VERSION ""

NS_ :

BS_:

BU_: ADCS_FD3 GW_FD2 BDCS CDCS GW_FD3 GW_FD4 GW_FD5 GW_FD6 GW_FD1 MCU FMCU EPS1 IDB1 ACU ICU TBOX IDB2 EPS2 RCU1 PDCU DDCU PLSD DLSD PDCS1 BTM GW_FD8 HNS2 HNS1 EMS BMS EDU RCU2

BO_ 143 ADCS_Fr11_08F_APA1: 32 ADCS_FD3
 SG_ ADCS11_PA_GearReq : 0|1@0+ (1,0) [0|1] "NoUnit" TBOX,GW_FD5,GW_FD1,PDCS1
 SG_ ADCS11_PA_GearPosReqVail : 1|1@0+ (1,0) [0|1] "NoUnit" TBOX,GW_FD5,GW_FD1,PDCS1
 SG_ ADCS11_PA_prefillReq : 2|1@0+ (1,0) [0|1] "NoUnit" TBOX,GW_FD8,GW_FD5,IDB1,IDB2,EPS2,RCU1
 SG_ ADCS11_PA_GearPosReq : 5|3@0+ (1,0) [0|7] "NoUnit" TBOX,GW_FD5,GW_FD1,PDCS1
 SG_ ADCS11_PA_BrakemodeReq : 7|2@0+ (1,0) [0|3] "NoUnit" TBOX,GW_FD8,GW_FD5,IDB1,IDB2,EPS2,RCU1
 SG_ ADCS11_PA_EpbReq : 17|2@0+ (1,0) [0|3] "NoUnit" TBOX,GW_FD8,GW_FD5,IDB1,IDB2,EPS2,RCU1
 SG_ ADCS11_PA_lampreq : 19|2@0+ (1,0) [0|3] "NoUnit" TBOX,GW_FD5,GW_FD2,BDCS
 SG_ ADCS11_PA_StopDistance : 15|12@0+ (0.01,0) [0|40.95] "m" TBOX,GW_FD8,GW_FD5,IDB1,IDB2,EPS2,RCU1
 SG_ ADCS11_PA_StopDistanceValid : 159|1@0+ (1,0) [0|1] "NoUnit" TBOX,GW_FD5,IDB1,RCU1
 SG_ ADCS11_Parking_WorkSts : 27|4@0+ (1,0) [0|15] "NoUnit" IDB1,EPS1,IDB2,EPS2,PDCS1,RCU1,BDCS,CDCS,TBOX,GW_FD8,GW_FD5,FMCU,GW_FD4,BTM,GW_FD1,ICU,GW_FD2,MCU
 SG_ ADCS11_PA_Recover : 29|1@0+ (1,0) [0|1] "NoUnit" IDB1,IDB2,EPS2,RCU1,CDCS,TBOX,GW_FD8,GW_FD5,GW_FD4,BTM,GW_FD2
 SG_ ADCS11_RPA_RemoteParkAppStartReq : 28|1@0+ (1,0) [0|1] "NoUnit" TBOX,GW_FD5,GW_FD4,BTM,GW_FD2,CDCS
 SG_ ADCS11_TurnLampReq : 31|2@0+ (1,0) [0|3] "NoUnit" TBOX,GW_FD5,BTM,GW_FD2
 SG_ ADCS11_SetPathwayWorkSts : 39|2@0+ (1,0) [0|3] "NoUnit" TBOX,GW_FD5,GW_FD4,CDCS
 SG_ ADCS11_PA_EPSAngleReq : 37|14@0+ (0.1,-720) [-720|720] "degree" TBOX,GW_FD8,GW_FD5,EPS1,EPS2
 SG_ ADCS11_HPAGuideSts : 54|3@0+ (1,0) [0|7] "NoUnit" TBOX,GW_FD5,GW_FD4,CDCS
 SG_ ADCS11_PA_IDBControlReq : 129|2@0+ (1,0) [0|3] "NoUnit" TBOX,GW_FD8,GW_FD5,IDB1,IDB2,EPS2,RCU1
 SG_ ADCS11_MsgCounter0 : 51|4@0+ (1,0) [0|15] "NoUnit" TBOX,GW_FD8,GW_FD5,IDB1,EPS1,EPS2,GW_FD1,PDCS1,RCU1
 SG_ ADCS11_Checksum0 : 63|8@0+ (1,0) [0|255] "NoUnit" TBOX,GW_FD8,GW_FD5,IDB1,EPS1,EPS2,GW_FD1,PDCS1,RCU1
 SG_ ADCS11_HPA_WorkSts : 74|3@0+ (1,0) [0|7] "NoUnit" TBOX,GW_FD5,GW_FD4,CDCS
 SG_ ADCS11_PA_IDBControlReqV : 75|1@0+ (1,0) [0|1] "NoUnit" TBOX,GW_FD8,GW_FD5,IDB1,IDB2,EPS2,RCU1
 SG_ ADCS11_PA_TarDecel : 71|12@0+ (0.01,-20.48) [-20.48|20.46] "m/s^2" TBOX,GW_FD8,GW_FD5,IDB1,IDB2,EPS2,GW_FD1,PDCS1,RCU1
 SG_ ADCS11_PA_EPSAngleReqSt : 96|1@0+ (1,0) [0|1] "NoUnit" TBOX,GW_FD8,GW_FD5,EPS1,EPS2
 SG_ ADCS11_PA_EPSAngleReqV : 97|1@0+ (1,0) [0|1] "NoUnit" TBOX,GW_FD8,GW_FD5,EPS1,EPS2
 SG_ ADCS11_PrkngFctnModeReq : 100|3@0+ (1,0) [0|7] "NoUnit" TBOX,GW_FD8,GW_FD5,EPS2
 SG_ ADCS11_HPAPathlearning_WorkSts : 103|3@0+ (1,0) [0|7] "NoUnit" TBOX,GW_FD5,GW_FD4,CDCS
 SG_ ADCS11_HPAPathwaytoCloud_WorkSts : 106|3@0+ (1,0) [0|7] "NoUnit" TBOX,GW_FD5,GW_FD4,CDCS
 SG_ ADCS11_TrackreverseWorkSts : 109|3@0+ (1,0) [0|7] "NoUnit" TBOX,GW_FD5,GW_FD4,CDCS
 SG_ ADCS11_Currentgear : 111|2@0+ (1,0) [0|3] "NoUnit" TBOX,GW_FD5,GW_FD4,BTM,GW_FD2,CDCS
 SG_ ADCS11_PA_PAMaxSpd : 119|16@0+ (0.015625,0) [0|512] "km/h" TBOX,GW_FD8,GW_FD5,IDB1,IDB2,EPS2,GW_FD1,PDCS1,RCU1
 SG_ ADCS11_PA_Pause_Recover : 137|2@0+ (1,0) [0|3] "NoUnit" TBOX,GW_FD5,GW_FD4,CDCS
 SG_ ADCS11_PA_ParkingFnMd : 143|2@0+ (1,0) [0|3] "NoUnit" TBOX,GW_FD5,IDB1,RCU1
 SG_ ADCS11_PA_TarDecelreq : 141|1@0+ (1,0) [0|1] "NoUnit" TBOX,GW_FD5,IDB1,RCU1
 SG_ ADCS11_HPA_BacktoEntrance : 138|1@0+ (1,0) [0|1] "NoUnit" TBOX,GW_FD5,GW_FD4,CDCS
 SG_ ADCS11_HPA_BacktoStart : 139|1@0+ (1,0) [0|1] "NoUnit" TBOX,GW_FD5,GW_FD4,CDCS
 SG_ ADCS11_PA_TorqReq : 134|1@0+ (1,0) [0|1] "NoUnit" TBOX,GW_FD5,GW_FD1,PDCS1
 SG_ ADCS11_PA_TorqReqValue : 156|13@0+ (1,-1023) [-1023|1023] "Nm" TBOX,GW_FD5,GW_FD1,PDCS1
 SG_ ADCS11_PA_TorqReqValidity : 135|1@0+ (1,0) [0|1] "NoUnit" TBOX,GW_FD5,GW_FD1,PDCS1
 SG_ ADCS11_PA_screenReq : 147|4@0+ (1,0) [0|15] "NoUnit" TBOX,GW_FD5,GW_FD4,CDCS
 SG_ ADCS11_APA_RemoteStartReq : 130|1@0+ (1,0) [0|1] "NoUnit" TBOX,GW_FD5,GW_FD2,BDCS
 SG_ ADCS11_APA_RemoteShutdownReq : 131|1@0+ (1,0) [0|1] "NoUnit" TBOX,GW_FD5,GW_FD2,BDCS
 SG_ ADCS11_MirrorFoldrequest : 133|2@0+ (1,0) [0|3] "NoUnit" TBOX,GW_FD5,GW_FD2,BDCS
 SG_ ADCS11_APA_FLWindowsCtrl : 87|3@0+ (1,0) [0|7] "NoUnit" TBOX,GW_FD5,GW_FD2,BDCS
 SG_ ADCS11_APA_RemoteLockCtrl : 84|2@0+ (1,0) [0|3] "NoUnit" TBOX,GW_FD5,GW_FD2,BDCS
 SG_ ADCS11_APA_FRWindowsCtrl : 82|3@0+ (1,0) [0|7] "NoUnit" TBOX,GW_FD5,GW_FD2,BDCS
 SG_ ADCS11_APA_RLWindowsCtrl : 95|3@0+ (1,0) [0|7] "NoUnit" TBOX,GW_FD5,GW_FD2,BDCS
 SG_ ADCS11_APA_RRWindowsCtrl : 92|3@0+ (1,0) [0|7] "NoUnit" TBOX,GW_FD5,GW_FD2,BDCS
 SG_ ADCS11_APA_requestMirrorFoldSt : 89|2@0+ (1,0) [0|3] "NoUnit" TBOX,GW_FD5,GW_FD2,BDCS
 SG_ ADCS11_PA_StopReq : 158|1@0+ (1,0) [0|1] "NoUnit" TBOX,GW_FD5,IDB1,GW_FD4,RCU1,CDCS
 SG_ ADCS11_HPA_PathlearningSt : 149|2@0+ (1,0) [0|3] "NoUnit" TBOX,GW_FD5,GW_FD4,CDCS
 SG_ ADCS11_HPA_Path_exist : 151|2@0+ (1,0) [0|3] "NoUnit" TBOX,GW_FD5,GW_FD4,CDCS
 SG_ ADCS11_HPA_Pathavailable_ID1 : 223|8@0+ (1,0) [0|255] "NoUnit" TBOX,GW_FD5,GW_FD4,CDCS
 SG_ ADCS11_HPA_Pathavailable_ID2 : 175|8@0+ (1,0) [0|255] "NoUnit" TBOX,GW_FD5,GW_FD4,CDCS
 SG_ ADCS11_HPA_distance : 183|12@0+ (1,0) [0|4095] "NoUnit" TBOX,GW_FD5,GW_FD4,CDCS
 SG_ ADCS11_Parkingtimeremaining : 185|10@0+ (1,0) [0|1023] "NoUnit" TBOX,GW_FD5,GW_FD4,CDCS
 SG_ ADCS11_PA_PickSt : 157|1@0+ (1,0) [0|1] "NoUnit" TBOX,GW_FD5
 SG_ ADCS11_NNS_distance : 207|16@0+ (1,0) [0|65535] "NoUnit" TBOX,GW_FD5,GW_FD4,CDCS
 SG_ ADCS11_PA_IDB_TorqReqValue : 243|12@0+ (0.5,-1023) [-1023|1023] "Nm" TBOX,GW_FD5,IDB1,RCU1
 SG_ ADCS11_HighBeam : 225|2@0+ (1,0) [0|3] "NoUnit" TBOX,GW_FD5,GW_FD2,BDCS
 SG_ ADCS11_LowBeam : 231|2@0+ (1,0) [0|3] "NoUnit" TBOX,GW_FD5,GW_FD2,BDCS
 SG_ ADCS11_ReqPwmode : 227|2@0+ (1,0) [0|3] "NoUnit" TBOX,GW_FD5,GW_FD2,BDCS
 SG_ ADCS11_SecuritySts : 229|2@0+ (1,0) [0|3] "NoUnit" TBOX,GW_FD5,GW_FD2,BDCS
 SG_ ADCS11_PA_IDB_TorqReqValidity : 244|1@0+ (1,0) [0|1] "NoUnit" TBOX,GW_FD5,IDB1,RCU1
 SG_ ADCS11_HPA_learnpathdistance : 239|10@0+ (1,0) [0|1023] "NoUnit" GW_FD4,CDCS

BO_ 142 ADCS_Fr02_08E: 16 ADCS_FD3
 SG_ ADCS2_ADAS_EPSAngleReqSt : 0|1@0+ (1,0) [0|1] "NoUnit" EPS1,EPS2
 SG_ ADCS2_EPS_LDPState : 3|3@0+ (1,0) [0|7] "NoUnit" EPS1,EPS2,ICU,CDCS
 SG_ ADCS2_NNP_SystemFaultStatus : 6|3@0+ (1,0) [0|7] "NoUnit" EPS1,GW_FD4,EPS2,CDCS
 SG_ ADCS2_ADAS_EPSLateralCtrlType : 14|4@0+ (1,0) [0|15] "NoUnit" EPS1,EPS2
 SG_ ADCS_Pilot_SystemFaultStatus : 10|3@0+ (1,0) [0|7] "NoUnit" EPS1,EPS2
 SG_ ADCS2_ADSDriving_mode : 31|2@0+ (1,0) [0|3] "NoUnit" GW_FD4,CDCS
 SG_ ADCS2_ADAS_EPSAngleReq : 29|14@0+ (0.1,-720) [-720|720] "degree" EPS1,EPS2
 SG_ ADCS2_ADAS_IHBCSysState : 42|3@0+ (1,0) [0|7] "NoUnit" PDCU,GW_FD4,ICU,GW_FD2,BDCS,DDCU,CDCS
 SG_ ADCS2_ALCDirection : 45|3@0+ (1,0) [0|7] "NoUnit" GW_FD4,ICU,GW_FD2,BDCS,CDCS
 SG_ ADCS2_MsgCounter0 : 51|4@0+ (1,0) [0|15] "NoUnit" HNS2,HNS1,EPS1,EPS2
 SG_ ADCS2_EPS_ELKState : 54|3@0+ (1,0) [0|7] "NoUnit" EPS1,GW_FD4,EPS2,ICU,CDCS
 SG_ ADCS2_Checksum0 : 63|8@0+ (1,0) [0|255] "NoUnit" HNS2,HNS1,EPS1,EPS2
 SG_ ADCS2_AEB_JerkReq : 79|1@0+ (1,0) [0|1] "NoUnit" IDB1,GW_FD4,IDB2,EPS2,RCU1,CDCS
 SG_ ADCS2_AEBPrefillReq : 78|1@0+ (1,0) [0|1] "NoUnit" IDB1,IDB2,EPS2,RCU1
 SG_ ADCS2_AEB_DBSLevel : 77|2@0+ (1,0) [0|3] "NoUnit" IDB1,IDB2,EPS2,RCU1
 SG_ ADCS2_AEBPartialBrake : 75|1@0+ (1,0) [0|1] "NoUnit" ACU,IDB1,GW_FD4,IDB2,EPS2,ICU,RCU1,CDCS
 SG_ ADCS2_AEBFullBrake : 74|1@0+ (1,0) [0|1] "NoUnit" ACU,IDB1,GW_FD4,IDB2,EPS2,GW_FD1,ICU,PDCS1,RCU1,CDCS
 SG_ ADCS2_AEBVehicleHoldReq : 73|1@0+ (1,0) [0|1] "NoUnit" IDB1,IDB2,EPS2,RCU1
 SG_ ADCS2_AEBTargetDeceleration : 87|8@0+ (0.1,-12.7) [-12.7|12.8] "m/s^2" IDB1,IDB2,EPS2,RCU1
 SG_ ADCS2_longitudCtrlType : 98|3@0+ (1,0) [0|7] "NoUnit" HNS2,HNS1,IDB1,IDB2,EPS2,RCU1
 SG_ ADCS2_LongitudCtrlDecToStopReq : 99|1@0+ (1,0) [0|1] "NoUnit" IDB1,IDB2,EPS2,RCU1
 SG_ ADCS2_LongitudCtrlDriveOff : 100|1@0+ (1,0) [0|1] "NoUnit" IDB1,IDB2,EPS2,RCU1
 SG_ ADCS2_AEB_JerkLevel : 102|2@0+ (1,0) [0|3] "NoUnit" IDB1,IDB2,EPS2,RCU1
 SG_ ADCS2_LongitudCtrlTargetAccel : 111|11@0+ (0.01,-10.23) [-10.23|10.24] "m/s^2" IDB1,IDB2,EPS2,RCU1
 SG_ ADCS2_LongitudCtrlAccelCtrlReq : 116|1@0+ (1,0) [0|1] "NoUnit" IDB1,IDB2,EPS2,GW_FD1,PDCS1,RCU1

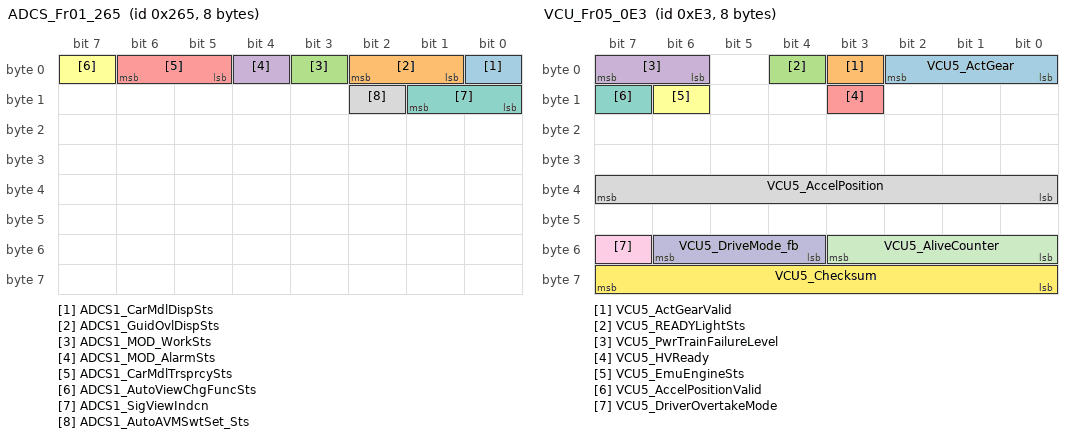
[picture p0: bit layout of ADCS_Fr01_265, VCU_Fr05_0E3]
BO_ 613 ADCS_Fr01_265: 8 ADCS_FD3
 SG_ ADCS1_CarMdlDispSts : 0|1@0+ (1,0) [0|1] "NoUnit" GW_FD4,CDCS
 SG_ ADCS1_GuidOvlDispSts : 2|2@0+ (1,0) [0|3] "NoUnit" GW_FD4,CDCS
 SG_ ADCS1_MOD_WorkSts : 3|1@0+ (1,0) [0|1] "NoUnit" GW_FD4,CDCS
 SG_ ADCS1_MOD_AlarmSts : 4|1@0+ (1,0) [0|1] "NoUnit" GW_FD4,CDCS
 SG_ ADCS1_CarMdlTrsprcySts : 6|2@0+ (1,0) [0|3] "NoUnit" GW_FD4,CDCS
 SG_ ADCS1_AutoViewChgFuncSts : 7|1@0+ (1,0) [0|1] "NoUnit" GW_FD4,CDCS
 SG_ ADCS1_SigViewIndcn : 9|2@0+ (1,0) [0|3] "NoUnit" GW_FD4,CDCS
 SG_ ADCS1_AutoAVMSwtSet_Sts : 10|1@0+ (1,0) [0|1] "NoUnit" GW_FD4,CDCS

BO_ 248 EMS_Fr02_0F8: 8 EMS
 SG_ EMS2_EngineSpeed : 4|13@0+ (1,0) [0|8191] "rpm" ADCS_FD3

BO_ 320 CDCS_Fr03_140: 16 CDCS
 SG_ CDCS3_ESCOffSw : 11|2@0+ (1,0) [0|3] "NoUnit" ADCS_FD3
 SG_ CDCS3_HDCSw : 19|2@0+ (1,0) [0|3] "NoUnit" ADCS_FD3
 SG_ CDCS3_DriveModeSet : 50|3@0+ (1,0) [0|7] "NoUnit" ADCS_FD3
 SG_ CDCS3_Xcoordinate : 79|16@0+ (1,0) [0|65534] "NoUnit" ADCS_FD3
 SG_ CDCS3_Ycoordinate : 95|16@0+ (1,0) [0|65534] "NoUnit" ADCS_FD3
 SG_ CDCS3_XGestureSpd : 111|8@0+ (1,0) [0|254] "NoUnit" ADCS_FD3
 SG_ CDCS3_YGestureSpd : 119|8@0+ (1,0) [0|254] "NoUnit" ADCS_FD3
 SG_ CDCS3_TouchEvtTyp : 123|4@0+ (1,0) [0|15] "NoUnit" ADCS_FD3

BO_ 559 EMS_Fr04_22F: 8 EMS
 SG_ EMS4_Throttleposition : 31|10@0+ (0.1,0) [0|100] "NoUnit" ADCS_FD3

BO_ 418 DDCU_Fr01_1A2: 16 DDCU
 SG_ DDCU1_FL_WinPos : 15|8@0+ (1,0) [0|100] "%" ADCS_FD3
 SG_ DDCU1_RL_WinPos : 23|8@0+ (1,0) [0|100] "%" ADCS_FD3
 SG_ DDCU1_FLDoorAjar : 25|2@0+ (1,0) [0|3] "NoUnit" ADCS_FD3
 SG_ DDCU1_RLDoorAjar : 27|2@0+ (1,0) [0|3] "NoUnit" ADCS_FD3
 SG_ DDCU1_MirrorFoldSt : 29|1@0+ (1,0) [0|1] "NoUnit" ADCS_FD3
 SG_ DDCU1_FL_LockSt : 73|2@0+ (1,0) [0|3] "NoUnit" ADCS_FD3
 SG_ DDCU1_RL_LockSt : 75|2@0+ (1,0) [0|3] "NoUnit" ADCS_FD3

BO_ 419 PDCU_Fr01_1A3: 16 PDCU
 SG_ PDCU1_FR_WinPos : 15|8@0+ (1,0) [0|100] "%" ADCS_FD3
 SG_ PDCU1_RR_WinPos : 23|8@0+ (1,0) [0|100] "%" ADCS_FD3
 SG_ PDCU1_FRDoorAjar : 25|2@0+ (1,0) [0|3] "NoUnit" ADCS_FD3
 SG_ PDCU1_RRDoorAjar : 27|2@0+ (1,0) [0|3] "NoUnit" ADCS_FD3
 SG_ PDCU1_FR_LockSt : 73|2@0+ (1,0) [0|3] "NoUnit" ADCS_FD3
 SG_ PDCU1_RR_LockSt : 75|2@0+ (1,0) [0|3] "NoUnit" ADCS_FD3

BO_ 468 CDCS_FR05_1D4: 32 CDCS
 SG_ CDCS5_ResetAllSetup : 0|1@0+ (1,0) [0|1] "NoUnit" ADCS_FD3
 SG_ CDCS5_FactoryReset : 1|1@0+ (1,0) [0|1] "NoUnit" ADCS_FD3

BO_ 482 BDCS_Fr04_1E2: 8 BDCS
 SG_ BDCS4_Ftyre_Status : 0|1@0+ (1,0) [0|1] "NoUnit" ADCS_FD3
 SG_ BDCS4_FLTyre_LearntSt : 1|1@0+ (1,0) [0|1] "NoUnit" ADCS_FD3
 SG_ BDCS4_FLTyre_PressureWarn : 3|2@0+ (1,0) [0|3] "NoUnit" ADCS_FD3
 SG_ BDCS4_FLTyre_TemperatureWarn : 4|1@0+ (1,0) [0|1] "NoUnit" ADCS_FD3
 SG_ BDCS4_FLTyre_QucikLeak : 5|1@0+ (1,0) [0|1] "NoUnit" ADCS_FD3
 SG_ BDCS4_FLTyre_SensorFailure : 6|1@0+ (1,0) [0|1] "NoUnit" ADCS_FD3
 SG_ BDCS4_FLTyre_LowBattery : 7|1@0+ (1,0) [0|1] "NoUnit" ADCS_FD3
 SG_ BDCS4_FLTyre_Pressure : 15|8@0+ (3.137,0) [0|796.798] "kpa" ADCS_FD3
 SG_ BDCS4_FLTyre_Temperature : 23|8@0+ (1,-50) [-50|204] "" ADCS_FD3
 SG_ BDCS4_FRTyre_LearntSt : 25|1@0+ (1,0) [0|1] "NoUnit" ADCS_FD3
 SG_ BDCS4_FRTyre_PressureWarn : 27|2@0+ (1,0) [0|3] "NoUnit" ADCS_FD3
 SG_ BDCS4_FRTyre_TemperatureWarn : 28|1@0+ (1,0) [0|1] "NoUnit" ADCS_FD3
 SG_ BDCS4_FRTyre_QucikLeak : 29|1@0+ (1,0) [0|1] "NoUnit" ADCS_FD3
 SG_ BDCS4_FRTyre_SensorFailure : 30|1@0+ (1,0) [0|1] "NoUnit" ADCS_FD3
 SG_ BDCS4_FRTyre_LowBattery : 31|1@0+ (1,0) [0|1] "NoUnit" ADCS_FD3
 SG_ BDCS4_FRTyre_Pressure : 39|8@0+ (3.137,0) [0|796.798] "kpa" ADCS_FD3
 SG_ BDCS4_FRTyre_Temperature : 47|8@0+ (1,-50) [-50|204] "" ADCS_FD3
 SG_ BDCS4_Testmode : 53|1@0+ (1,0) [0|1] "NoUnit" ADCS_FD3
 SG_ BDCS4_SystemFailure : 55|2@0+ (1,0) [0|3] "NoUnit" ADCS_FD3

BO_ 484 BDCS_Fr05_1E4: 8 BDCS
 SG_ BDCS5_Rtyre_Status : 0|1@0+ (1,0) [0|1] "NoUnit" ADCS_FD3
 SG_ BDCS5_RLTyre_LearntSt : 1|1@0+ (1,0) [0|1] "NoUnit" ADCS_FD3
 SG_ BDCS5_RLTyre_PressureWarn : 3|2@0+ (1,0) [0|3] "NoUnit" ADCS_FD3
 SG_ BDCS5_RLTyre_TemperatureWarn : 4|1@0+ (1,0) [0|1] "NoUnit" ADCS_FD3
 SG_ BDCS5_RLTyre_QucikLeak : 5|1@0+ (1,0) [0|1] "NoUnit" ADCS_FD3
 SG_ BDCS5_RLTyre_SensorFailure : 6|1@0+ (1,0) [0|1] "NoUnit" ADCS_FD3
 SG_ BDCS5_RLTyre_LowBattery : 7|1@0+ (1,0) [0|1] "NoUnit" ADCS_FD3
 SG_ BDCS5_RLTyre_Pressure : 15|8@0+ (3.137,0) [0|796.798] "kpa" ADCS_FD3
 SG_ BDCS5_RLTyre_Temperature : 23|8@0+ (1,-50) [-50|204] "" ADCS_FD3
 SG_ BDCS5_RRTyre_LearntSt : 25|1@0+ (1,0) [0|1] "NoUnit" ADCS_FD3
 SG_ BDCS5_RRTyre_PressureWarn : 27|2@0+ (1,0) [0|3] "NoUnit" ADCS_FD3
 SG_ BDCS5_RRTyre_TemperatureWarn : 28|1@0+ (1,0) [0|1] "NoUnit" ADCS_FD3
 SG_ BDCS5_RRTyre_QucikLeak : 29|1@0+ (1,0) [0|1] "NoUnit" ADCS_FD3
 SG_ BDCS5_RRTyre_SensorFailure : 30|1@0+ (1,0) [0|1] "NoUnit" ADCS_FD3
 SG_ BDCS5_RRTyre_LowBattery : 31|1@0+ (1,0) [0|1] "NoUnit" ADCS_FD3
 SG_ BDCS5_RRTyre_Pressure : 39|8@0+ (3.137,0) [0|796.798] "kpa" ADCS_FD3
 SG_ BDCS5_RRTyre_Temperature : 47|8@0+ (1,-50) [-50|204] "" ADCS_FD3

BO_ 486 BDCS_Fr06_1E6: 16 BDCS
 SG_ BDCS6_FrontWiperSts : 18|3@0+ (1,0) [0|7] "NoUnit" ADCS_FD3
 SG_ BDCS6_FrontWiperParkPos : 15|1@0+ (1,0) [0|1] "NoUnit" ADCS_FD3
 SG_ BDCS6_DayNightMode : 93|2@0+ (1,0) [0|3] "NoUnit" ADCS_FD3

BO_ 756 BTM_Fr02_2F4: 8 BTM
 SG_ BTM2_ConnectSts : 6|2@0+ (1,0) [0|3] "NoUnit" ADCS_FD3
 SG_ BTM2_Key_Position : 18|3@0+ (1,0) [0|7] "NoUnit" ADCS_FD3

BO_ 243 BTM_Fr01_0F3: 32 BTM
 SG_ BTM1_SecuritySts : 3|4@0+ (1,0) [0|15] "NoUnit" ADCS_FD3
 SG_ BTM1_PhoneBatSts : 15|1@0+ (1,0) [0|1] "NoUnit" ADCS_FD3
 SG_ BTM1_RemoteIntModSel : 22|2@0+ (1,0) [0|3] "NoUnit" ADCS_FD3
 SG_ BTM1_SelectSlotID : 27|4@0+ (1,0) [0|15] "NoUnit" ADCS_FD3
 SG_ BTM1_Retry : 29|2@0+ (1,0) [0|3] "NoUnit" ADCS_FD3
 SG_ BTM1_Fixslot : 31|2@0+ (1,0) [0|3] "NoUnit" ADCS_FD3
 SG_ BTM1_ParkingReq : 38|2@0+ (1,0) [0|3] "NoUnit" ADCS_FD3
 SG_ BTM1_Recover : 36|1@0+ (1,0) [0|1] "NoUnit" ADCS_FD3
 SG_ BTM1_parkingoutSlotType : 35|2@0+ (1,0) [0|3] "NoUnit" ADCS_FD3
 SG_ BTM1_parkingoutSlot_Dire : 33|2@0+ (1,0) [0|3] "NoUnit" ADCS_FD3
 SG_ BTM1_OptionalSlotType : 47|2@0+ (1,0) [0|3] "NoUnit" ADCS_FD3
 SG_ BTM1_OptionalSlot_Dire : 45|3@0+ (1,0) [0|7] "NoUnit" ADCS_FD3
 SG_ BTM1_FunctionMode : 42|3@0+ (1,0) [0|7] "NoUnit" ADCS_FD3
 SG_ BTM1_RemoteParkReq : 53|2@0+ (1,0) [0|3] "NoUnit" ADCS_FD3
 SG_ BTM1_Movectrl : 55|2@0+ (1,0) [0|3] "NoUnit" ADCS_FD3
 SG_ BTM1_RollingCounter : 51|4@0+ (1,0) [0|15] "NoUnit" ADCS_FD3
 SG_ BTM1_Checksum : 63|8@0+ (1,0) [0|255] "NoUnit" ADCS_FD3
 SG_ BTM1_OptionalSlotAngle : 70|15@0+ (0.001,0) [0|32.767] "rad" ADCS_FD3
 SG_ BTM1_OptionalSlotCoor_P0_X : 85|14@0+ (1,0) [0|16383] "NoUnit" ADCS_FD3
 SG_ BTM1_OptionalSlotCoor_P0_Y : 101|14@0+ (1,0) [0|16383] "NoUnit" ADCS_FD3
 SG_ BTM1_OptionalSlotCoor_P1_X : 117|14@0+ (1,0) [0|16383] "NoUnit" ADCS_FD3
 SG_ BTM1_OptionalSlotCoor_P1_Y : 133|14@0+ (1,0) [0|16383] "NoUnit" ADCS_FD3
 SG_ BTM1_OptionalSlotCoor_P2_X : 149|14@0+ (1,0) [0|16383] "NoUnit" ADCS_FD3
 SG_ BTM1_OptionalSlotCoor_P2_Y : 165|14@0+ (1,0) [0|16383] "NoUnit" ADCS_FD3
 SG_ BTM1_OptionalSlotCoor_P3_X : 181|14@0+ (1,0) [0|16383] "NoUnit" ADCS_FD3
 SG_ BTM1_OptionalSlotCoor_P3_Y : 197|14@0+ (1,0) [0|16383] "NoUnit" ADCS_FD3

BO_ 498 BTM_Fr03_1F2: 8 BTM
 SG_ BTM3_RKECmd : 7|4@0+ (1,0) [0|15] "NoUnit" ADCS_FD3

BO_ 227 VCU_Fr05_0E3: 8 PDCS1
 SG_ VCU5_ActGear : 2|3@0+ (1,0) [0|7] "NoUnit" ADCS_FD3
 SG_ VCU5_ActGearValid : 3|1@0+ (1,0) [0|1] "NoUnit" ADCS_FD3
 SG_ VCU5_READYLightSts : 4|1@0+ (1,0) [0|1] "NoUnit" ADCS_FD3
 SG_ VCU5_PwrTrainFailureLevel : 7|2@0+ (1,0) [0|3] "NoUnit" ADCS_FD3
 SG_ VCU5_HVReady : 11|1@0+ (1,0) [0|1] "NoUnit" ADCS_FD3
 SG_ VCU5_EmuEngineSts : 14|1@0+ (1,0) [0|1] "NoUnit" ADCS_FD3
 SG_ VCU5_AccelPositionValid : 15|1@0+ (1,0) [0|1] "NoUnit" ADCS_FD3
 SG_ VCU5_AccelPosition : 39|8@0+ (1,0) [0|100] "%" ADCS_FD3
 SG_ VCU5_DriverOvertakeMode : 55|1@0+ (1,0) [0|1] "NoUnit" ADCS_FD3
 SG_ VCU5_DriveMode_fb : 54|3@0+ (1,0) [0|7] "NoUnit" ADCS_FD3
 SG_ VCU5_AliveCounter : 51|4@0+ (1,0) [0|15] "NoUnit" ADCS_FD3
 SG_ VCU5_Checksum : 63|8@0+ (1,0) [0|255] "NoUnit" ADCS_FD3

BO_ 739 VCU_Fr03_2E3: 8 PDCS1
 SG_ VCU3_EPBBackupCtrlActv : 4|1@0+ (1,0) [0|1] "" ADCS_FD3
 SG_ VCU3_EPBBackupCtrlSts : 37|3@0+ (1,0) [0|7] "NoUnit" ADCS_FD3

BO_ 724 VCU_Fr04_2D4: 32 PDCS1
 SG_ VCU4_CCS_Status : 23|4@0+ (1,0) [0|15] "NoUnit" ADCS_FD3

BO_ 251 VCU_Fr06_0FB: 16 PDCS1
 SG_ VCU6_SystemWarnLightSts : 26|1@0+ (1,0) [0|1] "NoUnit" ADCS_FD3
 SG_ VCU6_StrtgyGear : 66|3@0+ (1,0) [0|7] "NoUnit" ADCS_FD3

BO_ 252 VCU_Fr07_0FC: 32 PDCS1
 SG_ VCU7_MaxMotPosTq : 23|16@0+ (0.05,0) [0|350] "Nm" ADCS_FD3
 SG_ VCU7_MaxMotGenTq : 39|16@0+ (0.05,0) [0|350] "Nm" ADCS_FD3
 SG_ VCU7_MaxFMotPosTq : 87|16@0+ (0.05,0) [0|350] "Nm" ADCS_FD3
 SG_ VCU7_MaxFMotGenTq : 103|16@0+ (0.05,0) [0|350] "Nm" ADCS_FD3

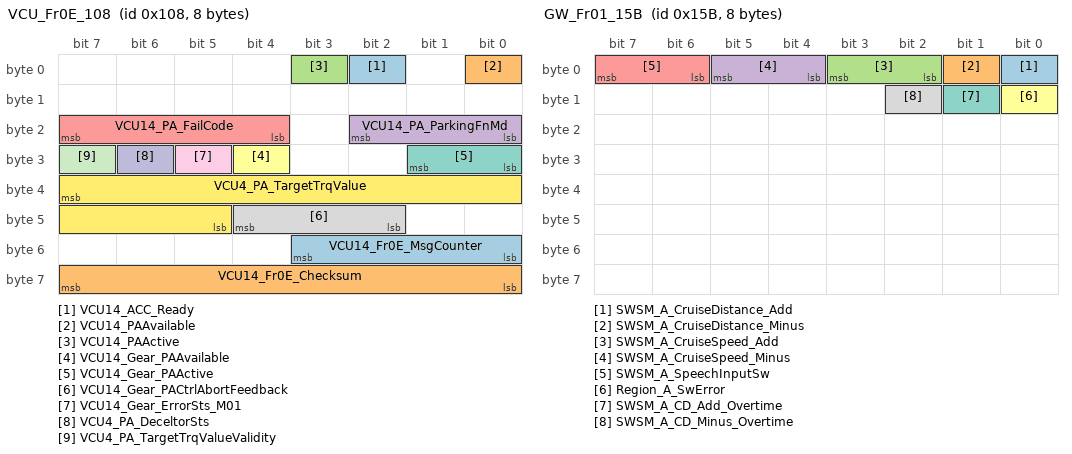
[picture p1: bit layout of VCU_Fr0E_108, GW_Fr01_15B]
BO_ 264 VCU_Fr0E_108: 8 PDCS1
 SG_ VCU14_ACC_Ready : 2|1@0+ (1,0) [0|1] "NoUnit" ADCS_FD3
 SG_ VCU14_PAAvailable : 0|1@0+ (1,0) [0|1] "NoUnit" ADCS_FD3
 SG_ VCU14_PAActive : 3|1@0+ (1,0) [0|1] "NoUnit" ADCS_FD3
 SG_ VCU14_PA_ParkingFnMd : 18|3@0+ (1,0) [0|7] "NoUnit" ADCS_FD3
 SG_ VCU14_PA_FailCode : 23|4@0+ (1,0) [0|15] "NoUnit" ADCS_FD3
 SG_ VCU14_Gear_PAAvailable : 28|1@0+ (1,0) [0|1] "NoUnit" ADCS_FD3
 SG_ VCU14_Gear_PAActive : 25|2@0+ (1,0) [0|3] "NoUnit" ADCS_FD3
 SG_ VCU14_Gear_PACtrlAbortFeedback : 44|3@0+ (1,0) [0|7] "NoUnit" ADCS_FD3
 SG_ VCU14_Gear_ErrorSts_M01 : 29|1@0+ (1,0) [0|1] "NoUnit" ADCS_FD3
 SG_ VCU4_PA_DeceltorSts : 30|1@0+ (1,0) [0|1] "NoUnit" ADCS_FD3
 SG_ VCU4_PA_TargetTrqValueValidity : 31|1@0+ (1,0) [0|1] "NoUnit" ADCS_FD3
 SG_ VCU4_PA_TargetTrqValue : 39|11@0+ (0.5,-400) [400|400] "Nm" ADCS_FD3
 SG_ VCU14_Fr0E_MsgCounter : 51|4@0+ (1,0) [0|15] "NoUnit" ADCS_FD3
 SG_ VCU14_Fr0E_Checksum : 63|8@0+ (1,0) [0|255] "NoUnit" ADCS_FD3

BO_ 438 TBOX_Fr02_1B6: 32 TBOX
 SG_ TBOX2_AVMOnReq : 1|2@0+ (1,0) [0|3] "NoUnit" ADCS_FD3
 SG_ TBOX2_RemoteParkStartPressReqSts : 2|1@0+ (1,0) [0|1] "NoUnit" ADCS_FD3
 SG_ TBOX2_RemoteHPP : 3|1@0+ (1,0) [0|1] "NoUnit" ADCS_FD3
 SG_ TBOX2_AVMviewReq : 7|4@0+ (1,0) [0|15] "NoUnit" ADCS_FD3
 SG_ TBOX2_RemoteParkReq : 8|1@0+ (1,0) [0|1] "NoUnit" ADCS_FD3
 SG_ TBOX2_SecuritySts : 10|2@0+ (1,0) [0|3] "NoUnit" ADCS_FD3
 SG_ TBOX2_ConnectSts : 12|2@0+ (1,0) [0|3] "NoUnit" ADCS_FD3
 SG_ TBOX2_PhoneInCar : 14|2@0+ (1,0) [0|3] "NoUnit" ADCS_FD3
 SG_ TBOX2_RemoteParkAbortReq : 15|1@0+ (1,0) [0|1] "NoUnit" ADCS_FD3
 SG_ TBOX2_RemoteParkStartPressReq : 16|1@0+ (1,0) [0|1] "NoUnit" ADCS_FD3
 SG_ TBOX2_RemoteParkOutModSel : 19|3@0+ (1,0) [0|7] "NoUnit" ADCS_FD3
 SG_ TBOX2_PhoneBatSts : 20|1@0+ (1,0) [0|1] "NoUnit" ADCS_FD3
 SG_ TBOX2_RemoteIntModSel : 22|2@0+ (1,0) [0|3] "NoUnit" ADCS_FD3
 SG_ TBOX2_RemoteSw : 23|1@0+ (1,0) [0|1] "NoUnit" ADCS_FD3
 SG_ TBOX2_RemoteCtrModSel : 26|3@0+ (1,0) [0|7] "NoUnit" ADCS_FD3
 SG_ TBOX2_RemoteCtrSw : 27|1@0+ (1,0) [0|1] "NoUnit" ADCS_FD3
 SG_ TBOX2_PA_PauseRecover_Req : 41|2@0+ (1,0) [0|3] "NoUnit" ADCS_FD3
 SG_ TBOX2_RollingCounter : 51|4@0+ (1,0) [0|15] "NoUnit" ADCS_FD3
 SG_ TBOX2_Checksum : 63|8@0+ (1,0) [0|255] "NoUnit" ADCS_FD3
 SG_ TBOX2_GMOnreq : 185|2@0+ (1,0) [0|3] "NoUnit" ADCS_FD3
 SG_ TBOX2_360viewReq : 187|2@0+ (1,0) [0|3] "NoUnit" ADCS_FD3
 SG_ TBOX2_360SpecView : 190|3@0+ (1,0) [0|7] "NoUnit" ADCS_FD3
 SG_ TBOX2_RemoteVhpower : 33|2@0+ (1,0) [0|3] "NoUnit" ADCS_FD3
 SG_ TBOX2_NRPReq : 35|2@0+ (1,0) [0|3] "NoUnit" ADCS_FD3
 SG_ TBOX2_SDMapReq : 37|2@0+ (1,0) [0|3] "NoUnit" ADCS_FD3
 SG_ TBOX2_NNSSW : 39|2@0+ (1,0) [0|3] "NoUnit" ADCS_FD3
 SG_ TBOX2_Remotepick : 28|1@0+ (1,0) [0|1] "NoUnit" ADCS_FD3
 SG_ TBOX2_NNSsuspend : 30|2@0+ (1,0) [0|3] "NoUnit" ADCS_FD3
 SG_ TBOX2_HPA_ONPath_ID : 87|8@0+ (1,0) [0|255] "" ADCS_FD3
 SG_ TBOX2_HPA_PickPath_ID : 95|8@0+ (1,0) [0|255] "" ADCS_FD3

BO_ 670 BDCS_Fr10_29E: 8 BDCS
 SG_ BDCS10_AC_OutsideTempValid : 33|1@0+ (1,0) [0|1] "NoUnit" ADCS_FD3
 SG_ BDCS10_AC_OutsideTemp : 47|8@0+ (0.5,-50) [-50|75] "" ADCS_FD3

BO_ 645 BDCS_Fr13_LIN2_285: 8 BDCS
 SG_ BDCS13_RLS_RQ_WiperSPD : 14|2@0+ (1,0) [0|3] "NoUnit" ADCS_FD3

BO_ 600 BMS_Fr03_258: 8 BMS
 SG_ BMS3_StateOfCharge : 7|16@0+ (0.1,0) [0|100] "NoUnit" ADCS_FD3
 SG_ BMS3_Charge_State : 59|4@0+ (1,0) [0|15] "NoUnit" ADCS_FD3

BO_ 501 CDCS_Fr11_1F5: 64 CDCS
 SG_ CDCS11_LKSSetspeed : 7|8@0+ (1,0) [0|255] "Km/h" ADCS_FD3
 SG_ CDCS11_LDW_OnOffSet : 9|2@0+ (1,0) [0|3] "NoUnit" ADCS_FD3
 SG_ CDCS11_LowSpeedBSDSw : 11|2@0+ (1,0) [0|3] "NoUnit" ADCS_FD3
 SG_ CDCS11_FCW_OnOffSet : 13|2@0+ (1,0) [0|3] "NoUnit" ADCS_FD3
 SG_ CDCS11_AEB_OnOffSet : 15|2@0+ (1,0) [0|3] "NoUnit" ADCS_FD3
 SG_ CDCS11_FCW_WarnTiming : 17|2@0+ (1,0) [0|3] "NoUnit" ADCS_FD3
 SG_ CDCS11_FCTA_OnOffSet : 19|2@0+ (1,0) [0|3] "NoUnit" ADCS_FD3
 SG_ CDCS11_RCTA_OnOffSet : 21|2@0+ (1,0) [0|3] "NoUnit" ADCS_FD3
 SG_ CDCS11_RCW_OnOffSet : 23|2@0+ (1,0) [0|3] "NoUnit" ADCS_FD3
 SG_ CDCS11_DOW_OnOffSet : 25|2@0+ (1,0) [0|3] "NoUnit" ADCS_FD3
 SG_ CDCS11_IHBC_SysSwState : 27|2@0+ (1,0) [0|3] "NoUnit" ADCS_FD3
 SG_ CDCS11_LCA_OnOffSet : 29|2@0+ (1,0) [0|3] "NoUnit" ADCS_FD3
 SG_ CDCS11_TSR_OnOffSet : 31|2@0+ (1,0) [0|3] "NoUnit" ADCS_FD3
 SG_ CDCS11_AVM_3DRotate : 33|2@0+ (1,0) [0|3] "NoUnit" ADCS_FD3
 SG_ CDCS11_AVM_Turnlightstart : 35|2@0+ (1,0) [0|3] "NoUnit" ADCS_FD3
 SG_ CDCS11_AVM_Steeringstart : 37|2@0+ (1,0) [0|3] "NoUnit" ADCS_FD3
 SG_ CDCS11_AVM_Magnifiedview : 39|2@0+ (1,0) [0|3] "NoUnit" ADCS_FD3
 SG_ CDCS11_AVM_MODdetection : 43|2@0+ (1,0) [0|3] "NoUnit" ADCS_FD3
 SG_ CDCS11_GM_OnOffSet : 45|2@0+ (1,0) [0|3] "NoUnit" ADCS_FD3
 SG_ CDCS11_NNP_OnOffSet : 47|2@0+ (1,0) [0|3] "NoUnit" ADCS_FD3
 SG_ CDCS11_DCLCSysState : 49|2@0+ (1,0) [0|3] "NoUnit" ADCS_FD3
 SG_ CDCS11_ALCSysState : 51|2@0+ (1,0) [0|3] "NoUnit" ADCS_FD3
 SG_ CDCS11_DriveOffPossilbeswitch : 53|2@0+ (1,0) [0|3] "NoUnit" ADCS_FD3
 SG_ CDCS11_DriveOffinhibitionswitch : 55|2@0+ (1,0) [0|3] "NoUnit" ADCS_FD3
 SG_ CDCS11_ADAS_SndCtrlOnOff : 57|2@0+ (1,0) [0|3] "NoUnit" ADCS_FD3
 SG_ CDCS11_AVM_auxiliaryline : 59|2@0+ (1,0) [0|3] "NoUnit" ADCS_FD3
 SG_ CDCS11_AVM_Raderdisplay : 61|2@0+ (1,0) [0|3] "NoUnit" ADCS_FD3
 SG_ CDCS11_AVM_Transparentchassis : 63|2@0+ (1,0) [0|3] "NoUnit" ADCS_FD3
 SG_ CDCS11_VoiceMode : 65|2@0+ (1,0) [0|3] "NoUnit" ADCS_FD3
 SG_ CDCS11_NNP_Active_OnOffSet : 67|2@0+ (1,0) [0|3] "NoUnit" ADCS_FD3
 SG_ CDCS11_ALC_mode : 69|2@0+ (1,0) [0|3] "NoUnit" ADCS_FD3
 SG_ CDCS11_ADSDriving_mode : 71|2@0+ (1,0) [0|3] "NoUnit" ADCS_FD3
 SG_ CDCS11_TSR_OverspeedOnoffSet : 73|2@0+ (1,0) [0|3] "NoUnit" ADCS_FD3
 SG_ CDCS11_NNP_AutoOnOffSet : 75|2@0+ (1,0) [0|3] "NoUnit" ADCS_FD3
 SG_ CDCS11_SnCtrl_NNP_OnOff : 77|2@0+ (1,0) [0|3] "NoUnit" ADCS_FD3
 SG_ CDCS11_GM_VidedIn : 79|2@0+ (1,0) [0|3] "NoUnit" ADCS_FD3
 SG_ CDCS11_TSR_SLFOnOffSet : 81|2@0+ (1,0) [0|3] "NoUnit" ADCS_FD3
 SG_ CDCS11_APA_FunctionMode : 85|4@0+ (1,0) [0|15] "NoUnit" ADCS_FD3
 SG_ CDCS11_TrackreverseSW : 87|2@0+ (1,0) [0|3] "NoUnit" ADCS_FD3
 SG_ CDCS11_SetPathwaySW : 89|2@0+ (1,0) [0|3] "NoUnit" ADCS_FD3
 SG_ CDCS11_PA_changeLanguage : 91|2@0+ (1,0) [0|3] "NoUnit" ADCS_FD3
 SG_ CDCS11_LDP_OnOffSet : 93|2@0+ (1,0) [0|3] "NoUnit" ADCS_FD3
 SG_ CDCS11_AVMSw : 95|2@0+ (1,0) [0|3] "NoUnit" ADCS_FD3
 SG_ CDCS11_tryHPP : 96|1@0+ (1,0) [0|1] "NoUnit" ADCS_FD3
 SG_ CDCS11_RPASw : 99|2@0+ (1,0) [0|3] "NoUnit" ADCS_FD3
 SG_ CDCS11_SetSw : 100|1@0+ (1,0) [0|1] "NoUnit" ADCS_FD3
 SG_ CDCS11_SoundCtrlSetReq : 103|3@0+ (1,0) [0|7] "NoUnit" ADCS_FD3
 SG_ CDCS11_location_sw : 104|1@0+ (1,0) [0|1] "NoUnit" ADCS_FD3
 SG_ CDCS11_Pathrefresh : 105|1@0+ (1,0) [0|1] "NoUnit" ADCS_FD3
 SG_ CDCS11_HPAGuideSW : 107|2@0+ (1,0) [0|3] "NoUnit" ADCS_FD3
 SG_ CDCS11_HPAPathwaytoCloudSW : 109|2@0+ (1,0) [0|3] "NoUnit" ADCS_FD3
 SG_ CDCS11_PathlearningSw : 111|2@0+ (1,0) [0|3] "NoUnit" ADCS_FD3
 SG_ CDCS11_PA_screenMd : 115|4@0+ (1,0) [0|15] "NoUnit" ADCS_FD3
 SG_ CDCS11_PASw : 118|3@0+ (1,0) [0|7] "NoUnit" ADCS_FD3
 SG_ CDCS11_PA_Recover : 119|1@0+ (1,0) [0|1] "NoUnit" ADCS_FD3
 SG_ CDCS_Lcsndrequest : 121|2@0+ (1,0) [0|3] "NoUnit" ADCS_FD3
 SG_ CDCS_Lcsndconfirm : 123|2@0+ (1,0) [0|3] "NoUnit" ADCS_FD3
 SG_ CDCS_SpdAdaptComfirm : 125|2@0+ (1,0) [0|3] "NoUnit" ADCS_FD3
 SG_ CDCS_PayModeConfirm : 127|2@0+ (1,0) [0|3] "NoUnit" ADCS_FD3
 SG_ CDCS11_SelectSlotID : 131|4@0+ (1,0) [0|15] "NoUnit" ADCS_FD3
 SG_ CDCS11_ParkingInReq : 133|2@0+ (1,0) [0|3] "NoUnit" ADCS_FD3
 SG_ CDCS11_ParkingOutReq : 135|2@0+ (1,0) [0|3] "NoUnit" ADCS_FD3
 SG_ CDCS11_AVM_ViewMode : 137|2@0+ (1,0) [0|3] "NoUnit" ADCS_FD3
 SG_ CDCS11_RPA_FunctionMode : 139|2@0+ (1,0) [0|3] "NoUnit" ADCS_FD3
 SG_ CDCS11_AVM_VideoOutputFail : 140|1@0+ (1,0) [0|1] "NoUnit" ADCS_FD3
 SG_ CDCS11_AVM_Initialization : 141|1@0+ (1,0) [0|1] "NoUnit" ADCS_FD3
 SG_ CDCS11_AVM_bodySync : 143|2@0+ (1,0) [0|3] "NoUnit" ADCS_FD3
 SG_ CDCS11_AVM_SpeView : 151|2@0+ (1,0) [0|3] "NoUnit" ADCS_FD3
 SG_ CDCS11_AVM_licenseplateabbr : 149|6@0+ (1,0) [0|63] "NoUnit" ADCS_FD3
 SG_ CDCS11_AVM_licenseplateArea : 156|5@0+ (1,0) [0|31] "NoUnit" ADCS_FD3
 SG_ CDCS11_AVM_StartMode : 159|3@0+ (1,0) [0|7] "NoUnit" ADCS_FD3
 SG_ CDCS11_AVM_LicensePlateNO1 : 165|6@0+ (1,0) [0|63] "NoUnit" ADCS_FD3
 SG_ CDCS11_ELK_OnOffSet : 167|2@0+ (1,0) [0|3] "NoUnit" ADCS_FD3
 SG_ CDCS11_AVM_LicensePlateNO2 : 173|6@0+ (1,0) [0|63] "NoUnit" ADCS_FD3
 SG_ CDCS11_AVM_LicensePlateNO3 : 181|6@0+ (1,0) [0|63] "NoUnit" ADCS_FD3
 SG_ CDCS11_DCWposition : 183|2@0+ (1,0) [0|3] "NoUnit" ADCS_FD3
 SG_ CDCS11_AVM_LicensePlateNO4 : 189|6@0+ (1,0) [0|63] "NoUnit" ADCS_FD3
 SG_ CDCS11_FindCarAvmReq : 199|2@0+ (1,0) [0|3] "NoUnit" ADCS_FD3
 SG_ CDCS11_AVM_LicensePlateNO5 : 197|6@0+ (1,0) [0|63] "NoUnit" ADCS_FD3
 SG_ CDCS11_AVM_LicensePlateNO6 : 205|6@0+ (1,0) [0|63] "NoUnit" ADCS_FD3
 SG_ CDCS11_AVM_LicensePlateNO7 : 213|6@0+ (1,0) [0|63] "NoUnit" ADCS_FD3
 SG_ CDCS11_AVM_LicensePlateNO8 : 221|6@0+ (1,0) [0|63] "NoUnit" ADCS_FD3
 SG_ CDCS11_AVM_Powertype : 223|2@0+ (1,0) [0|3] "NoUnit" ADCS_FD3
 SG_ CDCS11_AVM_Diaphaneity : 227|4@0+ (1,0) [0|15] "NoUnit" ADCS_FD3
 SG_ CDCS11_AVM_DiaphaneitySw : 228|1@0+ (1,0) [0|1] "NoUnit" ADCS_FD3
 SG_ CDCS11_MOD_Sound_Sw : 233|2@0+ (1,0) [0|3] "NoUnit" ADCS_FD3
 SG_ CDCS11_MOD_BSD_Sw : 235|2@0+ (1,0) [0|3] "NoUnit" ADCS_FD3
 SG_ CDCS11_PA_FRS_OnOffSet : 237|2@0+ (1,0) [0|3] "NoUnit" ADCS_FD3
 SG_ CDCS11_PA_3D_OnOffSet : 239|2@0+ (1,0) [0|3] "NoUnit" ADCS_FD3
 SG_ CDCS11_PA_measure_OnOffSet : 241|2@0+ (1,0) [0|3] "NoUnit" ADCS_FD3
 SG_ CDCS11_MODSw : 243|2@0+ (1,0) [0|3] "NoUnit" ADCS_FD3
 SG_ CDCS11_VoiceNotifFrequency_mode : 245|2@0+ (1,0) [0|3] "NoUnit" ADCS_FD3
 SG_ CDCS11_ACCOnOffSet : 247|2@0+ (1,0) [0|3] "NoUnit" ADCS_FD3
 SG_ CDCS11_HPASw : 249|2@0+ (1,0) [0|3] "NoUnit" ADCS_FD3
 SG_ CDCS11_DeleteMapID : 263|8@0+ (1,0) [0|255] "NoUnit" ADCS_FD3
 SG_ CDCS11_UploadMapID : 271|8@0+ (1,0) [0|255] "NoUnit" ADCS_FD3
 SG_ CDCS11_HPAActiveConfirm : 274|1@0+ (1,0) [0|1] "NoUnit" ADCS_FD3
 SG_ CDCS11_HPApreparkingSw : 278|2@0+ (1,0) [0|3] "NoUnit" ADCS_FD3
 SG_ CDCS11_HPAPathwaytoCloud_WorkSts : 282|3@0+ (1,0) [0|7] "NoUnit" ADCS_FD3
 SG_ CDCS11_PA_Select_ID : 335|8@0+ (1,0) [0|255] "NoUnit" ADCS_FD3
 SG_ CDCS11_learnpath_St : 337|2@0+ (1,0) [0|3] "NoUnit" ADCS_FD3
 SG_ CDCS11_ParkingoutSlot_Type : 369|2@0+ (1,0) [0|3] "NoUnit" ADCS_FD3
 SG_ CDCS11_ParkingoutSlot_Dire : 371|2@0+ (1,0) [0|3] "NoUnit" ADCS_FD3
 SG_ CDCS11_OptionalSlot_Type : 373|2@0+ (1,0) [0|3] "NoUnit" ADCS_FD3
 SG_ CDCS11_OptionalSlot_Dire : 360|3@0+ (1,0) [0|7] "NoUnit" ADCS_FD3
 SG_ CDCS11_OptionalSlotAngle : 383|8@0+ (0.255,0) [0|65.025] "rad" ADCS_FD3
 SG_ CDCS11_OptionalSlotCoor_P0_X : 391|16@0+ (1,0) [0|65535] "NoUnit" ADCS_FD3
 SG_ CDCS11_OptionalSlotCoor_P0_Y : 407|16@0+ (1,0) [0|65535] "NoUnit" ADCS_FD3
 SG_ CDCS11_OptionalSlotCoor_P1_X : 423|16@0+ (1,0) [0|65535] "NoUnit" ADCS_FD3
 SG_ CDCS11_OptionalSlotCoor_P1_Y : 439|16@0+ (1,0) [0|65535] "NoUnit" ADCS_FD3
 SG_ CDCS11_OptionalSlotCoor_P2_X : 455|16@0+ (1,0) [0|65535] "NoUnit" ADCS_FD3
 SG_ CDCS11_OptionalSlotCoor_P2_Y : 471|16@0+ (1,0) [0|65535] "NoUnit" ADCS_FD3
 SG_ CDCS11_OptionalSlotCoor_P3_X : 487|16@0+ (1,0) [0|65535] "NoUnit" ADCS_FD3
 SG_ CDCS11_OptionalSlotCoor_P3_Y : 503|16@0+ (1,0) [0|65535] "NoUnit" ADCS_FD3
 SG_ CDCS11_HPA_ONPath_ID1 : 295|8@0+ (1,0) [0|255] "NoUnit" ADCS_FD3
 SG_ CDCS11_HPA_ONPath_ID2 : 303|8@0+ (1,0) [0|255] "NoUnit" ADCS_FD3
 SG_ CDCS11_HPA_ONPath_ID3 : 311|8@0+ (1,0) [0|255] "NoUnit" ADCS_FD3
 SG_ CDCS11_HPA_ONPath_ID4 : 319|8@0+ (1,0) [0|255] "NoUnit" ADCS_FD3
 SG_ CDCS11_HPA_Select_ID : 327|8@0+ (1,0) [0|255] "NoUnit" ADCS_FD3

BO_ 347 GW_Fr01_15B: 8 GW_FD4
 SG_ SWSM_A_CruiseDistance_Add : 0|1@0+ (1,0) [0|1] "NoUnit" ADCS_FD3
 SG_ SWSM_A_CruiseDistance_Minus : 1|1@0+ (1,0) [0|1] "NoUnit" ADCS_FD3
 SG_ SWSM_A_CruiseSpeed_Add : 3|2@0+ (1,0) [0|3] "NoUnit" ADCS_FD3
 SG_ SWSM_A_CruiseSpeed_Minus : 5|2@0+ (1,0) [0|3] "NoUnit" ADCS_FD3
 SG_ SWSM_A_SpeechInputSw : 7|2@0+ (1,0) [0|3] "NoUnit" ADCS_FD3
 SG_ Region_A_SwError : 8|1@0+ (1,0) [0|1] "NoUnit" ADCS_FD3
 SG_ SWSM_A_CD_Add_Overtime : 9|1@0+ (1,0) [0|1] "NoUnit" ADCS_FD3
 SG_ SWSM_A_CD_Minus_Overtime : 10|1@0+ (1,0) [0|1] "NoUnit" ADCS_FD3

BO_ 443 CDCS_Fr13_1BB: 8 CDCS
 SG_ CDCS13_SwSmMode : 1|2@0+ (1,0) [0|3] "NoUnit" ADCS_FD3

BO_ 442 CDCS_Fr10_1BA: 8 CDCS
 SG_ CDCS10_WorK_status : 7|2@0+ (1,0) [0|3] "NoUnit" ADCS_FD3

BO_ 706 EDU_Fr03_2C2: 64 EDU
 SG_ EDU3_PumpPActSpd : 71|8@0+ (0.4,0) [0|100] "%" ADCS_FD3

BO_ 707 EDU_Fr04_2C3: 8 EDU
 SG_ EDU4_PwrModeSts : 11|4@0+ (1,0) [0|15] "NoUnit" ADCS_FD3
 SG_ EDU4_MotCoolgLoopSts : 25|2@0+ (1,0) [0|3] "NoUnit" ADCS_FD3

BO_ 469 EDU_Fr05_1D5: 32 EDU
 SG_ EDU5_OperMod : 55|4@0+ (1,0) [0|15] "NoUnit" ADCS_FD3

BO_ 997 EDU_Fr06_3E5: 32 EDU
 SG_ EDU6_MotInpWtrT : 103|12@0+ (1,-48) [-48|207] "" ADCS_FD3

BO_ 769 ADCS_MDC_Fr01_301: 8 ADCS_FD3
 SG_ ADCS_MDC1_FlowReq : 4|5@0+ (0.25,0) [0.25|5] "NoUnit" EDU,GW_FD2,BDCS
 SG_ ADCS_MDC1_ThmPostRun : 5|1@0+ (1,0) [0|1] "NoUnit" EDU,GW_FD2,BDCS

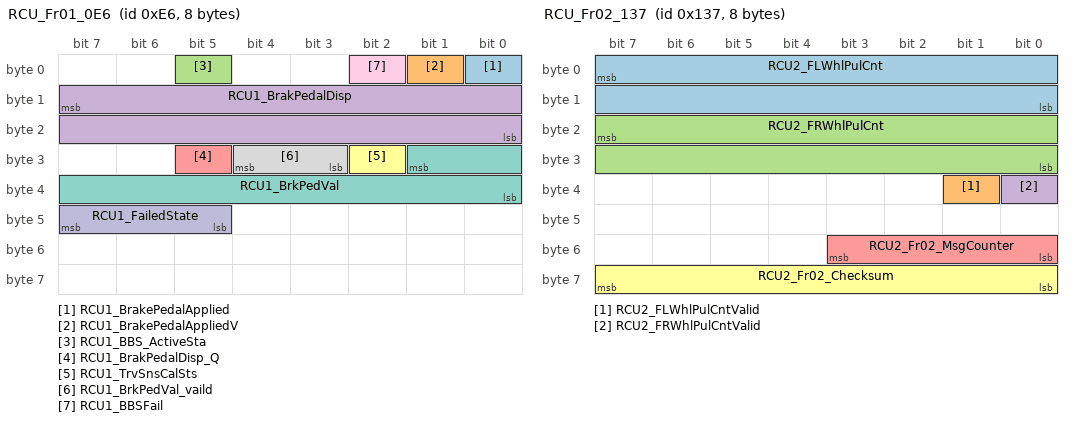
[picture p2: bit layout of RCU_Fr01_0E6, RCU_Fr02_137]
BO_ 230 RCU_Fr01_0E6: 8 RCU2
 SG_ RCU1_BrakePedalApplied : 0|1@0+ (1,0) [0|1] "NoUnit" ADCS_FD3
 SG_ RCU1_BrakePedalAppliedV : 1|1@0+ (1,0) [0|1] "NoUnit" ADCS_FD3
 SG_ RCU1_BBS_ActiveSta : 5|1@0+ (1,0) [0|1] "NoUnit" ADCS_FD3
 SG_ RCU1_BrakPedalDisp : 15|16@0+ (0.1,-40) [-40|160] "mm" ADCS_FD3
 SG_ RCU1_BrakPedalDisp_Q : 29|1@0+ (1,0) [0|1] "NoUnit" ADCS_FD3
 SG_ RCU1_TrvSnsCalSts : 26|1@0+ (1,0) [0|1] "NoUnit" ADCS_FD3
 SG_ RCU1_BrkPedVal : 25|10@0+ (0.1,0) [0|100] "%" ADCS_FD3
 SG_ RCU1_BrkPedVal_vaild : 28|2@0+ (1,0) [0|3] "NoUnit" ADCS_FD3
 SG_ RCU1_BBSFail : 2|1@0+ (1,0) [0|1] "NoUnit" ADCS_FD3
 SG_ RCU1_FailedState : 47|3@0+ (1,0) [0|7] "NoUnit" ADCS_FD3

BO_ 311 RCU_Fr02_137: 8 RCU2
 SG_ RCU2_FLWhlPulCnt : 7|16@0+ (0.5,0) [0|32767] "NoUnit" ADCS_FD3
 SG_ RCU2_FLWhlPulCntValid : 33|1@0+ (1,0) [0|1] "NoUnit" ADCS_FD3
 SG_ RCU2_FRWhlPulCnt : 23|16@0+ (0.5,0) [0|32767] "NoUnit" ADCS_FD3
 SG_ RCU2_FRWhlPulCntValid : 32|1@0+ (1,0) [0|1] "NoUnit" ADCS_FD3
 SG_ RCU2_Fr02_MsgCounter : 51|4@0+ (1,0) [0|15] "NoUnit" ADCS_FD3
 SG_ RCU2_Fr02_Checksum : 63|8@0+ (1,0) [0|255] "NoUnit" ADCS_FD3

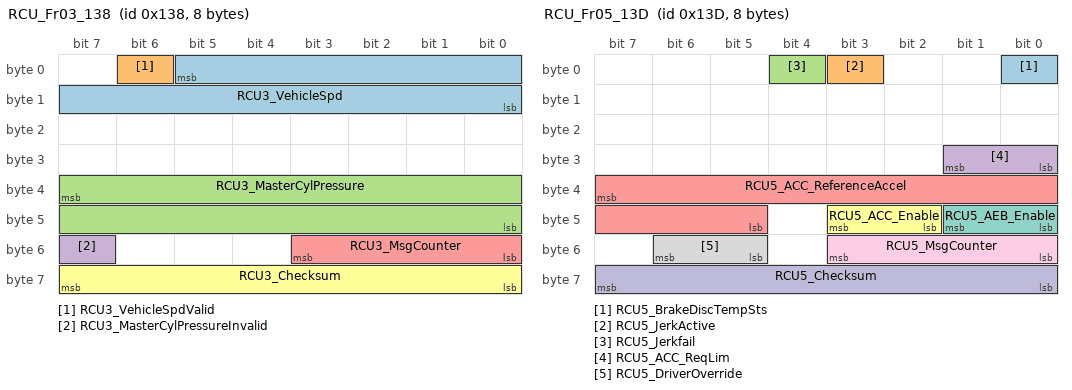
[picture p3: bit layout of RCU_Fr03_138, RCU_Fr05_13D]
BO_ 312 RCU_Fr03_138: 8 RCU2
 SG_ RCU3_VehicleSpd : 5|14@0+ (0.03125,0) [0|511.9375] "km/h" ADCS_FD3
 SG_ RCU3_VehicleSpdValid : 6|1@0+ (1,0) [0|1] "NoUnit" ADCS_FD3
 SG_ RCU3_MasterCylPressure : 39|16@0+ (0.01,-30) [0|280] "bar" ADCS_FD3
 SG_ RCU3_MasterCylPressureInvalid : 55|1@0+ (1,0) [0|1] "NoUnit" ADCS_FD3
 SG_ RCU3_MsgCounter : 51|4@0+ (1,0) [0|15] "NoUnit" ADCS_FD3
 SG_ RCU3_Checksum : 63|8@0+ (1,0) [0|255] "NoUnit" ADCS_FD3

BO_ 313 RCU_Fr04_139: 32 RCU2
 SG_ RCU4_FLWhlVelocity : 7|14@0+ (0.03125,0) [0|511.9375] "km/h" ADCS_FD3
 SG_ RCU4_FLWhlVelocityValid : 9|1@0+ (1,0) [0|1] "NoUnit" ADCS_FD3
 SG_ RCU4_FRWhlVelocity : 23|14@0+ (0.03125,0) [0|511.9375] "km/h" ADCS_FD3
 SG_ RCU4_FRWhlVelocityValid : 25|1@0+ (1,0) [0|1] "NoUnit" ADCS_FD3
 SG_ RCU4_FRWhlDir : 37|2@0+ (1,0) [0|3] "NoUnit" ADCS_FD3
 SG_ RCU4_FLWhlDir : 39|2@0+ (1,0) [0|3] "NoUnit" ADCS_FD3
 SG_ RCU4_RLWhlDir : 35|2@0+ (1,0) [0|3] "NoUnit" ADCS_FD3
 SG_ RCU4_RRWhlDir : 33|2@0+ (1,0) [0|3] "NoUnit" ADCS_FD3
 SG_ RCU4_MsgCounter : 51|4@0+ (1,0) [0|15] "NoUnit" ADCS_FD3
 SG_ RCU4_Checksum : 63|8@0+ (1,0) [0|255] "NoUnit" ADCS_FD3
 SG_ RCU4_RLWhlVelocity : 71|14@0+ (0.03125,0) [0|511.9375] "km/h" ADCS_FD3
 SG_ RCU4_RLWhlVelocityValid : 73|1@0+ (1,0) [0|1] "NoUnit" ADCS_FD3
 SG_ RCU4_RRWhlVelocity : 87|14@0+ (0.03125,0) [0|511.9375] "km/h" ADCS_FD3
 SG_ RCU4_RRWhlVelocityValid : 72|1@0+ (1,0) [0|1] "NoUnit" ADCS_FD3
 SG_ RCU4_RLWhlPulCnt : 103|16@0+ (0.5,0) [0|32767] "NoUnit" ADCS_FD3
 SG_ RCU4_RRWhlPulCnt : 119|16@0+ (0.5,0) [0|32767] "NoUnit" ADCS_FD3
 SG_ RCU4_RLWhlPulCntValid : 88|1@0+ (1,0) [0|1] "NoUnit" ADCS_FD3
 SG_ RCU4_RRWhlPulCntValid : 89|1@0+ (1,0) [0|1] "NoUnit" ADCS_FD3

BO_ 317 RCU_Fr05_13D: 8 RCU2
 SG_ RCU5_BrakeDiscTempSts : 0|1@0+ (1,0) [0|1] "NoUnit" ADCS_FD3
 SG_ RCU5_JerkActive : 3|1@0+ (1,0) [0|1] "NoUnit" ADCS_FD3
 SG_ RCU5_Jerkfail : 4|1@0+ (1,0) [0|1] "NoUnit" ADCS_FD3
 SG_ RCU5_ACC_ReqLim : 25|2@0+ (1,0) [0|3] "NoUnit" ADCS_FD3
 SG_ RCU5_ACC_ReferenceAccel : 39|11@0+ (0.01,-10.23) [-10.23|10.24] "m/s" ADCS_FD3
 SG_ RCU5_ACC_Enable : 43|2@0+ (1,0) [0|3] "NoUnit" ADCS_FD3
 SG_ RCU5_AEB_Enable : 41|2@0+ (1,0) [0|3] "NoUnit" ADCS_FD3
 SG_ RCU5_DriverOverride : 54|2@0+ (1,0) [0|3] "NoUnit" ADCS_FD3
 SG_ RCU5_MsgCounter : 51|4@0+ (1,0) [0|15] "NoUnit" ADCS_FD3
 SG_ RCU5_Checksum : 63|8@0+ (1,0) [0|255] "NoUnit" ADCS_FD3

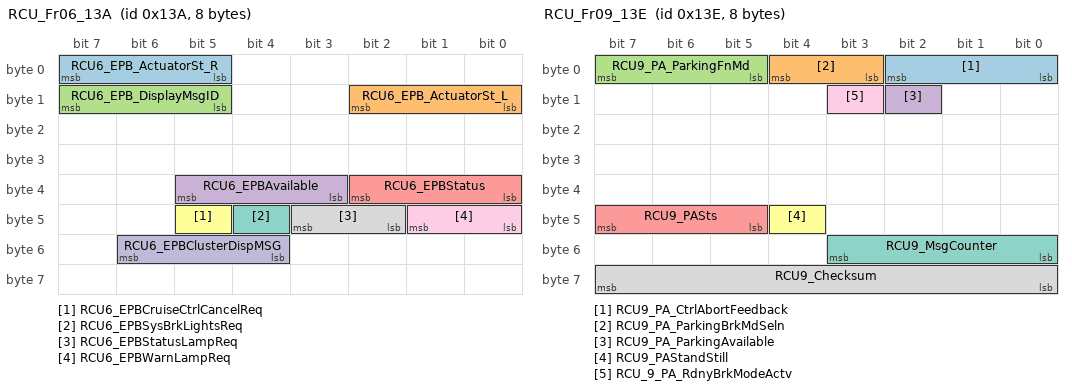
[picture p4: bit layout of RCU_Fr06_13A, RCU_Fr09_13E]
BO_ 314 RCU_Fr06_13A: 8 RCU2
 SG_ RCU6_EPB_ActuatorSt_R : 7|3@0+ (1,0) [0|7] "NoUnit" ADCS_FD3
 SG_ RCU6_EPB_ActuatorSt_L : 10|3@0+ (1,0) [0|7] "NoUnit" ADCS_FD3
 SG_ RCU6_EPB_DisplayMsgID : 15|3@0+ (1,0) [0|7] "NoUnit" ADCS_FD3
 SG_ RCU6_EPBAvailable : 37|3@0+ (1,0) [0|7] "NoUnit" ADCS_FD3
 SG_ RCU6_EPBStatus : 34|3@0+ (1,0) [0|7] "NoUnit" ADCS_FD3
 SG_ RCU6_EPBCruiseCtrlCancelReq : 45|1@0+ (1,0) [0|1] "NoUnit" ADCS_FD3
 SG_ RCU6_EPBSysBrkLightsReq : 44|1@0+ (1,0) [0|1] "NoUnit" ADCS_FD3
 SG_ RCU6_EPBStatusLampReq : 43|2@0+ (1,0) [0|3] "NoUnit" ADCS_FD3
 SG_ RCU6_EPBWarnLampReq : 41|2@0+ (1,0) [0|3] "NoUnit" ADCS_FD3
 SG_ RCU6_EPBClusterDispMSG : 54|3@0+ (1,0) [0|7] "NoUnit" ADCS_FD3

BO_ 315 RCU_Fr07_13B: 16 RCU2
 SG_ RCU7_TCSActive : 9|1@0+ (1,0) [0|1] "NoUnit" ADCS_FD3
 SG_ RCU7_TCSDisable : 10|1@0+ (1,0) [0|1] "NoUnit" ADCS_FD3
 SG_ RCU7_TCSFail : 11|1@0+ (1,0) [0|1] "NoUnit" ADCS_FD3
 SG_ RCU7_AVHDispMSG : 15|2@0+ (1,0) [0|3] "NoUnit" ADCS_FD3
 SG_ RCU7_AVHLampReq : 17|2@0+ (1,0) [0|3] "NoUnit" ADCS_FD3
 SG_ RCU7_AVHEnabled : 20|1@0+ (1,0) [0|1] "NoUnit" ADCS_FD3
 SG_ RCU7_HSAActive : 23|1@0+ (1,0) [0|1] "NoUnit" ADCS_FD3
 SG_ RCU7_HSAFail : 24|1@0+ (1,0) [0|1] "NoUnit" ADCS_FD3
 SG_ RCU7_BrkLightReq : 28|1@0+ (1,0) [0|1] "NoUnit" ADCS_FD3
 SG_ RCU7_ESSActiveReq : 31|2@0+ (1,0) [0|3] "NoUnit" ADCS_FD3
 SG_ RCU7_ABSActive : 3|1@0+ (1,0) [0|1] "NoUnit" ADCS_FD3
 SG_ RCU7_ABSFail : 29|1@0+ (1,0) [0|1] "NoUnit" ADCS_FD3
 SG_ RCU7_ESCFail : 0|1@0+ (1,0) [0|1] "NoUnit" ADCS_FD3
 SG_ RCU7_ESCActive : 1|1@0+ (1,0) [0|1] "NoUnit" ADCS_FD3
 SG_ RCU7_BrakeWarningLamp : 54|3@0+ (1,0) [0|7] "NoUnit" ADCS_FD3
 SG_ RCU7_MsgCounter : 51|4@0+ (1,0) [0|15] "NoUnit" ADCS_FD3
 SG_ RCU7_Checksum : 63|8@0+ (1,0) [0|255] "NoUnit" ADCS_FD3

BO_ 316 RCU_Fr08_13C: 16 RCU2
 SG_ RCU8_BrakeActive : 52|1@0+ (1,0) [0|1] "NoUnit" ADCS_FD3
 SG_ RCU8_MsgCounter : 51|4@0+ (1,0) [0|15] "NoUnit" ADCS_FD3
 SG_ RCU8_Checksum : 63|8@0+ (1,0) [0|255] "NoUnit" ADCS_FD3

BO_ 318 RCU_Fr09_13E: 8 RCU2
 SG_ RCU9_PA_CtrlAbortFeedback : 2|3@0+ (1,0) [0|7] "NoUnit" ADCS_FD3
 SG_ RCU9_PA_ParkingBrkMdSeln : 4|2@0+ (1,0) [0|3] "NoUnit" ADCS_FD3
 SG_ RCU9_PA_ParkingFnMd : 7|3@0+ (1,0) [0|7] "NoUnit" ADCS_FD3
 SG_ RCU9_PA_ParkingAvailable : 10|1@0+ (1,0) [0|1] "NoUnit" ADCS_FD3
 SG_ RCU9_PASts : 47|3@0+ (1,0) [0|7] "NoUnit" ADCS_FD3
 SG_ RCU9_PAStandStill : 44|1@0+ (1,0) [0|1] "NoUnit" ADCS_FD3
 SG_ RCU9_MsgCounter : 51|4@0+ (1,0) [0|15] "NoUnit" ADCS_FD3
 SG_ RCU9_Checksum : 63|8@0+ (1,0) [0|255] "NoUnit" ADCS_FD3
 SG_ RCU_9_PA_RdnyBrkModeActv : 11|1@0+ (1,0) [0|1] "NoUnit" ADCS_FD3

BO_ 765 HNS1_Fr02_2FD: 32 HNS1
 SG_ HNS1_FaultSts : 4|2@0+ (1,0) [0|3] "NoUnit" ADCS_FD3
 SG_ HNS1_VoltageSts : 2|3@0+ (1,0) [0|7] "NoUnit" ADCS_FD3
 SG_ HNS1_CurrentSts : 6|2@0+ (1,0) [0|3] "NoUnit" ADCS_FD3
 SG_ HNS1_MainSwSts : 9|2@0+ (1,0) [0|3] "NoUnit" ADCS_FD3
 SG_ HNS1_AliveCounter : 51|4@0+ (1,0) [0|15] "NoUnit" ADCS_FD3
 SG_ HNS1_Checksum : 63|8@0+ (1,0) [0|255] "NoUnit" ADCS_FD3
 SG_ HNS1_DCDCVol_status : 87|1@0+ (1,0) [0|1] "NoUnit" ADCS_FD3
 SG_ HNS1_DCDCVol : 71|16@0+ (0.001,0) [0|50] "V" ADCS_FD3
 SG_ HNS1_BatVol_status : 80|1@0+ (1,0) [0|1] "NoUnit" ADCS_FD3
 SG_ HNS1_BatVol : 95|16@0+ (0.001,0) [0|50] "V" ADCS_FD3
 SG_ HNS1_DCDCCur_status : 135|1@0+ (1,0) [0|1] "NoUnit" ADCS_FD3
 SG_ HNS1_DCDCCur : 111|24@0+ (0.001,-400) [-400|400] "A" ADCS_FD3
 SG_ HNS1_BatCur_status : 128|1@0+ (1,0) [0|1] "NoUnit" ADCS_FD3
 SG_ HNS1_BatCur : 143|24@0+ (0.001,-400) [-400|400] "A" ADCS_FD3

BO_ 310 ADCS_F12_136: 16 ADCS_FD3
 SG_ ADCS12_FCWWarnAudioplay : 5|1@0+ (1,0) [0|1] "NoUnit" GW_FD4,CDCS
 SG_ ADCS12_RCTAWarnAudioplay : 9|2@0+ (1,0) [0|3] "NoUnit" GW_FD4,CDCS
 SG_ ADCS12_FCTAWarnAudioplay : 13|2@0+ (1,0) [0|3] "NoUnit" GW_FD4,CDCS
 SG_ ADCS12_SpeedWarnAudioplay : 16|1@0+ (1,0) [0|1] "NoUnit" GW_FD4,CDCS
 SG_ ADCS12_DOWWarnAudioplay : 21|1@0+ (1,0) [0|1] "NoUnit" GW_FD4,CDCS
 SG_ ADCS12_DCLCAudioplay : 31|2@0+ (1,0) [0|3] "NoUnit" GW_FD4,CDCS
 SG_ ADCS12_PilotAudioPlay : 33|2@0+ (1,0) [0|3] "NoUnit" GW_FD4,CDCS
 SG_ ADCS12_HandOffAudioplay : 35|2@0+ (1,0) [0|3] "NoUnit" GW_FD4,CDCS
 SG_ ADCS12_NNPCancelAudioPlay : 38|1@0+ (1,0) [0|1] "NoUnit" GW_FD4,CDCS
 SG_ ADCS12_RCWWarnAudioplay : 39|1@0+ (1,0) [0|1] "NoUnit" GW_FD4,CDCS
 SG_ ADCS12_MRMAudioPlay : 41|2@0+ (1,0) [0|3] "NoUnit" GW_FD4,CDCS
 SG_ ADCS12_NNP_ResumeAudioplay : 43|2@0+ (1,0) [0|3] "NoUnit" GW_FD4,CDCS
 SG_ ADCS12_Lcsndrequest : 45|2@0+ (1,0) [0|3] "NoUnit" GW_FD4,CDCS
 SG_ ADCS12_Lcsndrconfirm : 47|2@0+ (1,0) [0|3] "NoUnit" GW_FD4,CDCS
 SG_ ADCS12_longitudDisableInfo : 59|4@0+ (1,0) [0|15] "NoUnit" GW_FD4,CDCS
 SG_ ADCS12_DriveOffBroadcast : 50|1@0+ (1,0) [0|1] "NoUnit" GW_FD4,CDCS
 SG_ ADCS12_EyeOffBroadcast : 53|1@0+ (1,0) [0|1] "" CDCS
 SG_ ADCS12_SpeedAdaptComfirm : 69|1@0+ (1,0) [0|1] "NoUnit" GW_FD4,CDCS
 SG_ ADCS12_PayModeConfirm : 72|1@0+ (1,0) [0|1] "NoUnit" GW_FD4,CDCS
 SG_ ADCS12_longitudCtrlSysInfo : 76|4@0+ (1,0) [0|15] "NoUnit" GW_FD4,ICU,CDCS
 SG_ ADCS12_NPilotSysInfo : 95|4@0+ (1,0) [0|15] "NoUnit" GW_FD4,CDCS
 SG_ ADCS12_ADAS_DriveOffinhibition : 80|1@0+ (1,0) [0|1] "NoUnit" GW_FD4,ICU,CDCS
 SG_ ADCS12_P2N_State_Reminder : 83|3@0+ (1,0) [0|7] "NoUnit" GW_FD4,ICU,CDCS
 SG_ ADCS12_NNP_State_Reminder : 86|3@0+ (1,0) [0|7] "NoUnit" GW_FD4,ICU,CDCS
 SG_ ADCS12_NNP_LightRemind : 87|1@0+ (1,0) [0|1] "NoUnit" GW_FD4,ICU,CDCS
 SG_ ADCS12_LCAudioPlay : 99|2@0+ (1,0) [0|3] "NoUnit" GW_FD4,CDCS
 SG_ ADCS12_NNP_Scenarios_AudioPlay : 103|4@0+ (1,0) [0|15] "NoUnit" GW_FD4,CDCS
 SG_ ADCS12_LaneChangePendingAlert : 90|1@0+ (1,0) [0|1] "NoUnit" GW_FD4,CDCS
 SG_ ADCS12_NNP_RINO : 111|4@0+ (1,0) [0|15] "NoUnit" GW_FD4,CDCS

BO_ 1543 ADCS_NM_607: 8 ADCS_FD3
 SG_ ADCS_SourceNodeIdentifier : 7|8@0+ (1,0) [0|255] "NoUnit" Vector_XXX
 SG_ ADCS_RepeatMessageRequest : 8|1@0+ (1,0) [0|1] "NoUnit" Vector_XXX
 SG_ ADCS_Reserve1 : 11|3@0+ (1,0) [0|3] "NoUnit" Vector_XXX
 SG_ ADCS_ActiveWakeup : 12|1@0+ (1,0) [0|1] "NoUnit" Vector_XXX
 SG_ ADCS_Reserve2 : 15|3@0+ (1,0) [0|7] "NoUnit" Vector_XXX
 SG_ ADCS_WakeUp_KL15 : 16|1@0+ (1,0) [0|1] "NoUnit" Vector_XXX
 SG_ ADCS_WakeUp_NM : 17|1@0+ (1,0) [0|1] "NoUnit" Vector_XXX
 SG_ ADCS_WakeUp_GM : 18|1@0+ (1,0) [0|1] "NoUnit" Vector_XXX
 SG_ ADCS_WakeUpReason4 : 19|1@0+ (1,0) [0|1] "NoUnit" Vector_XXX
 SG_ ADCS_WakeUpReason5 : 20|1@0+ (1,0) [0|1] "NoUnit" Vector_XXX
 SG_ ADCS_WakeUpReason6 : 21|1@0+ (1,0) [0|1] "NoUnit" Vector_XXX
 SG_ ADCS_WakeUpReason7 : 22|1@0+ (1,0) [0|1] "NoUnit" Vector_XXX
 SG_ ADCS_WakeUpReason8 : 23|1@0+ (1,0) [0|1] "NoUnit" Vector_XXX
 SG_ ADCS_RepeatFromSleep : 24|1@0+ (1,0) [0|1] "NoUnit" Vector_XXX
 SG_ ADCS_RepeatFromPrepare : 25|1@0+ (1,0) [0|1] "NoUnit" Vector_XXX
 SG_ ADCS_RepeatFromNormal : 29|1@0+ (1,0) [0|1] "NoUnit" Vector_XXX
 SG_ ADCS_RepeatFromReady : 28|1@0+ (1,0) [0|1] "NoUnit" Vector_XXX
 SG_ ADCS_NormalFromRepeat : 26|1@0+ (1,0) [0|1] "NoUnit" Vector_XXX
 SG_ ADCS_NormalFromReady : 27|1@0+ (1,0) [0|1] "NoUnit" Vector_XXX
 SG_ ADCS_RNM_DOW : 32|1@0+ (1,0) [0|1] "NoUnit" Vector_XXX
 SG_ ADCS_RNM_GM : 33|1@0+ (1,0) [0|1] "NoUnit" Vector_XXX
 SG_ ADCS_RNM_ICS : 34|1@0+ (1,0) [0|1] "NoUnit" Vector_XXX
 SG_ ADCS_RNM_RPA : 35|1@0+ (1,0) [0|1] "NoUnit" Vector_XXX
 SG_ ADCS_RNM_ISM : 36|1@0+ (1,0) [0|1] "NoUnit" Vector_XXX

BO_TX_BU_ 230 : RCU2,RCU1;
BO_TX_BU_ 311 : RCU2,RCU1;
BO_TX_BU_ 312 : RCU2,RCU1;
BO_TX_BU_ 313 : RCU2,RCU1;
BO_TX_BU_ 317 : RCU2,RCU1;
BO_TX_BU_ 314 : RCU2,RCU1;
BO_TX_BU_ 315 : RCU2,RCU1;
BO_TX_BU_ 316 : RCU2,RCU1;
BO_TX_BU_ 318 : RCU2,RCU1;
CM_ SG_ 143 ADCS11_PA_GearReq "APA换挡握手请求";
CM_ SG_ 143 ADCS11_PA_GearPosReqVail "挡位请求有效性";
CM_ SG_ 143 ADCS11_PA_prefillReq "APA请求ESC预制动";
CM_ SG_ 143 ADCS11_PA_GearPosReq "挡位请求";
CM_ SG_ 143 ADCS11_PA_BrakemodeReq "APA制动模式请求";
CM_ SG_ 143 ADCS11_PA_EpbReq "EPB请求信号";
CM_ SG_ 143 ADCS11_PA_lampreq "APA请求危险报警灯光";
CM_ SG_ 143 ADCS11_PA_StopDistance "刹车距离请求";
CM_ SG_ 143 ADCS11_PA_StopDistanceValid "刹车距离请求有效位";
CM_ SG_ 143 ADCS11_Parking_WorkSts "泊车工作状态信号";
CM_ SG_ 143 ADCS11_PA_Recover "APA/RPA泊车恢复指令";
CM_ SG_ 143 ADCS11_RPA_RemoteParkAppStartReq "泊车程序启动请求";
CM_ SG_ 143 ADCS11_TurnLampReq "请求双闪灯";
CM_ SG_ 143 ADCS11_SetPathwayWorkSts "路线管理开关反馈";
CM_ SG_ 143 ADCS11_PA_EPSAngleReq "APA请求转向角度值(left“+”,right“-” )";
CM_ SG_ 143 ADCS11_HPAGuideSts "记忆泊车学习使用状态信息播报";
CM_ SG_ 143 ADCS11_PA_IDBControlReq "IDB握手请求";
CM_ SG_ 143 ADCS11_MsgCounter0 "E2E Profile2-CRC8H2F，Counter：0-15";
CM_ SG_ 143 ADCS11_Checksum0 "E2E Profile2-CRC8H2F
DataID List:#1 - 28 8 73 140 234 86 71 199 14 46 36 103 158 122 129 242";
CM_ SG_ 143 ADCS11_HPA_WorkSts "记忆泊车状态播报";
CM_ SG_ 143 ADCS11_PA_IDBControlReqV "IDB握手请求有效位";
CM_ SG_ 143 ADCS11_PA_TarDecel "减速度请求（发给IDB）";
CM_ SG_ 143 ADCS11_PA_EPSAngleReqSt "APA转向握手控制请求";
CM_ SG_ 143 ADCS11_PA_EPSAngleReqV "APA转向握手控制请求有效性";
CM_ SG_ 143 ADCS11_PrkngFctnModeReq "泊车当前模式";
CM_ SG_ 143 ADCS11_HPAPathlearning_WorkSts "记忆泊车路线学习反馈";
CM_ SG_ 143 ADCS11_HPAPathwaytoCloud_WorkSts "路线上传反馈播报";
CM_ SG_ 143 ADCS11_TrackreverseWorkSts "循迹倒车开关反馈";
CM_ SG_ 143 ADCS11_Currentgear "泊车当前档位信息";
CM_ SG_ 143 ADCS11_PA_PAMaxSpd "最大速度请求";
CM_ SG_ 143 ADCS11_PA_Pause_Recover "HPP/SM 暂停反馈";
CM_ SG_ 143 ADCS11_PA_ParkingFnMd "泊车当前工作状态";
CM_ SG_ 143 ADCS11_PA_TarDecelreq "PA请求加减速度控制";
CM_ SG_ 143 ADCS11_HPA_BacktoEntrance "回到车库入口";
CM_ SG_ 143 ADCS11_HPA_BacktoStart "回到起点位置";
CM_ SG_ 143 ADCS11_PA_TorqReq "PA请求控制加速";
CM_ SG_ 143 ADCS11_PA_TorqReqValue "目标扭力值（轮端）";
CM_ SG_ 143 ADCS11_PA_TorqReqValidity "目标扭力值有效位";
CM_ SG_ 143 ADCS11_PA_screenReq "泊车系统对大屏显示的请求";
CM_ SG_ 143 ADCS11_APA_RemoteStartReq "远程启动请求";
CM_ SG_ 143 ADCS11_APA_RemoteShutdownReq "远程熄火请求";
CM_ SG_ 143 ADCS11_MirrorFoldrequest "车后视镜控制请求";
CM_ SG_ 143 ADCS11_APA_FLWindowsCtrl "远程控制主驾车窗动作";
CM_ SG_ 143 ADCS11_APA_RemoteLockCtrl "远程控制车辆上锁";
CM_ SG_ 143 ADCS11_APA_FRWindowsCtrl "远程控制副驾车窗动作";
CM_ SG_ 143 ADCS11_APA_RLWindowsCtrl "远程控制左后车窗动作";
CM_ SG_ 143 ADCS11_APA_RRWindowsCtrl "远程控制右后车窗动作";
CM_ SG_ 143 ADCS11_APA_requestMirrorFoldSt "请求控制后视镜状态";
CM_ SG_ 143 ADCS11_PA_StopReq "stop请求信号";
CM_ SG_ 143 ADCS11_HPA_PathlearningSt "路线学习状态";
CM_ SG_ 143 ADCS11_HPA_Path_exist "是否存在记忆泊车路线";
CM_ SG_ 143 ADCS11_HPA_Pathavailable_ID1 "显示存在路线";
CM_ SG_ 143 ADCS11_HPA_Pathavailable_ID2 "显示存在路线";
CM_ SG_ 143 ADCS11_HPA_distance "记忆泊车剩余距离信息";
CM_ SG_ 143 ADCS11_Parkingtimeremaining "记忆泊车剩余时间";
CM_ SG_ 143 ADCS11_PA_PickSt "ADCS反馈接驾模式";
CM_ SG_ 143 ADCS11_NNS_distance "智能召唤剩余距离";
CM_ SG_ 143 ADCS11_PA_IDB_TorqReqValue "PA请求IDB扭矩值";
CM_ SG_ 143 ADCS11_HighBeam "请求远光灯";
CM_ SG_ 143 ADCS11_LowBeam "请求近光灯";
CM_ SG_ 143 ADCS11_ReqPwmode "ADCS请求上高压";
CM_ SG_ 143 ADCS11_SecuritySts "ADCS发送认证";
CM_ SG_ 143 ADCS11_PA_IDB_TorqReqValidity "PA请求IDB扭矩值有效位";
CM_ SG_ 143 ADCS11_HPA_learnpathdistance "车端选择车位信息";
CM_ SG_ 142 ADCS2_ADAS_EPSAngleReqSt "ADAS横向控制对EPS的请求状态";
CM_ SG_ 142 ADCS2_EPS_LDPState "LDP功能状态";
CM_ SG_ 142 ADCS2_NNP_SystemFaultStatus "NNP故障状态";
CM_ SG_ 142 ADCS2_ADAS_EPSLateralCtrlType "ADAS横向控制对EPS的请求类型";
CM_ SG_ 142 ADCS_Pilot_SystemFaultStatus "Pilot故障状态";
CM_ SG_ 142 ADCS2_ADSDriving_mode "自动驾驶风格设置";
CM_ SG_ 142 ADCS2_ADAS_EPSAngleReq "ADAS 请求转向角度值(left“+”,right“-” )";
CM_ SG_ 142 ADCS2_ADAS_IHBCSysState "IHBC System State";
CM_ SG_ 142 ADCS2_ALCDirection "变道转向灯请求";
CM_ SG_ 142 ADCS2_MsgCounter0 "E2E Profile2-CRC8H2F，Counter：0-15";
CM_ SG_ 142 ADCS2_EPS_ELKState "ELK功能状态";
CM_ SG_ 142 ADCS2_Checksum0 "E2E Profile2-CRC8H2F
DataID List:#4 - 158 161 150 33 238 151 203 19 139 104 55 2 184 16 105 67";
CM_ SG_ 142 ADCS2_AEB_JerkReq "AEB点刹报警请求";
CM_ SG_ 142 ADCS2_AEBPrefillReq "This signal means command to activate pre-fill";
CM_ SG_ 142 ADCS2_AEB_DBSLevel "This signal means command to use lowered DBS (Dynamic Braking Support) threshold to determine the DBS entrance";
CM_ SG_ 142 ADCS2_AEBPartialBrake "This signal means flag which indicates that the deceleration command for AEB partial braking is valid or not.";
CM_ SG_ 142 ADCS2_AEBFullBrake "This signal means flag which indicates that the deceleration command for AEB full braking is valid or not.";
CM_ SG_ 142 ADCS2_AEBVehicleHoldReq "This signal means stop request flag by AEB";
CM_ SG_ 142 ADCS2_AEBTargetDeceleration "This signal means deceleration command for AEB braking";
CM_ SG_ 142 ADCS2_longitudCtrlType "ADAS纵向控制请求类型";
CM_ SG_ 142 ADCS2_LongitudCtrlDecToStopReq "ADAS纵向控制减速到停请求";
CM_ SG_ 142 ADCS2_LongitudCtrlDriveOff "ADAS纵向控制起步请求";
CM_ SG_ 142 ADCS2_AEB_JerkLevel "Jerk等级";
CM_ SG_ 142 ADCS2_LongitudCtrlTargetAccel "ADAS纵向控制请求值";
CM_ SG_ 142 ADCS2_LongitudCtrlAccelCtrlReq "ADAS纵向控制请求";
CM_ SG_ 613 ADCS1_CarMdlDispSts "360全景2D、3D模式反馈";
CM_ SG_ 613 ADCS1_GuidOvlDispSts "360全景轨迹线显示方式";
CM_ SG_ 613 ADCS1_MOD_WorkSts "360低速移动物体探测工作状态";
CM_ SG_ 613 ADCS1_MOD_AlarmSts "360低速移动物体警告";
CM_ SG_ 613 ADCS1_CarMdlTrsprcySts "360透明底盘显示模式";
CM_ SG_ 613 ADCS1_AutoViewChgFuncSts "360智能视角模式状态反馈";
CM_ SG_ 613 ADCS1_SigViewIndcn "360前后左右视角";
CM_ SG_ 613 ADCS1_AutoAVMSwtSet_Sts "360转向开启功能状态";
CM_ SG_ 248 EMS2_EngineSpeed "Engine Speed";
CM_ SG_ 320 CDCS3_ESCOffSw "ESC OFF开关";
CM_ SG_ 320 CDCS3_HDCSw "HDC开关";
CM_ SG_ 320 CDCS3_DriveModeSet "驾驶模式选择";
CM_ SG_ 320 CDCS3_Xcoordinate "IHU坐标X";
CM_ SG_ 320 CDCS3_Ycoordinate "IHU坐标Y";
CM_ SG_ 320 CDCS3_XGestureSpd "IHU坐标X速度";
CM_ SG_ 320 CDCS3_YGestureSpd "IHU坐标Y速度";
CM_ SG_ 320 CDCS3_TouchEvtTyp "触屏类型";
CM_ SG_ 559 EMS4_Throttleposition "节气门开度";
CM_ SG_ 418 DDCU1_FL_WinPos "左前车窗位置信息(0%关闭100%全开)";
CM_ SG_ 418 DDCU1_RL_WinPos "左后车窗位置信息(0%关闭100%全开)";
CM_ SG_ 418 DDCU1_FLDoorAjar "左前车门开闭状态";
CM_ SG_ 418 DDCU1_RLDoorAjar "左后车门开闭状态";
CM_ SG_ 418 DDCU1_MirrorFoldSt "外后视镜折叠状态";
CM_ SG_ 418 DDCU1_FL_LockSt "左前侧门锁状态";
CM_ SG_ 418 DDCU1_RL_LockSt "左后侧门锁状态";
CM_ SG_ 419 PDCU1_FR_WinPos "右前车窗位置信息(0%关闭100%全开)";
CM_ SG_ 419 PDCU1_RR_WinPos "右后车窗位置信息(0%关闭100%全开)";
CM_ SG_ 419 PDCU1_FRDoorAjar "右前车门开闭状态";
CM_ SG_ 419 PDCU1_RRDoorAjar "右后车门开闭状态";
CM_ SG_ 419 PDCU1_FR_LockSt "右前侧门锁状态";
CM_ SG_ 419 PDCU1_RR_LockSt "右后侧门锁状态";
CM_ SG_ 468 CDCS5_ResetAllSetup "重置设置的信号";
CM_ SG_ 468 CDCS5_FactoryReset "恢复出厂的信号";
CM_ SG_ 482 BDCS4_Ftyre_Status "前轮信号状态(表示本帧信号代表的是当前状态还是前回状态)";
CM_ SG_ 482 BDCS4_FLTyre_LearntSt "左前轮胎传感器学习状态";
CM_ SG_ 482 BDCS4_FLTyre_PressureWarn "左前轮胎胎压报警";
CM_ SG_ 482 BDCS4_FLTyre_TemperatureWarn "左前轮胎高温报警";
CM_ SG_ 482 BDCS4_FLTyre_QucikLeak "左前轮快速漏气";
CM_ SG_ 482 BDCS4_FLTyre_SensorFailure "左前轮胎传感器故障";
CM_ SG_ 482 BDCS4_FLTyre_LowBattery "左前轮胎传感器电量低";
CM_ SG_ 482 BDCS4_FLTyre_Pressure "左前轮胎压力";
CM_ SG_ 482 BDCS4_FLTyre_Temperature "左前轮胎温度";
CM_ SG_ 482 BDCS4_FRTyre_LearntSt "右前轮胎传感器学习状态";
CM_ SG_ 482 BDCS4_FRTyre_PressureWarn "右前轮胎胎压报警";
CM_ SG_ 482 BDCS4_FRTyre_TemperatureWarn "右前轮胎高温报警";
CM_ SG_ 482 BDCS4_FRTyre_QucikLeak "右前轮快速漏气";
CM_ SG_ 482 BDCS4_FRTyre_SensorFailure "右前轮胎传感器故障";
CM_ SG_ 482 BDCS4_FRTyre_LowBattery "右前轮胎传感器电量低";
CM_ SG_ 482 BDCS4_FRTyre_Pressure "右前轮胎压力";
CM_ SG_ 482 BDCS4_FRTyre_Temperature "右前轮胎温度";
CM_ SG_ 482 BDCS4_Testmode "自检模式";
CM_ SG_ 482 BDCS4_SystemFailure "系统报警";
CM_ SG_ 484 BDCS5_Rtyre_Status "后轮信号状态(表示本帧信号代表的是当前状态还是前回状态)";
CM_ SG_ 484 BDCS5_RLTyre_LearntSt "左后轮胎传感器学习状态";
CM_ SG_ 484 BDCS5_RLTyre_PressureWarn "左后轮胎胎压报警";
CM_ SG_ 484 BDCS5_RLTyre_TemperatureWarn "左后轮胎高温报警";
CM_ SG_ 484 BDCS5_RLTyre_QucikLeak "左后轮快速漏气";
CM_ SG_ 484 BDCS5_RLTyre_SensorFailure "左后轮胎传感器故障";
CM_ SG_ 484 BDCS5_RLTyre_LowBattery "左后轮胎传感器电量低";
CM_ SG_ 484 BDCS5_RLTyre_Pressure "左后轮胎压力";
CM_ SG_ 484 BDCS5_RLTyre_Temperature "左后轮胎温度";
CM_ SG_ 484 BDCS5_RRTyre_LearntSt "右后轮胎传感器学习状态";
CM_ SG_ 484 BDCS5_RRTyre_PressureWarn "右后轮胎胎压报警";
CM_ SG_ 484 BDCS5_RRTyre_TemperatureWarn "右后轮胎高温报警";
CM_ SG_ 484 BDCS5_RRTyre_QucikLeak "右后轮快速漏气";
CM_ SG_ 484 BDCS5_RRTyre_SensorFailure "右后轮胎传感器故障";
CM_ SG_ 484 BDCS5_RRTyre_LowBattery "右后轮胎传感器电量低";
CM_ SG_ 484 BDCS5_RRTyre_Pressure "右后轮胎压力";
CM_ SG_ 484 BDCS5_RRTyre_Temperature "右后轮胎温度";
CM_ SG_ 486 BDCS6_FrontWiperSts "前雨刮工作状态";
CM_ SG_ 486 BDCS6_FrontWiperParkPos "前雨刮回位开关状态";
CM_ SG_ 486 BDCS6_DayNightMode "白天夜晚模式";
CM_ SG_ 756 BTM2_ConnectSts "蓝牙钥匙与蓝牙模块的连接状态（包括蓝牙物理钥匙和蓝牙手机钥匙）";
CM_ SG_ 756 BTM2_Key_Position "钥匙位置";
CM_ SG_ 243 BTM1_SecuritySts "BTM蓝牙认证状态";
CM_ SG_ 243 BTM1_PhoneBatSts "手机电量低提示信息";
CM_ SG_ 243 BTM1_RemoteIntModSel "手机电话中断";
CM_ SG_ 243 BTM1_SelectSlotID "车位信息";
CM_ SG_ 243 BTM1_Retry "遇障碍物重试开关";
CM_ SG_ 243 BTM1_Fixslot "确认车位开关";
CM_ SG_ 243 BTM1_ParkingReq "开始泊车信息";
CM_ SG_ 243 BTM1_Recover "恢复泊车信息";
CM_ SG_ 243 BTM1_parkingoutSlotType "泊出车位类型信号";
CM_ SG_ 243 BTM1_parkingoutSlot_Dire "泊出车位方向信号";
CM_ SG_ 243 BTM1_OptionalSlotType "自选车位类型信号";
CM_ SG_ 243 BTM1_OptionalSlot_Dire "自选车位方向信号";
CM_ SG_ 243 BTM1_FunctionMode "遥控泊车模式信号";
CM_ SG_ 243 BTM1_RemoteParkReq "遥控泊车请求";
CM_ SG_ 243 BTM1_Movectrl "遥控泊车前进后退信号";
CM_ SG_ 243 BTM1_RollingCounter "E2E Profile2-CRC8H2F，Counter：0-15";
CM_ SG_ 243 BTM1_Checksum "E2E Profile2-CRC8H2F
DataID List:#18 - 160 145 248 202 149 236 182 34 83 178 198 196 106 105 48 207";
CM_ SG_ 243 BTM1_OptionalSlotAngle "自选车位角度信号";
CM_ SG_ 243 BTM1_OptionalSlotCoor_P0_X "自选车位坐标信号";
CM_ SG_ 243 BTM1_OptionalSlotCoor_P0_Y "自选车位坐标信号";
CM_ SG_ 243 BTM1_OptionalSlotCoor_P1_X "自选车位坐标信号";
CM_ SG_ 243 BTM1_OptionalSlotCoor_P1_Y "自选车位坐标信号";
CM_ SG_ 243 BTM1_OptionalSlotCoor_P2_X "自选车位坐标信号";
CM_ SG_ 243 BTM1_OptionalSlotCoor_P2_Y "自选车位坐标信号";
CM_ SG_ 243 BTM1_OptionalSlotCoor_P3_X "自选车位坐标信号";
CM_ SG_ 243 BTM1_OptionalSlotCoor_P3_Y "自选车位坐标信号";
CM_ SG_ 498 BTM3_RKECmd "物理蓝牙钥匙命令";
CM_ SG_ 227 VCU5_ActGear "Strategy gear (VCU)";
CM_ SG_ 227 VCU5_ActGearValid "Strategy gear valid (VCU)";
CM_ SG_ 227 VCU5_READYLightSts "运动准备就绪指示灯";
CM_ SG_ 227 VCU5_PwrTrainFailureLevel "动力系统故障等级";
CM_ SG_ 227 VCU5_HVReady "高压准备就绪";
CM_ SG_ 227 VCU5_EmuEngineSts "模拟（仿真emulated）的引擎状态，用于start控制逻辑。";
CM_ SG_ 227 VCU5_AccelPositionValid "加速踏板行程有效位";
CM_ SG_ 227 VCU5_AccelPosition "加速踏板行程";
CM_ SG_ 227 VCU5_DriverOvertakeMode "驾驶员超越模式";
CM_ SG_ 227 VCU5_DriveMode_fb "驾驶模式反馈(VCU)";
CM_ SG_ 227 VCU5_AliveCounter "E2E Profile2-CRC8H2F，Counter：0-15";
CM_ SG_ 227 VCU5_Checksum "E2E Profile2-CRC8H2F
DataID List:#16 - 149 178 48 27 29 185 17 203 148 68 204 36 101 195 44 16";
CM_ SG_ 739 VCU3_EPBBackupCtrlActv "PDCS接管EPB控制状态";
CM_ SG_ 739 VCU3_EPBBackupCtrlSts "EPB备份控制状态";
CM_ SG_ 724 VCU4_CCS_Status "定速巡航状态";
CM_ SG_ 251 VCU6_SystemWarnLightSts "系统报警灯（黄色降功率）";
CM_ SG_ 251 VCU6_StrtgyGear "档位控制功能需求";
CM_ SG_ 252 VCU7_MaxMotPosTq "1、基于电池可用放电功率计算的电机前向允许驱动扭矩；
2、MCU执行扭矩+MCU内部防抖扭矩之和不允许超出此上限";
CM_ SG_ 252 VCU7_MaxMotGenTq "1、基于电池可用放电功率和回充功率计算的电机允许倒车扭矩和回充扭矩，MCU内部取反处理；
2、MCU执行扭矩+MCU内部防抖扭矩之和不允许超出此上限";
CM_ SG_ 252 VCU7_MaxFMotPosTq "1、基于电池可用放电功率计算的电机前向允许驱动扭矩；
2、FMCU执行扭矩+FMCU内部防抖扭矩之和不允许超出此上限";
CM_ SG_ 252 VCU7_MaxFMotGenTq "1、基于电池可用放电功率和回充功率计算的电机允许倒车扭矩和回充扭矩，FMCU内部取反处理；
2、FMCU执行扭矩+MCU内部防抖扭矩之和不允许超出此上限";
CM_ SG_ 264 VCU14_ACC_Ready "VCU的ACC功能准备就绪，可以响应ACC扭矩请求";
CM_ SG_ 264 VCU14_PAAvailable "VCU是否满足APA控制要求";
CM_ SG_ 264 VCU14_PAActive "VCU反馈握手请求";
CM_ SG_ 264 VCU14_PA_ParkingFnMd "VCU反馈当前泊车功能模式";
CM_ SG_ 264 VCU14_PA_FailCode "VCU反馈VCU fail的原因";
CM_ SG_ 264 VCU14_Gear_PAAvailable "Gear是否满足APA控制状态";
CM_ SG_ 264 VCU14_Gear_PAActive "Gear反馈握手请求";
CM_ SG_ 264 VCU14_Gear_PACtrlAbortFeedback "Gear系统APA功能退出原因";
CM_ SG_ 264 VCU14_Gear_ErrorSts_M01 "系统故障信号";
CM_ SG_ 264 VCU4_PA_DeceltorSts "VCU是否支持负扭矩";
CM_ SG_ 264 VCU4_PA_TargetTrqValueValidity "VCU接收到PA目标扭力值有效位";
CM_ SG_ 264 VCU4_PA_TargetTrqValue "VCU接收到PA目标扭力值[-400,400]Nm";
CM_ SG_ 264 VCU14_Fr0E_MsgCounter "E2E Profile2-CRC8H2F，Counter：0-15";
CM_ SG_ 264 VCU14_Fr0E_Checksum "E2E Profile2-CRC8H2F
DataID List:#28 - 148 221 7 229 19 81 190 49 200 67 41 82 170 169 230 197";
CM_ SG_ 438 TBOX2_AVMOnReq "AVM远程启动信号";
CM_ SG_ 438 TBOX2_RemoteParkStartPressReqSts "远程APP操作车辆运动是否有效";
CM_ SG_ 438 TBOX2_RemoteHPP "远程HPP";
CM_ SG_ 438 TBOX2_AVMviewReq "用户请求AVM切换视野";
CM_ SG_ 438 TBOX2_RemoteParkReq "泊车请求";
CM_ SG_ 438 TBOX2_SecuritySts "无线网络认证状态";
CM_ SG_ 438 TBOX2_ConnectSts "无线网络APP连接情况";
CM_ SG_ 438 TBOX2_PhoneInCar "判断手机是否在车内";
CM_ SG_ 438 TBOX2_RemoteParkAbortReq "远程请求退出界面";
CM_ SG_ 438 TBOX2_RemoteParkStartPressReq "远程APP操作车辆运动状态";
CM_ SG_ 438 TBOX2_RemoteParkOutModSel "手机APP选择的泊车模式";
CM_ SG_ 438 TBOX2_PhoneBatSts "手机电量低提示信息";
CM_ SG_ 438 TBOX2_RemoteIntModSel "手机电话中断";
CM_ SG_ 438 TBOX2_RemoteSw "随意遥控开关";
CM_ SG_ 438 TBOX2_RemoteCtrModSel "手机APP选择的随意遥控模式";
CM_ SG_ 438 TBOX2_RemoteCtrSw "开启APP随意遥控泊车功能";
CM_ SG_ 438 TBOX2_PA_PauseRecover_Req "手机端暂停&恢复HPP/SM请求";
CM_ SG_ 438 TBOX2_RollingCounter "E2E Profile2-CRC8H2F，Counter：0-15";
CM_ SG_ 438 TBOX2_Checksum "E2E Profile2-CRC8H2F
DataID List:#4 - 158 161 150 33 238 151 203 19 139 104 55 2 184 16 105 67";
CM_ SG_ 438 TBOX2_GMOnreq "哨兵模式远程开启";
CM_ SG_ 438 TBOX2_360viewReq "实时查看请求";
CM_ SG_ 438 TBOX2_360SpecView "视角实时查看";
CM_ SG_ 438 TBOX2_RemoteVhpower "请求车辆上下电";
CM_ SG_ 438 TBOX2_NRPReq "手机App打开智能召唤";
CM_ SG_ 438 TBOX2_SDMapReq "手机App显示地图";
CM_ SG_ 438 TBOX2_NNSSW "开始召唤开关";
CM_ SG_ 438 TBOX2_Remotepick "手机App端选择接驾模式";
CM_ SG_ 438 TBOX2_NNSsuspend "智能召唤暂停";
CM_ SG_ 438 TBOX2_HPA_ONPath_ID "手机端记忆泊车路线选择";
CM_ SG_ 438 TBOX2_HPA_PickPath_ID "记忆泊车接驾路线选择";
CM_ SG_ 670 BDCS10_AC_OutsideTempValid "室外温度值有效性";
CM_ SG_ 670 BDCS10_AC_OutsideTemp "室外温度值";
CM_ SG_ 645 BDCS13_RLS_RQ_WiperSPD "雨刮速度";
CM_ SG_ 600 BMS3_StateOfCharge "电池电量SOC";
CM_ SG_ 600 BMS3_Charge_State "电池充电状态";
CM_ SG_ 501 CDCS11_LKSSetspeed "速度设定反馈";
CM_ SG_ 501 CDCS11_LDW_OnOffSet "LKS开启/关闭设置";
CM_ SG_ 501 CDCS11_LowSpeedBSDSw "低速BSD功能开关";
CM_ SG_ 501 CDCS11_FCW_OnOffSet "FCW开启/关闭控制开关";
CM_ SG_ 501 CDCS11_AEB_OnOffSet "AEB开启/关闭控制开关";
CM_ SG_ 501 CDCS11_FCW_WarnTiming "FCW灵敏度设置";
CM_ SG_ 501 CDCS11_FCTA_OnOffSet "FCTA开启/关闭设置";
CM_ SG_ 501 CDCS11_RCTA_OnOffSet "RCTA开启/关闭设置";
CM_ SG_ 501 CDCS11_RCW_OnOffSet "RCW开启/关闭设置";
CM_ SG_ 501 CDCS11_DOW_OnOffSet "DOW开启/关闭设置";
CM_ SG_ 501 CDCS11_IHBC_SysSwState "IHBC mode switch request by driver
智能远光灯功能设置开关";
CM_ SG_ 501 CDCS11_LCA_OnOffSet "LCA开启/关闭设置";
CM_ SG_ 501 CDCS11_TSR_OnOffSet "TSR开启/关闭设置";
CM_ SG_ 501 CDCS11_AVM_3DRotate "3D旋转动画";
CM_ SG_ 501 CDCS11_AVM_Turnlightstart "转向灯开启全景";
CM_ SG_ 501 CDCS11_AVM_Steeringstart "转向角开启全景";
CM_ SG_ 501 CDCS11_AVM_Magnifiedview "自动放大视角开关";
CM_ SG_ 501 CDCS11_AVM_MODdetection "移动物体检测";
CM_ SG_ 501 CDCS11_GM_OnOffSet "哨兵模式开启/关闭设置";
CM_ SG_ 501 CDCS11_NNP_OnOffSet "NNP开启/关闭设置";
CM_ SG_ 501 CDCS11_DCLCSysState "DCLC开启/关闭设置";
CM_ SG_ 501 CDCS11_ALCSysState "ALC开启/关闭设置";
CM_ SG_ 501 CDCS11_DriveOffPossilbeswitch "前车起步提请状态";
CM_ SG_ 501 CDCS11_DriveOffinhibitionswitch "前车起步抑制";
CM_ SG_ 501 CDCS11_ADAS_SndCtrlOnOff "ADAS唤醒语音开关状态";
CM_ SG_ 501 CDCS11_AVM_auxiliaryline "辅助线";
CM_ SG_ 501 CDCS11_AVM_Raderdisplay "雷达显示";
CM_ SG_ 501 CDCS11_AVM_Transparentchassis "透明底盘";
CM_ SG_ 501 CDCS11_VoiceMode "语音播报模式";
CM_ SG_ 501 CDCS11_NNP_Active_OnOffSet "NNP快捷开关";
CM_ SG_ 501 CDCS11_ALC_mode "NNP_ALC自动变道设置";
CM_ SG_ 501 CDCS11_ADSDriving_mode "NNP_自动驾驶风格选项设置";
CM_ SG_ 501 CDCS11_TSR_OverspeedOnoffSet "超速报警开关";
CM_ SG_ 501 CDCS11_NNP_AutoOnOffSet "NNP快捷开关_开启关闭";
CM_ SG_ 501 CDCS11_SnCtrl_NNP_OnOff "NNP语音开启关闭控制";
CM_ SG_ 501 CDCS11_GM_VidedIn "哨兵模式";
CM_ SG_ 501 CDCS11_TSR_SLFOnOffSet "智能限速_开关";
CM_ SG_ 501 CDCS11_APA_FunctionMode "泊车功能模式";
CM_ SG_ 501 CDCS11_TrackreverseSW "循迹倒车开关";
CM_ SG_ 501 CDCS11_SetPathwaySW "路线管理开关";
CM_ SG_ 501 CDCS11_PA_changeLanguage "语言切换";
CM_ SG_ 501 CDCS11_LDP_OnOffSet "LDP开关设置";
CM_ SG_ 501 CDCS11_AVMSw "AVM软开关";
CM_ SG_ 501 CDCS11_tryHPP "记忆泊车试一试按键";
CM_ SG_ 501 CDCS11_RPASw "RPA软开关";
CM_ SG_ 501 CDCS11_SetSw "设置项开启";
CM_ SG_ 501 CDCS11_SoundCtrlSetReq "语音控制使能开关";
CM_ SG_ 501 CDCS11_location_sw "IHU发出APA定位开启信号";
CM_ SG_ 501 CDCS11_Pathrefresh "更新路线开关";
CM_ SG_ 501 CDCS11_HPAGuideSW "开关，用户选择是否尝试记忆泊车学习";
CM_ SG_ 501 CDCS11_HPAPathwaytoCloudSW "记忆泊车路线学习完成，是否上传开关";
CM_ SG_ 501 CDCS11_PathlearningSw "记忆泊车路线学习开关";
CM_ SG_ 501 CDCS11_PA_screenMd "大屏收到泊车系统状态";
CM_ SG_ 501 CDCS11_PASw "APA软开关";
CM_ SG_ 501 CDCS11_PA_Recover "IHU发出恢复泊车指令";
CM_ SG_ 501 CDCS_Lcsndrequest "语音变道";
CM_ SG_ 501 CDCS_Lcsndconfirm "主动变道驾驶员确认";
CM_ SG_ 501 CDCS_SpdAdaptComfirm "速度匹配确认信号";
CM_ SG_ 501 CDCS_PayModeConfirm "收费站匹配确认信号";
CM_ SG_ 501 CDCS11_SelectSlotID "车位选择信息";
CM_ SG_ 501 CDCS11_ParkingInReq "开始泊入开关";
CM_ SG_ 501 CDCS11_ParkingOutReq "开始泊出开关";
CM_ SG_ 501 CDCS11_AVM_ViewMode "视图显示模式";
CM_ SG_ 501 CDCS11_RPA_FunctionMode "遥控泊车功能模式";
CM_ SG_ 501 CDCS11_AVM_VideoOutputFail "视频输出信号";
CM_ SG_ 501 CDCS11_AVM_Initialization "初始化设置";
CM_ SG_ 501 CDCS11_AVM_bodySync "车身信息同步开关";
CM_ SG_ 501 CDCS11_AVM_SpeView "特殊视角";
CM_ SG_ 501 CDCS11_AVM_licenseplateabbr "车牌照省会简称";
CM_ SG_ 501 CDCS11_AVM_licenseplateArea "省内区域";
CM_ SG_ 501 CDCS11_AVM_StartMode "AVM启动模式设置";
CM_ SG_ 501 CDCS11_AVM_LicensePlateNO1 "车牌照第1位数字";
CM_ SG_ 501 CDCS11_ELK_OnOffSet "ELK开关设置";
CM_ SG_ 501 CDCS11_AVM_LicensePlateNO2 "车牌照第2位数字";
CM_ SG_ 501 CDCS11_AVM_LicensePlateNO3 "车牌照第3位数字";
CM_ SG_ 501 CDCS11_DCWposition "开门预警设置";
CM_ SG_ 501 CDCS11_AVM_LicensePlateNO4 "车牌照第4位数字";
CM_ SG_ 501 CDCS11_FindCarAvmReq "智能寻车";
CM_ SG_ 501 CDCS11_AVM_LicensePlateNO5 "车牌照第5位数字";
CM_ SG_ 501 CDCS11_AVM_LicensePlateNO6 "车牌照第6位数字";
CM_ SG_ 501 CDCS11_AVM_LicensePlateNO7 "车牌照第7位数字";
CM_ SG_ 501 CDCS11_AVM_LicensePlateNO8 "车牌照第8位数字";
CM_ SG_ 501 CDCS11_AVM_Powertype "车辆动力类型";
CM_ SG_ 501 CDCS11_AVM_Diaphaneity "透明度";
CM_ SG_ 501 CDCS11_AVM_DiaphaneitySw "透明度功能开关";
CM_ SG_ 501 CDCS11_MOD_Sound_Sw "MOD报警设置开关";
CM_ SG_ 501 CDCS11_MOD_BSD_Sw "低速BSD功能";
CM_ SG_ 501 CDCS11_PA_FRS_OnOffSet "前雷达开关";
CM_ SG_ 501 CDCS11_PA_3D_OnOffSet "超声波雷达立体显示开关";
CM_ SG_ 501 CDCS11_PA_measure_OnOffSet "超声波雷达测距显示开关";
CM_ SG_ 501 CDCS11_MODSw "MOD低速动态物体识别设置开关";
CM_ SG_ 501 CDCS11_VoiceNotifFrequency_mode "导航播报模式";
CM_ SG_ 501 CDCS11_ACCOnOffSet "巡航开关信号";
CM_ SG_ 501 CDCS11_HPASw "开启记忆泊车开关";
CM_ SG_ 501 CDCS11_DeleteMapID "删除地图ID";
CM_ SG_ 501 CDCS11_UploadMapID "上传地图ID";
CM_ SG_ 501 CDCS11_HPAActiveConfirm "确认注意事项";
CM_ SG_ 501 CDCS11_HPApreparkingSw "记忆泊车快捷开关";
CM_ SG_ 501 CDCS11_HPAPathwaytoCloud_WorkSts "路线上传开关状态";
CM_ SG_ 501 CDCS11_PA_Select_ID "车端选择车位信息";
CM_ SG_ 501 CDCS11_learnpath_St "记忆泊车路线学习后用户操作状态";
CM_ SG_ 501 CDCS11_ParkingoutSlot_Type "自选车位类型";
CM_ SG_ 501 CDCS11_ParkingoutSlot_Dire "自选车位方向";
CM_ SG_ 501 CDCS11_OptionalSlot_Type "自选车位类型";
CM_ SG_ 501 CDCS11_OptionalSlot_Dire "自选车位方向";
CM_ SG_ 501 CDCS11_OptionalSlotAngle "自选车位角度";
CM_ SG_ 501 CDCS11_OptionalSlotCoor_P0_X "自选车位功能四角坐标信息";
CM_ SG_ 501 CDCS11_OptionalSlotCoor_P0_Y "自选车位功能四角坐标信息";
CM_ SG_ 501 CDCS11_OptionalSlotCoor_P1_X "自选车位功能四角坐标信息";
CM_ SG_ 501 CDCS11_OptionalSlotCoor_P1_Y "自选车位功能四角坐标信息";
CM_ SG_ 501 CDCS11_OptionalSlotCoor_P2_X "自选车位功能四角坐标信息";
CM_ SG_ 501 CDCS11_OptionalSlotCoor_P2_Y "自选车位功能四角坐标信息";
CM_ SG_ 501 CDCS11_OptionalSlotCoor_P3_X "自选车位功能四角坐标信息";
CM_ SG_ 501 CDCS11_OptionalSlotCoor_P3_Y "自选车位功能四角坐标信息";
CM_ SG_ 501 CDCS11_HPA_ONPath_ID1 "CDCS反馈选中记忆泊车路线ID1信号";
CM_ SG_ 501 CDCS11_HPA_ONPath_ID2 "CDCS反馈选中记忆泊车路线ID2信号";
CM_ SG_ 501 CDCS11_HPA_ONPath_ID3 "CDCS反馈选中记忆泊车路线ID3信号";
CM_ SG_ 501 CDCS11_HPA_ONPath_ID4 "CDCS反馈选中记忆泊车路线ID4信号";
CM_ SG_ 501 CDCS11_HPA_Select_ID "选择HPA路线ID";
CM_ SG_ 347 SWSM_A_CruiseDistance_Add "巡航跟车距离加开关";
CM_ SG_ 347 SWSM_A_CruiseDistance_Minus "巡航跟车距离减开关";
CM_ SG_ 347 SWSM_A_CruiseSpeed_Add "方向盘A区巡航车速+开关";
CM_ SG_ 347 SWSM_A_CruiseSpeed_Minus "方向盘A区巡航车速-开关";
CM_ SG_ 347 SWSM_A_SpeechInputSw "语音唤醒开关";
CM_ SG_ 347 Region_A_SwError "方向盘A区开关故障";
CM_ SG_ 347 SWSM_A_CD_Add_Overtime "CD加开关超时";
CM_ SG_ 347 SWSM_A_CD_Minus_Overtime "CD减开关超时";
CM_ SG_ 443 CDCS13_SwSmMode "CDCS周期性通知DDCU、PDCU和ADAS当前多功能方向盘控制功能所处的控制模式（默认模式/ARHUD模式/侧后视镜模式）";
CM_ SG_ 442 CDCS10_WorK_status "CDCS工作状态";
CM_ SG_ 706 EDU3_PumpPActSpd "水泵Pump_P实际转速";
CM_ SG_ 707 EDU4_PwrModeSts "动力系统热管理模式";
CM_ SG_ 707 EDU4_MotCoolgLoopSts "电驱冷却回路状态";
CM_ SG_ 469 EDU5_OperMod "EDU工作模式";
CM_ SG_ 997 EDU6_MotInpWtrT "电机进水口温度";
CM_ SG_ 769 ADCS_MDC1_FlowReq "MDC冷却液流速请求
MDC coolant flow rate reques";
CM_ SG_ 769 ADCS_MDC1_ThmPostRun "MDC延时散热需求标志请求
MDC delay heat dissipation requirement flag";
CM_ SG_ 230 RCU1_BrakePedalApplied "制动踏板踩下信号";
CM_ SG_ 230 RCU1_BrakePedalAppliedV "制动踏板踩下信号有效性";
CM_ SG_ 230 RCU1_BBS_ActiveSta "BBS(Basic brake boost) Active Status";
CM_ SG_ 230 RCU1_BrakPedalDisp "制动踏板位移量";
CM_ SG_ 230 RCU1_BrakPedalDisp_Q "制动踏板位移量有效性";
CM_ SG_ 230 RCU1_TrvSnsCalSts "踏板行程传感器零位标定状态";
CM_ SG_ 230 RCU1_BrkPedVal "踏板行程传感器角度";
CM_ SG_ 230 RCU1_BrkPedVal_vaild "踏板行程传感器角度有效性";
CM_ SG_ 230 RCU1_BBSFail "BBS(Basic brake boost) FAIL OR NOT";
CM_ SG_ 230 RCU1_FailedState "RCU故障及有效性";
CM_ SG_ 311 RCU2_FLWhlPulCnt "FL Wheel Pulse Counter";
CM_ SG_ 311 RCU2_FLWhlPulCntValid "FL Wheel Pulse Counter Validity";
CM_ SG_ 311 RCU2_FRWhlPulCnt "FR Wheel Pulse Counter";
CM_ SG_ 311 RCU2_FRWhlPulCntValid "FR Wheel Pulse Counter Validity";
CM_ SG_ 311 RCU2_Fr02_MsgCounter "E2E Profile2-CRC8H2F，Counter：0-15";
CM_ SG_ 311 RCU2_Fr02_Checksum "E2E Profile2-CRC8H2F
DataID List:#89 - 248 236 83 196 48 88 134 246 55 185 65 218 98 233 148 35";
CM_ SG_ 312 RCU3_VehicleSpd "Vehicle Speed 车速";
CM_ SG_ 312 RCU3_VehicleSpdValid "Vehicle Speed Status 车速有效位";
CM_ SG_ 312 RCU3_MasterCylPressure "主缸压力";
CM_ SG_ 312 RCU3_MasterCylPressureInvalid "主缸压力值有效性";
CM_ SG_ 312 RCU3_MsgCounter "E2E Profile2-CRC8H2F，Counter：0-15";
CM_ SG_ 312 RCU3_Checksum "E2E Profile2-CRC8H2F
DataID List:#90 - 67 142 179 96 108 128 85 172 75 20 40 61 244 29 60 238";
CM_ SG_ 313 RCU4_FLWhlVelocity "Wheel Ground Velocity FL";
CM_ SG_ 313 RCU4_FLWhlVelocityValid "Wheel Ground Velocity FL Valid";
CM_ SG_ 313 RCU4_FRWhlVelocity "Wheel Ground Velocity FR";
CM_ SG_ 313 RCU4_FRWhlVelocityValid "Wheel Ground Velocity FR Valid";
CM_ SG_ 313 RCU4_FRWhlDir "Wheel FR Directiion";
CM_ SG_ 313 RCU4_FLWhlDir "Wheel FL Directiion";
CM_ SG_ 313 RCU4_RLWhlDir "Wheel RL Directiion";
CM_ SG_ 313 RCU4_RRWhlDir "Wheel RR Directiion";
CM_ SG_ 313 RCU4_MsgCounter "E2E Profile2-CRC8H2F，Counter：0-15";
CM_ SG_ 313 RCU4_Checksum "E2E Profile2-CRC8H2F
DataID List:#10 - 4 65 1 42 110 208 168 45 211 25 191 226 12 167 122 106";
CM_ SG_ 313 RCU4_RLWhlVelocity "Wheel Ground Velocity RL";
CM_ SG_ 313 RCU4_RLWhlVelocityValid "Wheel Ground Velocity RL Valid";
CM_ SG_ 313 RCU4_RRWhlVelocity "Wheel Ground Velocity RR";
CM_ SG_ 313 RCU4_RRWhlVelocityValid "Wheel Ground Velocity RR Valid";
CM_ SG_ 313 RCU4_RLWhlPulCnt "RL Wheel Pulse Counter";
CM_ SG_ 313 RCU4_RRWhlPulCnt "RR Wheel Pulse Counter";
CM_ SG_ 313 RCU4_RLWhlPulCntValid "RL Wheel Pulse Counter Validity";
CM_ SG_ 313 RCU4_RRWhlPulCntValid "RR Wheel Pulse Counter Validity";
CM_ SG_ 317 RCU5_BrakeDiscTempSts "Over Temp status";
CM_ SG_ 317 RCU5_JerkActive "Jerk Active";
CM_ SG_ 317 RCU5_Jerkfail "Jerk fail";
CM_ SG_ 317 RCU5_ACC_ReqLim "Due to limitaion of the actuators the acceleration or deceleration request from FRM can not be processed or only partly";
CM_ SG_ 317 RCU5_ACC_ReferenceAccel "Feedback signal for the inner acceleration control loop";
CM_ SG_ 317 RCU5_ACC_Enable "This signal is set by the safety logic in the ESC.";
CM_ SG_ 317 RCU5_AEB_Enable "This signal is set by the safety logic for AEB in the ESC";
CM_ SG_ 317 RCU5_DriverOverride "Input signal which represents a driver accelerator/brake pedal press/release manipulation.";
CM_ SG_ 317 RCU5_MsgCounter "E2E Profile2-CRC8H2F，Counter：0-15";
CM_ SG_ 317 RCU5_Checksum "E2E Profile2-CRC8H2F
DataID List:#94 - 93 150 130 151 182 139 36 2 235 105 32 187 119 84 134 230";
CM_ SG_ 314 RCU6_EPB_ActuatorSt_R "Right EPB Actuator State
右Moc状态";
CM_ SG_ 314 RCU6_EPB_ActuatorSt_L "Left EPB Actuator State
左Moc状态";
CM_ SG_ 314 RCU6_EPBAvailable "Availability of EPB";
CM_ SG_ 314 RCU6_EPBStatus "EPB工作状态";
CM_ SG_ 314 RCU6_EPBCruiseCtrlCancelReq "Electric Park Brake Cruise Control Cancel Request";
CM_ SG_ 314 RCU6_EPBSysBrkLightsReq "Electric Park Brake System Brake Lights Requested";
CM_ SG_ 314 RCU6_EPBStatusLampReq "Electric Park Brake System Status Indication Request";
CM_ SG_ 314 RCU6_EPBWarnLampReq "Electric Park Brake System Warning Indication Request";
CM_ SG_ 314 RCU6_EPBClusterDispMSG "EPB Cluster Display Message";
CM_ SG_ 315 RCU7_TCSActive "Traction Control System Active";
CM_ SG_ 315 RCU7_TCSDisable "Traction Control System Driver Intent";
CM_ SG_ 315 RCU7_TCSFail "Traction Control System Fault";
CM_ SG_ 315 RCU7_AVHDispMSG "Auto Hold System Display Message";
CM_ SG_ 315 RCU7_AVHLampReq "Auto Hold System Lamp Request";
CM_ SG_ 315 RCU7_AVHEnabled "AVH功能使能";
CM_ SG_ 315 RCU7_HSAActive "坡道辅助";
CM_ SG_ 315 RCU7_HSAFail "坡道辅助故障";
CM_ SG_ 315 RCU7_BrkLightReq "ESC请求点亮制动灯";
CM_ SG_ 315 RCU7_ESSActiveReq "紧急制动信号，用于制动灯快闪";
CM_ SG_ 315 RCU7_ABSActive "Antilock Brake System Active";
CM_ SG_ 315 RCU7_ABSFail "Antilock Brake System Failed";
CM_ SG_ 315 RCU7_ESCFail "Electric Stability Control  Fault";
CM_ SG_ 315 RCU7_ESCActive "Electric Stability Control Active";
CM_ SG_ 315 RCU7_BrakeWarningLamp "汇总各种故障状态给仪表、安全气囊等控制器";
CM_ SG_ 315 RCU7_MsgCounter "E2E Profile2-CRC8H2F，Counter：0-15";
CM_ SG_ 315 RCU7_Checksum "E2E Profile2-CRC8H2F
DataID List:#25 - 126 6 203 143 54 16 127 211 84 240 121 189 236 210 56 224";
CM_ SG_ 316 RCU8_BrakeActive "Brake Active";
CM_ SG_ 316 RCU8_MsgCounter "E2E Profile2-CRC8H2F，Counter：0-15";
CM_ SG_ 316 RCU8_Checksum "E2E Profile2-CRC8H2F
DataID List:#27 - 114 177 90 184 43 119 50 223 95 237 29 234 232 83 63 215";
CM_ SG_ 318 RCU9_PA_CtrlAbortFeedback "ESC反馈泊车的终止原因";
CM_ SG_ 318 RCU9_PA_ParkingBrkMdSeln "ESC反馈当前制动模式";
CM_ SG_ 318 RCU9_PA_ParkingFnMd "ESC反馈当前功能模式";
CM_ SG_ 318 RCU9_PA_ParkingAvailable "当前是否满足泊车的状态信号";
CM_ SG_ 318 RCU9_PASts "ESC control state for APA";
CM_ SG_ 318 RCU9_PAStandStill "Stop confirmation signal during APA operation";
CM_ SG_ 318 RCU9_MsgCounter "E2E Profile2-CRC8H2F，Counter：0-15";
CM_ SG_ 318 RCU9_Checksum "E2E Profile2-CRC8H2F
DataID List:#98 - 22 54 31 240 170 56 42 118 219 32 201 247 48 45 199 131";
CM_ SG_ 765 HNS1_FaultSts "分断器故障状态";
CM_ SG_ 765 HNS1_VoltageSts "分断器电压状态";
CM_ SG_ 765 HNS1_CurrentSts "分断器电流状态";
CM_ SG_ 765 HNS1_MainSwSts "分断器主开关状态";
CM_ SG_ 765 HNS1_AliveCounter "E2E Profile2-CRC8H2F，Counter：0-15";
CM_ SG_ 765 HNS1_Checksum "E2E Profile2-CRC8H2F
DataID List:#11 - 125 130 213 139 180 235 221 187 162 134 199 78 95 229 53 123";
CM_ SG_ 765 HNS1_DCDCVol_status "DCDC侧电压有效性";
CM_ SG_ 765 HNS1_DCDCVol "DCDC侧电压值";
CM_ SG_ 765 HNS1_BatVol_status "Bat侧电压有效性";
CM_ SG_ 765 HNS1_BatVol "Bat侧电压值";
CM_ SG_ 765 HNS1_DCDCCur_status "DCDC侧电流有效性";
CM_ SG_ 765 HNS1_DCDCCur "DCDC侧电流";
CM_ SG_ 765 HNS1_BatCur_status "Bat侧电流有效性";
CM_ SG_ 765 HNS1_BatCur "Bat侧电流值";
CM_ SG_ 310 ADCS12_FCWWarnAudioplay "FCW报警类型语音播报";
CM_ SG_ 310 ADCS12_RCTAWarnAudioplay "RCTA报警类型语音播报";
CM_ SG_ 310 ADCS12_FCTAWarnAudioplay "FCTA报警类型语音播报";
CM_ SG_ 310 ADCS12_SpeedWarnAudioplay "超速语音播报";
CM_ SG_ 310 ADCS12_DOWWarnAudioplay "DOW报警类型语音播报";
CM_ SG_ 310 ADCS12_DCLCAudioplay "DCLC语音播报";
CM_ SG_ 310 ADCS12_PilotAudioPlay "Pilot语音播报";
CM_ SG_ 310 ADCS12_HandOffAudioplay "脱手语音播报";
CM_ SG_ 310 ADCS12_NNPCancelAudioPlay "NNP_cancel语音播报";
CM_ SG_ 310 ADCS12_RCWWarnAudioplay "RCW报警类型语音播报";
CM_ SG_ 310 ADCS12_MRMAudioPlay "MRM语音播报";
CM_ SG_ 310 ADCS12_NNP_ResumeAudioplay "NNP_Resume语音播报";
CM_ SG_ 310 ADCS12_Lcsndrequest "语音变道反馈";
CM_ SG_ 310 ADCS12_Lcsndrconfirm "主动变道驾驶员确认反馈";
CM_ SG_ 310 ADCS12_longitudDisableInfo "不可开启原因";
CM_ SG_ 310 ADCS12_DriveOffBroadcast "起步提醒播报";
CM_ SG_ 310 ADCS12_EyeOffBroadcast "脱眼语音播报";
CM_ SG_ 310 ADCS12_SpeedAdaptComfirm "速度匹配确认反馈信号";
CM_ SG_ 310 ADCS12_PayModeConfirm "收费站匹配确认反馈信号";
CM_ SG_ 310 ADCS12_longitudCtrlSysInfo "HMI文字显示";
CM_ SG_ 310 ADCS12_NPilotSysInfo "Npilot信息显示";
CM_ SG_ 310 ADCS12_ADAS_DriveOffinhibition "前车起步抑制请求";
CM_ SG_ 310 ADCS12_P2N_State_Reminder "NNP升降级状态";
CM_ SG_ 310 ADCS12_NNP_State_Reminder "NNP_语音状态提醒";
CM_ SG_ 310 ADCS12_NNP_LightRemind "NNP_语音提示关闭转向灯提醒";
CM_ SG_ 310 ADCS12_LCAudioPlay "变道语音提醒";
CM_ SG_ 310 ADCS12_NNP_Scenarios_AudioPlay "NNP所有场景语音提醒";
CM_ SG_ 310 ADCS12_LaneChangePendingAlert "变道等待超时提醒";
CM_ SG_ 310 ADCS12_NNP_RINO "NNP进入匝道相关提醒";
CM_ SG_ 1543 ADCS_SourceNodeIdentifier "ECU节点标识符";
CM_ SG_ 1543 ADCS_RepeatMessageRequest "Repeat Message请求";
CM_ SG_ 1543 ADCS_Reserve1 "预留";
CM_ SG_ 1543 ADCS_ActiveWakeup "激活唤醒，主动唤醒网络时置1，其他（包括被动唤醒节点）为0";
CM_ SG_ 1543 ADCS_Reserve2 "预留";
CM_ SG_ 1543 ADCS_WakeUp_KL15 "KL15 ON唤醒";
CM_ SG_ 1543 ADCS_WakeUp_NM "NM报文唤醒";
CM_ SG_ 1543 ADCS_WakeUp_GM "哨兵模式唤醒";
CM_ SG_ 1543 ADCS_WakeUpReason4 "网络唤醒原因4";
CM_ SG_ 1543 ADCS_WakeUpReason5 "网络唤醒原因5";
CM_ SG_ 1543 ADCS_WakeUpReason6 "网络唤醒原因6";
CM_ SG_ 1543 ADCS_WakeUpReason7 "网络唤醒原因7";
CM_ SG_ 1543 ADCS_WakeUpReason8 "网络唤醒原因8";
CM_ SG_ 1543 ADCS_RNM_DOW "DOW功能，需整车延迟休眠3min";
CM_ SG_ 1543 ADCS_RNM_GM "哨兵模式";
CM_ SG_ 1543 ADCS_RNM_ICS "智能寻车";
CM_ SG_ 1543 ADCS_RNM_RPA "遥控泊车";
CM_ SG_ 1543 ADCS_RNM_ISM "智能召唤";
BA_DEF_ SG_ "GenSigSendType" ENUM "Cycle","OnChange","OnWrite","IfActive","OnChangeWithRepetition","OnWriteWithRepetition","IfActiveWithRepetition","NoSigSendType","OnChangeAndIfActive","OnChangeAndIfActiveWithRepetition","CA","CE","Event","Cyclic";
BA_DEF_ SG_ "GenSigInactiveValue" HEX 0 0;
BA_DEF_ SG_ "GenSigStartValue" HEX 0 0;
BA_DEF_ SG_ "GenSigInvalidValue" HEX 0 0;
BA_DEF_ BO_ "CANFD_BRS" ENUM "0","1";
BA_DEF_ BO_ "GenMsgCycleTimeFast" INT 0 0;
BA_DEF_ BO_ "GenMsgSendType" ENUM "Cycle","NoMsgSendType","IfActive","Event","CA","CE","Cyclic";
BA_DEF_ BO_ "GenMsgNrOfRepetition" INT 0 0;
BA_DEF_ BO_ "GenMsgStartDelayTime" INT 0 0;
BA_DEF_ BO_ "GenMsgCycleTime" INT 0 0;
BA_DEF_ BO_ "GenMsgDelayTime" INT 0 0;
BA_DEF_ BO_ "NmMessage" ENUM "No","Yes";
BA_DEF_ BO_ "GenMsgILSupport" ENUM "No","Yes";
BA_DEF_ BO_ "VFrameFormat" ENUM "StandardCAN","ExtendedCAN","reserved","reserved","reserved","reserved","reserved","reserved","reserved","reserved","reserved","reserved","reserved","reserved","StandardCAN_FD","ExtendedCAN_FD";
BA_DEF_DEF_ "GenSigSendType" "Cycle";
BA_DEF_DEF_ "GenSigInactiveValue" 0;
BA_DEF_DEF_ "GenSigStartValue" 0;
BA_DEF_DEF_ "GenSigInvalidValue" 0;
BA_DEF_DEF_ "CANFD_BRS" "1";
BA_DEF_DEF_ "GenMsgCycleTimeFast" 0;
BA_DEF_DEF_ "GenMsgSendType" "Cycle";
BA_DEF_DEF_ "GenMsgNrOfRepetition" 0;
BA_DEF_DEF_ "GenMsgStartDelayTime" 0;
BA_DEF_DEF_ "GenMsgCycleTime" 100;
BA_DEF_DEF_ "GenMsgDelayTime" 0;
BA_DEF_DEF_ "NmMessage" "No";
BA_DEF_DEF_ "GenMsgILSupport" "Yes";
BA_DEF_DEF_ "VFrameFormat" "StandardCAN";
BA_ "GenMsgCycleTime" BO_ 143 10;
BA_ "VFrameFormat" BO_ 143 14;
BA_ "GenMsgCycleTime" BO_ 142 10;
BA_ "VFrameFormat" BO_ 142 14;
BA_ "VFrameFormat" BO_ 613 14;
BA_ "GenMsgCycleTime" BO_ 248 20;
BA_ "VFrameFormat" BO_ 248 14;
BA_ "GenMsgNrOfRepetition" BO_ 320 3;
BA_ "GenMsgCycleTime" BO_ 320 0;
BA_ "GenMsgCycleTimeFast" BO_ 320 20;
BA_ "GenMsgSendType" BO_ 320 3;
BA_ "VFrameFormat" BO_ 320 14;
BA_ "VFrameFormat" BO_ 559 14;
BA_ "GenMsgCycleTime" BO_ 418 50;
BA_ "VFrameFormat" BO_ 418 14;
BA_ "GenMsgCycleTime" BO_ 419 50;
BA_ "VFrameFormat" BO_ 419 14;
BA_ "GenMsgNrOfRepetition" BO_ 468 3;
BA_ "GenMsgCycleTime" BO_ 468 0;
BA_ "GenMsgCycleTimeFast" BO_ 468 20;
BA_ "GenMsgSendType" BO_ 468 3;
BA_ "VFrameFormat" BO_ 468 14;
BA_ "GenMsgCycleTime" BO_ 482 50;
BA_ "VFrameFormat" BO_ 482 14;
BA_ "GenMsgCycleTime" BO_ 484 50;
BA_ "VFrameFormat" BO_ 484 14;
BA_ "GenMsgCycleTime" BO_ 486 50;
BA_ "VFrameFormat" BO_ 486 14;
BA_ "VFrameFormat" BO_ 756 14;
BA_ "GenMsgCycleTime" BO_ 243 20;
BA_ "VFrameFormat" BO_ 243 14;
BA_ "GenMsgNrOfRepetition" BO_ 498 3;
BA_ "GenMsgCycleTime" BO_ 498 0;
BA_ "GenMsgCycleTimeFast" BO_ 498 50;
BA_ "GenMsgSendType" BO_ 498 2;
BA_ "VFrameFormat" BO_ 498 14;
BA_ "GenMsgCycleTime" BO_ 227 20;
BA_ "VFrameFormat" BO_ 227 14;
BA_ "VFrameFormat" BO_ 739 14;
BA_ "VFrameFormat" BO_ 724 14;
BA_ "GenMsgCycleTime" BO_ 251 20;
BA_ "VFrameFormat" BO_ 251 14;
BA_ "GenMsgCycleTime" BO_ 252 10;
BA_ "VFrameFormat" BO_ 252 14;
BA_ "GenMsgCycleTime" BO_ 264 20;
BA_ "VFrameFormat" BO_ 264 14;
BA_ "GenMsgCycleTime" BO_ 438 20;
BA_ "VFrameFormat" BO_ 438 14;
BA_ "VFrameFormat" BO_ 670 14;
BA_ "VFrameFormat" BO_ 645 14;
BA_ "VFrameFormat" BO_ 600 14;
BA_ "GenMsgNrOfRepetition" BO_ 501 3;
BA_ "GenMsgCycleTime" BO_ 501 0;
BA_ "GenMsgCycleTimeFast" BO_ 501 20;
BA_ "GenMsgSendType" BO_ 501 3;
BA_ "VFrameFormat" BO_ 501 14;
BA_ "GenMsgCycleTime" BO_ 347 50;
BA_ "VFrameFormat" BO_ 347 14;
BA_ "VFrameFormat" BO_ 443 14;
BA_ "GenMsgCycleTime" BO_ 442 50;
BA_ "VFrameFormat" BO_ 442 14;
BA_ "VFrameFormat" BO_ 706 14;
BA_ "VFrameFormat" BO_ 707 14;
BA_ "GenMsgCycleTime" BO_ 469 50;
BA_ "VFrameFormat" BO_ 469 14;
BA_ "GenMsgCycleTime" BO_ 997 500;
BA_ "VFrameFormat" BO_ 997 14;
BA_ "GenMsgCycleTime" BO_ 769 200;
BA_ "VFrameFormat" BO_ 769 14;
BA_ "GenMsgCycleTime" BO_ 230 10;
BA_ "VFrameFormat" BO_ 230 14;
BA_ "GenMsgCycleTime" BO_ 311 20;
BA_ "VFrameFormat" BO_ 311 14;
BA_ "GenMsgCycleTime" BO_ 312 10;
BA_ "VFrameFormat" BO_ 312 14;
BA_ "GenMsgCycleTime" BO_ 313 20;
BA_ "VFrameFormat" BO_ 313 14;
BA_ "GenMsgCycleTime" BO_ 317 20;
BA_ "VFrameFormat" BO_ 317 14;
BA_ "GenMsgCycleTime" BO_ 314 20;
BA_ "VFrameFormat" BO_ 314 14;
BA_ "GenMsgCycleTime" BO_ 315 20;
BA_ "VFrameFormat" BO_ 315 14;
BA_ "GenMsgCycleTime" BO_ 316 20;
BA_ "VFrameFormat" BO_ 316 14;
BA_ "GenMsgCycleTime" BO_ 318 20;
BA_ "VFrameFormat" BO_ 318 14;
BA_ "VFrameFormat" BO_ 765 14;
BA_ "GenMsgNrOfRepetition" BO_ 310 3;
BA_ "GenMsgCycleTime" BO_ 310 0;
BA_ "GenMsgCycleTimeFast" BO_ 310 20;
BA_ "GenMsgSendType" BO_ 310 3;
BA_ "VFrameFormat" BO_ 310 14;
BA_ "GenMsgCycleTime" BO_ 1543 500;
BA_ "NmMessage" BO_ 1543 1;
BA_ "GenSigStartValue" SG_ 143 ADCS11_PA_EPSAngleReq 7200;
BA_ "GenSigInvalidValue" SG_ 143 ADCS11_PA_TarDecel 4095;
BA_ "GenSigStartValue" SG_ 143 ADCS11_PA_TarDecel 2048;
BA_ "GenSigInvalidValue" SG_ 143 ADCS11_PA_TorqReqValue 2047;
BA_ "GenSigStartValue" SG_ 143 ADCS11_PA_TorqReqValue 1023;
BA_ "GenSigInvalidValue" SG_ 143 ADCS11_HPA_Pathavailable_ID1 255;
BA_ "GenSigInvalidValue" SG_ 143 ADCS11_HPA_Pathavailable_ID2 255;
BA_ "GenSigInvalidValue" SG_ 143 ADCS11_HPA_distance 4095;
BA_ "GenSigInvalidValue" SG_ 143 ADCS11_Parkingtimeremaining 1023;
BA_ "GenSigInvalidValue" SG_ 143 ADCS11_NNS_distance 65535;
BA_ "GenSigInvalidValue" SG_ 143 ADCS11_PA_IDB_TorqReqValue 4095;
BA_ "GenSigStartValue" SG_ 143 ADCS11_PA_IDB_TorqReqValue 4095;
BA_ "GenSigInvalidValue" SG_ 143 ADCS11_HPA_learnpathdistance 1023;
BA_ "GenSigStartValue" SG_ 142 ADCS2_ADAS_EPSAngleReq 7200;
BA_ "GenSigStartValue" SG_ 142 ADCS2_AEBTargetDeceleration 127;
BA_ "GenSigSendType" SG_ 320 CDCS3_ESCOffSw 5;
BA_ "GenSigSendType" SG_ 320 CDCS3_HDCSw 5;
BA_ "GenSigSendType" SG_ 320 CDCS3_DriveModeSet 5;
BA_ "GenSigStartValue" SG_ 320 CDCS3_Xcoordinate 65535;
BA_ "GenSigSendType" SG_ 320 CDCS3_Xcoordinate 5;
BA_ "GenSigStartValue" SG_ 320 CDCS3_Ycoordinate 65535;
BA_ "GenSigSendType" SG_ 320 CDCS3_Ycoordinate 5;
BA_ "GenSigStartValue" SG_ 320 CDCS3_XGestureSpd 255;
BA_ "GenSigSendType" SG_ 320 CDCS3_XGestureSpd 5;
BA_ "GenSigStartValue" SG_ 320 CDCS3_YGestureSpd 255;
BA_ "GenSigSendType" SG_ 320 CDCS3_YGestureSpd 5;
BA_ "GenSigSendType" SG_ 320 CDCS3_TouchEvtTyp 5;
BA_ "GenSigInvalidValue" SG_ 418 DDCU1_FL_WinPos 255;
BA_ "GenSigInvalidValue" SG_ 418 DDCU1_RL_WinPos 255;
BA_ "GenSigInvalidValue" SG_ 419 PDCU1_FR_WinPos 255;
BA_ "GenSigInvalidValue" SG_ 419 PDCU1_RR_WinPos 255;
BA_ "GenSigSendType" SG_ 468 CDCS5_ResetAllSetup 5;
BA_ "GenSigSendType" SG_ 468 CDCS5_FactoryReset 5;
BA_ "GenSigInvalidValue" SG_ 482 BDCS4_FLTyre_Pressure 255;
BA_ "GenSigInvalidValue" SG_ 482 BDCS4_FLTyre_Temperature 255;
BA_ "GenSigInvalidValue" SG_ 482 BDCS4_FRTyre_Pressure 255;
BA_ "GenSigInvalidValue" SG_ 482 BDCS4_FRTyre_Temperature 255;
BA_ "GenSigInvalidValue" SG_ 484 BDCS5_RLTyre_Pressure 255;
BA_ "GenSigInvalidValue" SG_ 484 BDCS5_RLTyre_Temperature 255;
BA_ "GenSigInvalidValue" SG_ 484 BDCS5_RRTyre_Pressure 255;
BA_ "GenSigInvalidValue" SG_ 484 BDCS5_RRTyre_Temperature 255;
BA_ "GenSigSendType" SG_ 498 BTM3_RKECmd 3;
BA_ "GenSigStartValue" SG_ 264 VCU4_PA_TargetTrqValue 800;
BA_ "GenSigSendType" SG_ 501 CDCS11_LKSSetspeed 5;
BA_ "GenSigSendType" SG_ 501 CDCS11_LDW_OnOffSet 5;
BA_ "GenSigSendType" SG_ 501 CDCS11_LowSpeedBSDSw 5;
BA_ "GenSigSendType" SG_ 501 CDCS11_FCW_OnOffSet 5;
BA_ "GenSigSendType" SG_ 501 CDCS11_AEB_OnOffSet 5;
BA_ "GenSigSendType" SG_ 501 CDCS11_FCW_WarnTiming 5;
BA_ "GenSigSendType" SG_ 501 CDCS11_FCTA_OnOffSet 5;
BA_ "GenSigSendType" SG_ 501 CDCS11_RCTA_OnOffSet 5;
BA_ "GenSigSendType" SG_ 501 CDCS11_RCW_OnOffSet 5;
BA_ "GenSigSendType" SG_ 501 CDCS11_DOW_OnOffSet 5;
BA_ "GenSigSendType" SG_ 501 CDCS11_IHBC_SysSwState 5;
BA_ "GenSigSendType" SG_ 501 CDCS11_LCA_OnOffSet 5;
BA_ "GenSigSendType" SG_ 501 CDCS11_TSR_OnOffSet 5;
BA_ "GenSigSendType" SG_ 501 CDCS11_AVM_3DRotate 5;
BA_ "GenSigSendType" SG_ 501 CDCS11_AVM_Turnlightstart 5;
BA_ "GenSigSendType" SG_ 501 CDCS11_AVM_Steeringstart 5;
BA_ "GenSigSendType" SG_ 501 CDCS11_AVM_Magnifiedview 5;
BA_ "GenSigSendType" SG_ 501 CDCS11_AVM_MODdetection 5;
BA_ "GenSigSendType" SG_ 501 CDCS11_GM_OnOffSet 5;
BA_ "GenSigSendType" SG_ 501 CDCS11_NNP_OnOffSet 5;
BA_ "GenSigSendType" SG_ 501 CDCS11_DCLCSysState 5;
BA_ "GenSigSendType" SG_ 501 CDCS11_ALCSysState 5;
BA_ "GenSigSendType" SG_ 501 CDCS11_DriveOffPossilbeswitch 5;
BA_ "GenSigSendType" SG_ 501 CDCS11_DriveOffinhibitionswitch 5;
BA_ "GenSigSendType" SG_ 501 CDCS11_ADAS_SndCtrlOnOff 5;
BA_ "GenSigSendType" SG_ 501 CDCS11_AVM_auxiliaryline 5;
BA_ "GenSigSendType" SG_ 501 CDCS11_AVM_Raderdisplay 5;
BA_ "GenSigSendType" SG_ 501 CDCS11_AVM_Transparentchassis 5;
BA_ "GenSigSendType" SG_ 501 CDCS11_VoiceMode 5;
BA_ "GenSigSendType" SG_ 501 CDCS11_NNP_Active_OnOffSet 5;
BA_ "GenSigSendType" SG_ 501 CDCS11_ALC_mode 5;
BA_ "GenSigSendType" SG_ 501 CDCS11_ADSDriving_mode 5;
BA_ "GenSigSendType" SG_ 501 CDCS11_TSR_OverspeedOnoffSet 5;
BA_ "GenSigSendType" SG_ 501 CDCS11_NNP_AutoOnOffSet 5;
BA_ "GenSigSendType" SG_ 501 CDCS11_SnCtrl_NNP_OnOff 5;
BA_ "GenSigSendType" SG_ 501 CDCS11_GM_VidedIn 5;
BA_ "GenSigSendType" SG_ 501 CDCS11_TSR_SLFOnOffSet 5;
BA_ "GenSigSendType" SG_ 501 CDCS11_APA_FunctionMode 5;
BA_ "GenSigSendType" SG_ 501 CDCS11_TrackreverseSW 5;
BA_ "GenSigSendType" SG_ 501 CDCS11_SetPathwaySW 5;
BA_ "GenSigSendType" SG_ 501 CDCS11_PA_changeLanguage 5;
BA_ "GenSigSendType" SG_ 501 CDCS11_LDP_OnOffSet 5;
BA_ "GenSigSendType" SG_ 501 CDCS11_AVMSw 5;
BA_ "GenSigSendType" SG_ 501 CDCS11_tryHPP 5;
BA_ "GenSigSendType" SG_ 501 CDCS11_RPASw 5;
BA_ "GenSigSendType" SG_ 501 CDCS11_SetSw 5;
BA_ "GenSigSendType" SG_ 501 CDCS11_SoundCtrlSetReq 5;
BA_ "GenSigSendType" SG_ 501 CDCS11_location_sw 5;
BA_ "GenSigSendType" SG_ 501 CDCS11_Pathrefresh 5;
BA_ "GenSigSendType" SG_ 501 CDCS11_HPAGuideSW 5;
BA_ "GenSigSendType" SG_ 501 CDCS11_HPAPathwaytoCloudSW 5;
BA_ "GenSigSendType" SG_ 501 CDCS11_PathlearningSw 5;
BA_ "GenSigSendType" SG_ 501 CDCS11_PA_screenMd 5;
BA_ "GenSigSendType" SG_ 501 CDCS11_PASw 5;
BA_ "GenSigSendType" SG_ 501 CDCS11_PA_Recover 5;
BA_ "GenSigSendType" SG_ 501 CDCS_Lcsndrequest 5;
BA_ "GenSigSendType" SG_ 501 CDCS_Lcsndconfirm 5;
BA_ "GenSigSendType" SG_ 501 CDCS_SpdAdaptComfirm 5;
BA_ "GenSigSendType" SG_ 501 CDCS_PayModeConfirm 5;
BA_ "GenSigSendType" SG_ 501 CDCS11_SelectSlotID 5;
BA_ "GenSigSendType" SG_ 501 CDCS11_ParkingInReq 5;
BA_ "GenSigSendType" SG_ 501 CDCS11_ParkingOutReq 5;
BA_ "GenSigSendType" SG_ 501 CDCS11_AVM_ViewMode 5;
BA_ "GenSigSendType" SG_ 501 CDCS11_RPA_FunctionMode 5;
BA_ "GenSigSendType" SG_ 501 CDCS11_AVM_VideoOutputFail 5;
BA_ "GenSigSendType" SG_ 501 CDCS11_AVM_Initialization 5;
BA_ "GenSigSendType" SG_ 501 CDCS11_AVM_bodySync 5;
BA_ "GenSigSendType" SG_ 501 CDCS11_AVM_SpeView 5;
BA_ "GenSigSendType" SG_ 501 CDCS11_AVM_licenseplateabbr 5;
BA_ "GenSigSendType" SG_ 501 CDCS11_AVM_licenseplateArea 5;
BA_ "GenSigSendType" SG_ 501 CDCS11_AVM_StartMode 5;
BA_ "GenSigSendType" SG_ 501 CDCS11_AVM_LicensePlateNO1 5;
BA_ "GenSigSendType" SG_ 501 CDCS11_ELK_OnOffSet 5;
BA_ "GenSigSendType" SG_ 501 CDCS11_AVM_LicensePlateNO2 5;
BA_ "GenSigSendType" SG_ 501 CDCS11_AVM_LicensePlateNO3 5;
BA_ "GenSigSendType" SG_ 501 CDCS11_DCWposition 5;
BA_ "GenSigSendType" SG_ 501 CDCS11_AVM_LicensePlateNO4 5;
BA_ "GenSigSendType" SG_ 501 CDCS11_FindCarAvmReq 5;
BA_ "GenSigSendType" SG_ 501 CDCS11_AVM_LicensePlateNO5 5;
BA_ "GenSigSendType" SG_ 501 CDCS11_AVM_LicensePlateNO6 5;
BA_ "GenSigSendType" SG_ 501 CDCS11_AVM_LicensePlateNO7 5;
BA_ "GenSigSendType" SG_ 501 CDCS11_AVM_LicensePlateNO8 5;
BA_ "GenSigSendType" SG_ 501 CDCS11_AVM_Powertype 5;
BA_ "GenSigSendType" SG_ 501 CDCS11_AVM_Diaphaneity 5;
BA_ "GenSigSendType" SG_ 501 CDCS11_AVM_DiaphaneitySw 5;
BA_ "GenSigSendType" SG_ 501 CDCS11_MOD_Sound_Sw 5;
BA_ "GenSigSendType" SG_ 501 CDCS11_MOD_BSD_Sw 5;
BA_ "GenSigSendType" SG_ 501 CDCS11_PA_FRS_OnOffSet 5;
BA_ "GenSigSendType" SG_ 501 CDCS11_PA_3D_OnOffSet 5;
BA_ "GenSigSendType" SG_ 501 CDCS11_PA_measure_OnOffSet 5;
BA_ "GenSigSendType" SG_ 501 CDCS11_MODSw 5;
BA_ "GenSigSendType" SG_ 501 CDCS11_VoiceNotifFrequency_mode 5;
BA_ "GenSigSendType" SG_ 501 CDCS11_ACCOnOffSet 5;
BA_ "GenSigSendType" SG_ 501 CDCS11_HPASw 5;
BA_ "GenSigSendType" SG_ 501 CDCS11_DeleteMapID 5;
BA_ "GenSigSendType" SG_ 501 CDCS11_UploadMapID 5;
BA_ "GenSigSendType" SG_ 501 CDCS11_HPAActiveConfirm 5;
BA_ "GenSigSendType" SG_ 501 CDCS11_HPApreparkingSw 5;
BA_ "GenSigSendType" SG_ 501 CDCS11_HPAPathwaytoCloud_WorkSts 5;
BA_ "GenSigSendType" SG_ 501 CDCS11_PA_Select_ID 5;
BA_ "GenSigSendType" SG_ 501 CDCS11_learnpath_St 5;
BA_ "GenSigSendType" SG_ 501 CDCS11_ParkingoutSlot_Type 5;
BA_ "GenSigSendType" SG_ 501 CDCS11_ParkingoutSlot_Dire 5;
BA_ "GenSigSendType" SG_ 501 CDCS11_OptionalSlot_Type 5;
BA_ "GenSigSendType" SG_ 501 CDCS11_OptionalSlot_Dire 5;
BA_ "GenSigSendType" SG_ 501 CDCS11_OptionalSlotAngle 5;
BA_ "GenSigSendType" SG_ 501 CDCS11_OptionalSlotCoor_P0_X 5;
BA_ "GenSigSendType" SG_ 501 CDCS11_OptionalSlotCoor_P0_Y 5;
BA_ "GenSigSendType" SG_ 501 CDCS11_OptionalSlotCoor_P1_X 5;
BA_ "GenSigSendType" SG_ 501 CDCS11_OptionalSlotCoor_P1_Y 5;
BA_ "GenSigSendType" SG_ 501 CDCS11_OptionalSlotCoor_P2_X 5;
BA_ "GenSigSendType" SG_ 501 CDCS11_OptionalSlotCoor_P2_Y 5;
BA_ "GenSigSendType" SG_ 501 CDCS11_OptionalSlotCoor_P3_X 5;
BA_ "GenSigSendType" SG_ 501 CDCS11_OptionalSlotCoor_P3_Y 5;
BA_ "GenSigSendType" SG_ 501 CDCS11_HPA_ONPath_ID1 5;
BA_ "GenSigSendType" SG_ 501 CDCS11_HPA_ONPath_ID2 5;
BA_ "GenSigSendType" SG_ 501 CDCS11_HPA_ONPath_ID3 5;
BA_ "GenSigSendType" SG_ 501 CDCS11_HPA_ONPath_ID4 5;
BA_ "GenSigSendType" SG_ 501 CDCS11_HPA_Select_ID 5;
BA_ "GenSigStartValue" SG_ 997 EDU6_MotInpWtrT 68;
BA_ "GenSigStartValue" SG_ 769 ADCS_MDC1_FlowReq 2;
BA_ "GenSigStartValue" SG_ 230 RCU1_BrakPedalDisp 400;
BA_ "GenSigInvalidValue" SG_ 311 RCU2_FLWhlPulCnt 65535;
BA_ "GenSigInvalidValue" SG_ 311 RCU2_FRWhlPulCnt 65535;
BA_ "GenSigInvalidValue" SG_ 312 RCU3_MasterCylPressure 65535;
BA_ "GenSigStartValue" SG_ 312 RCU3_MasterCylPressure 3000;
BA_ "GenSigInvalidValue" SG_ 313 RCU4_FLWhlVelocity 16383;
BA_ "GenSigInvalidValue" SG_ 313 RCU4_FRWhlVelocity 16383;
BA_ "GenSigInvalidValue" SG_ 313 RCU4_RLWhlVelocity 16383;
BA_ "GenSigInvalidValue" SG_ 313 RCU4_RRWhlVelocity 16383;
BA_ "GenSigInvalidValue" SG_ 313 RCU4_RLWhlPulCnt 65535;
BA_ "GenSigInvalidValue" SG_ 313 RCU4_RRWhlPulCnt 65535;
BA_ "GenSigStartValue" SG_ 317 RCU5_ACC_ReferenceAccel 1023;
BA_ "GenSigInvalidValue" SG_ 765 HNS1_MainSwSts 3;
BA_ "GenSigSendType" SG_ 310 ADCS12_FCWWarnAudioplay 4;
BA_ "GenSigSendType" SG_ 310 ADCS12_RCTAWarnAudioplay 4;
BA_ "GenSigSendType" SG_ 310 ADCS12_FCTAWarnAudioplay 4;
BA_ "GenSigSendType" SG_ 310 ADCS12_SpeedWarnAudioplay 4;
BA_ "GenSigSendType" SG_ 310 ADCS12_DOWWarnAudioplay 4;
BA_ "GenSigSendType" SG_ 310 ADCS12_DCLCAudioplay 4;
BA_ "GenSigSendType" SG_ 310 ADCS12_PilotAudioPlay 4;
BA_ "GenSigSendType" SG_ 310 ADCS12_HandOffAudioplay 4;
BA_ "GenSigSendType" SG_ 310 ADCS12_NNPCancelAudioPlay 4;
BA_ "GenSigSendType" SG_ 310 ADCS12_RCWWarnAudioplay 4;
BA_ "GenSigSendType" SG_ 310 ADCS12_MRMAudioPlay 4;
BA_ "GenSigSendType" SG_ 310 ADCS12_NNP_ResumeAudioplay 4;
BA_ "GenSigSendType" SG_ 310 ADCS12_Lcsndrequest 4;
BA_ "GenSigSendType" SG_ 310 ADCS12_Lcsndrconfirm 4;
BA_ "GenSigSendType" SG_ 310 ADCS12_longitudDisableInfo 4;
BA_ "GenSigSendType" SG_ 310 ADCS12_DriveOffBroadcast 4;
BA_ "GenSigSendType" SG_ 310 ADCS12_EyeOffBroadcast 4;
BA_ "GenSigSendType" SG_ 310 ADCS12_SpeedAdaptComfirm 4;
BA_ "GenSigSendType" SG_ 310 ADCS12_PayModeConfirm 4;
BA_ "GenSigSendType" SG_ 310 ADCS12_longitudCtrlSysInfo 4;
BA_ "GenSigSendType" SG_ 310 ADCS12_NPilotSysInfo 4;
BA_ "GenSigSendType" SG_ 310 ADCS12_ADAS_DriveOffinhibition 4;
BA_ "GenSigSendType" SG_ 310 ADCS12_P2N_State_Reminder 4;
BA_ "GenSigSendType" SG_ 310 ADCS12_NNP_State_Reminder 4;
BA_ "GenSigSendType" SG_ 310 ADCS12_NNP_LightRemind 4;
BA_ "GenSigSendType" SG_ 310 ADCS12_LCAudioPlay 4;
BA_ "GenSigSendType" SG_ 310 ADCS12_NNP_Scenarios_AudioPlay 4;
BA_ "GenSigSendType" SG_ 310 ADCS12_LaneChangePendingAlert 4;
BA_ "GenSigSendType" SG_ 310 ADCS12_NNP_RINO 4;
VAL_ 143 ADCS11_PA_GearReq 1 "Request" 0 "No request";
VAL_ 143 ADCS11_PA_GearPosReqVail 1 "Valid" 0 "Invalid";
VAL_ 143 ADCS11_PA_prefillReq 1 "Request" 0 "No request";
VAL_ 143 ADCS11_PA_GearPosReq 7 "Reserved" 5 "Reserved" 4 "D" 3 "N" 2 "R" 1 "P" 0 "No request";
VAL_ 143 ADCS11_PA_BrakemodeReq 2 "Emergency Brake Active" 1 "Comfort Brake Active" 0 "Function Not Active";
VAL_ 143 ADCS11_PA_EpbReq 3 "Reserve" 2 "apply request" 1 "Release request" 0 "No request";
VAL_ 143 ADCS11_PA_lampreq 3 "Hazard Lamp Request" 2 "Right Turn Lamp Request" 1 "Left Turn Lamp  Request " 0 "No Request";
VAL_ 143 ADCS11_PA_StopDistanceValid 1 "valid" 0 "Invalid";
VAL_ 143 ADCS11_Parking_WorkSts 15 "Invalid" 11 "Cruising（AVP）" 10 "Failure" 9 "Abort" 8 "Suspend" 7 "Complete" 6 "Localization" 5 "Map building" 4 "Cruising（HPP）" 3 " Parking" 2 "TBA standby" 1 "Standby(通过开关进入PA)" 0 "off";
VAL_ 143 ADCS11_PA_Recover 1 "Recovered" 0 "No Request";
VAL_ 143 ADCS11_RPA_RemoteParkAppStartReq 1 "Request" 0 "No Request";
VAL_ 143 ADCS11_TurnLampReq 3 "HazardLamp on" 2 "right turn lamp on" 1 "left turn lamp on" 0 "off";
VAL_ 143 ADCS11_SetPathwayWorkSts 2 "off" 1 "on" 0 "No Request";
VAL_ 143 ADCS11_HPAGuideSts 4 "Reserved" 3 "Reserved" 2 "Located" 1 "Relocation" 0 "Normal";
VAL_ 143 ADCS11_PA_IDBControlReq 3 " Failed" 2 " Assist" 1 "Ready" 0 "Off";
VAL_ 143 ADCS11_HPA_WorkSts 7 "Failed" 6 "Abort" 5 "Suspend" 4 "Finished" 3 "Active" 2 "Enable" 1 "Standby" 0 "Off";
VAL_ 143 ADCS11_PA_IDBControlReqV 1 "valid" 0 "Invalid";
VAL_ 143 ADCS11_PA_EPSAngleReqSt 1 "Request" 0 "No request";
VAL_ 143 ADCS11_PA_EPSAngleReqV 1 "Valid" 0 "Invalid";
VAL_ 143 ADCS11_PrkngFctnModeReq 7 "reserved" 6 "TAB" 5 "ISM" 4 "AVP" 3 "HPP" 2 "RPA" 1 "FAPA" 0 "Off";
VAL_ 143 ADCS11_HPAPathlearning_WorkSts 7 "Failed" 6 "Abort" 5 "Suspend" 4 "Finished" 3 "Active" 2 "Enable" 1 "Standby" 0 "Off";
VAL_ 143 ADCS11_HPAPathwaytoCloud_WorkSts 7 "Reserve" 6 "Reserve" 5 "Reserve" 4 "Reserve" 3 "Uploading error" 2 "Uploading" 1 "Uploaded" 0 "To be uploaded";
VAL_ 143 ADCS11_TrackreverseWorkSts 7 "Failed" 6 "Abort" 5 "Suspend" 4 "Finished" 3 "Active" 2 "Enable" 1 "Standby" 0 "Off";
VAL_ 143 ADCS11_Currentgear 2 "Gear R" 1 "Gear D" 0 "No Request";
VAL_ 143 ADCS11_PA_Pause_Recover 3 "reserved" 2 " recover " 1 "Pause" 0 "No request";
VAL_ 143 ADCS11_PA_ParkingFnMd 3 "AVP_Cruising" 2 "Cruising" 1 "   Parking" 0 "   No Request";
VAL_ 143 ADCS11_PA_TarDecelreq 1 "Request" 0 "No Request";
VAL_ 143 ADCS11_HPA_BacktoEntrance 1 "Request" 0 "No request";
VAL_ 143 ADCS11_HPA_BacktoStart 1 "Request" 0 "No request";
VAL_ 143 ADCS11_PA_TorqReq 1 "Request" 0 "No request";
VAL_ 143 ADCS11_PA_TorqReqValidity 1 "Valid" 0 "Invalid";
VAL_ 143 ADCS11_PA_screenReq 9 "TAB" 8 "ISM " 7 "AVP " 6 "HPP " 5 "RPA " 4 "FAPA " 3 "AVM" 2 "RVC" 1 "PDC" 0 "No Request";
VAL_ 143 ADCS11_APA_RemoteStartReq 1 "Request" 0 "No request";
VAL_ 143 ADCS11_APA_RemoteShutdownReq 1 "Request" 0 "No request";
VAL_ 143 ADCS11_MirrorFoldrequest 2 "Fold" 1 "Unfold" 0 "No request";
VAL_ 143 ADCS11_APA_FLWindowsCtrl 5 "通风" 4 "Auto Down" 3 "Auto Up" 2 "Manual Down" 1 "Manual Up" 0 "No request";
VAL_ 143 ADCS11_APA_RemoteLockCtrl 3 "寻车" 2 "Unlock" 1 "Lock" 0 "No request";
VAL_ 143 ADCS11_APA_FRWindowsCtrl 5 "通风" 4 "Auto Down" 3 "Auto Up预留" 2 "Manual Down" 1 "Manual Up" 0 "No request";
VAL_ 143 ADCS11_APA_RLWindowsCtrl 5 "通风" 4 "Auto Down" 3 "Auto Up预留" 2 "Manual Down" 1 "Manual Up" 0 "No request";
VAL_ 143 ADCS11_APA_RRWindowsCtrl 5 "通风" 4 "Auto Down" 3 "Auto Up预留" 2 "Manual Down" 1 "Manual Up" 0 "No request";
VAL_ 143 ADCS11_APA_requestMirrorFoldSt 2 "Fold" 1 "Unfold" 0 "No request";
VAL_ 143 ADCS11_PA_StopReq 1 " Stop control is required" 0 " No request ";
VAL_ 143 ADCS11_HPA_PathlearningSt 2 "complete" 1 "learning" 0 "Noaction";
VAL_ 143 ADCS11_HPA_Path_exist 3 "A   certain  distance" 2 "exist" 1 "inexistence" 0 "Noaction";
VAL_ 143 ADCS11_HPA_Pathavailable_ID1 0 "default";
VAL_ 143 ADCS11_HPA_Pathavailable_ID2 0 "default";
VAL_ 143 ADCS11_HPA_distance 4095 "invalid";
VAL_ 143 ADCS11_Parkingtimeremaining 1023 "invalid";
VAL_ 143 ADCS11_PA_PickSt 1 "active" 0 "Noaction";
VAL_ 143 ADCS11_NNS_distance 65535 "invaild";
VAL_ 143 ADCS11_HighBeam 3 "Flash" 2 "OFF" 1 "ON" 0 "No request";
VAL_ 143 ADCS11_LowBeam 2 "Request Off" 1 "Request On" 0 "No request";
VAL_ 143 ADCS11_ReqPwmode 2 "Power off" 1 "Power on   " 0 "No request  ";
VAL_ 143 ADCS11_SecuritySts 3 "Reserved" 2 "In security  status" 1 "Not in Security status" 0 "Initial value";
VAL_ 143 ADCS11_PA_IDB_TorqReqValidity 1 " Valid" 0 " Invalid";
VAL_ 143 ADCS11_HPA_learnpathdistance 0 "Default";
VAL_ 142 ADCS2_ADAS_EPSAngleReqSt 1 "Requested" 0 "No Request";
VAL_ 142 ADCS2_EPS_LDPState 4 "LDP passive" 3 "LDP Fail" 2 "LDP Active" 1 "LDP Standby" 0 "Off";
VAL_ 142 ADCS2_NNP_SystemFaultStatus 3 "Service Required" 2 "System Temporary Unvailable" 1 "Performance Degradation" 0 "No Error";
VAL_ 142 ADCS2_ADAS_EPSLateralCtrlType 7 "Reserved" 5 "Reserved" 4 " ELK Mode" 3 "NNP Mode" 2 "Pilot Mode" 1 "LDP Mode" 0 "None";
VAL_ 142 ADCS_Pilot_SystemFaultStatus 3 "Service Required" 2 "System Temporary Unvailable" 1 "Performance Degradation" 0 "No Error";
VAL_ 142 ADCS2_ADSDriving_mode 2 "Radical" 1 "Normal" 0 "Basic";
VAL_ 142 ADCS2_ADAS_IHBCSysState 4 "System Failure" 3 "IHBC On & High Beam On" 2 "IHBC On & High Beam Off" 1 "Standby&passive" 0 "IHBC Off";
VAL_ 142 ADCS2_ALCDirection 4 "  Warning Light" 3 "Shutdown" 2 "Right" 1 "Left" 0 "Off";
VAL_ 142 ADCS2_EPS_ELKState 4 "ELK Fail" 3 "ELK Active" 2 "ELK Standby" 1 "ELK passive" 0 "Off";
VAL_ 142 ADCS2_AEB_JerkReq 1 "Request" 0 "No request";
VAL_ 142 ADCS2_AEBPrefillReq 1 "Requested" 0 "No Request";
VAL_ 142 ADCS2_AEB_DBSLevel 3 "DBS level 3" 2 "DBS level 2" 1 "DBS level 1" 0 "No activation";
VAL_ 142 ADCS2_AEBPartialBrake 1 "Requested" 0 "No Request";
VAL_ 142 ADCS2_AEBFullBrake 1 "Requested" 0 "No Request";
VAL_ 142 ADCS2_AEBVehicleHoldReq 1 "Requested" 0 "No Request";
VAL_ 142 ADCS2_longitudCtrlType 3 "NNP Mode" 2 "NPilot Mode" 1 "ACC Mode" 0 "None";
VAL_ 142 ADCS2_LongitudCtrlDecToStopReq 1 "Requested" 0 "No Request";
VAL_ 142 ADCS2_LongitudCtrlDriveOff 1 "Requested" 0 "No Request";
VAL_ 142 ADCS2_AEB_JerkLevel 3 "Jerk  level 3" 2 "Jerk  level 2" 1 "Jerk level 1" 0 "No activation";
VAL_ 142 ADCS2_LongitudCtrlAccelCtrlReq 1 "Requested" 0 "No Request";
VAL_ 613 ADCS1_CarMdlDispSts 1 "3D mode" 0 "2D mode";
VAL_ 613 ADCS1_GuidOvlDispSts 3 "N无轨迹线" 2 "仅后视角显示轨迹线" 1 "仅环视轨迹线" 0 "全部视角+轨迹线";
VAL_ 613 ADCS1_MOD_WorkSts 1 "ON" 0 "OFF";
VAL_ 613 ADCS1_MOD_AlarmSts 1 "ON" 0 "OFF";
VAL_ 613 ADCS1_CarMdlTrsprcySts 3 "Reserved" 2 "Completely Transparent" 1 "Translucent" 0 "Opaque";
VAL_ 613 ADCS1_AutoViewChgFuncSts 1 "ON" 0 "OFF";
VAL_ 613 ADCS1_SigViewIndcn 3 "右视角" 2 "左视角" 1 "后视角" 0 "前视角";
VAL_ 613 ADCS1_AutoAVMSwtSet_Sts 1 "ON" 0 "OFF";
VAL_ 320 CDCS3_ESCOffSw 3 "Reserved" 2 "OFF " 1 "ON " 0 "No Action ";
VAL_ 320 CDCS3_HDCSw 3 "Reserved" 2 "OFF " 1 "ON " 0 "No Action ";
VAL_ 320 CDCS3_DriveModeSet 4 "LAUNCH" 3 "CONFORM" 2 "SPORT" 1 "ECO" 0 "No Action";
VAL_ 320 CDCS3_Xcoordinate 0 "No Action";
VAL_ 320 CDCS3_Ycoordinate 0 "No Action";
VAL_ 320 CDCS3_XGestureSpd 0 "No Action";
VAL_ 320 CDCS3_YGestureSpd 0 "No Action";
VAL_ 320 CDCS3_TouchEvtTyp 10 "Rotate" 9 "Zoom out" 8 "Zoom in" 7 "One finger swipe" 6 "One finger moving" 5 "One finger long press" 4 "One finger double click" 3 "One finger single click" 2 "One finger up" 1 "One finger down" 0 "No Action";
VAL_ 418 DDCU1_FLDoorAjar 3 "Unknow" 2 "Open" 1 "Secondary" 0 "Closed";
VAL_ 418 DDCU1_RLDoorAjar 3 "Unknow" 2 "Open" 1 "Secondary" 0 "Closed";
VAL_ 418 DDCU1_MirrorFoldSt 1 "Fold" 0 "Unfold";
VAL_ 418 DDCU1_FL_LockSt 1 "Unlock" 0 "Lock";
VAL_ 418 DDCU1_RL_LockSt 1 "Unlock" 0 "Lock";
VAL_ 419 PDCU1_FRDoorAjar 3 "Unknow" 2 "Open" 1 "Secondary" 0 "Closed";
VAL_ 419 PDCU1_RRDoorAjar 3 "Unknow" 2 "Open" 1 "Secondary" 0 "Closed";
VAL_ 419 PDCU1_FR_LockSt 1 "Unlock" 0 "Lock";
VAL_ 419 PDCU1_RR_LockSt 1 "Unlock" 0 "Lock";
VAL_ 468 CDCS5_ResetAllSetup 1 " Reset" 0 " No Action";
VAL_ 468 CDCS5_FactoryReset 1 " Reset" 0 " No Action";
VAL_ 482 BDCS4_Ftyre_Status 1 "Last Signal" 0 "Current Signal";
VAL_ 482 BDCS4_FLTyre_LearntSt 1 "Learnt" 0 "Not Learnt";
VAL_ 482 BDCS4_FLTyre_PressureWarn 3 "High Pressure" 2 "Low Pressure" 1 "Pre-warning" 0 "Normal Pressure";
VAL_ 482 BDCS4_FLTyre_TemperatureWarn 1 "High Temperature" 0 "Normal Temperature";
VAL_ 482 BDCS4_FLTyre_QucikLeak 1 "Quick Leak" 0 "No Quick Leak";
VAL_ 482 BDCS4_FLTyre_SensorFailure 1 "Sensoe Failure" 0 "No Sensoe Failure";
VAL_ 482 BDCS4_FLTyre_LowBattery 1 "Low Battery" 0 "Normal Battery";
VAL_ 482 BDCS4_FRTyre_LearntSt 1 "Learnt" 0 "Not Learnt";
VAL_ 482 BDCS4_FRTyre_PressureWarn 3 "High Pressure" 2 "Low Pressure" 1 "Pre-warning" 0 "Normal Pressure";
VAL_ 482 BDCS4_FRTyre_TemperatureWarn 1 "High Temperature" 0 "Normal Temperature";
VAL_ 482 BDCS4_FRTyre_QucikLeak 1 "Quick Leak" 0 "No Quick Leak";
VAL_ 482 BDCS4_FRTyre_SensorFailure 1 "Sensoe Failure" 0 "No Sensoe Failure";
VAL_ 482 BDCS4_FRTyre_LowBattery 1 "Low Battery" 0 "Normal Battery";
VAL_ 482 BDCS4_Testmode 1 "Test Mode" 0 "No Test Mode";
VAL_ 482 BDCS4_SystemFailure 3 "TPMS Not All" 2 "Pressure Abnormal" 1 "System Not OK" 0 "System OK";
VAL_ 484 BDCS5_Rtyre_Status 1 "Last Signal" 0 "Current Signal";
VAL_ 484 BDCS5_RLTyre_LearntSt 1 "Learnt" 0 "Not Learnt";
VAL_ 484 BDCS5_RLTyre_PressureWarn 3 "High Pressure" 2 "Low Pressure" 1 "Pre-warning" 0 "Normal Pressure";
VAL_ 484 BDCS5_RLTyre_TemperatureWarn 1 "High Temperature" 0 "Normal Temperature";
VAL_ 484 BDCS5_RLTyre_QucikLeak 1 "Quick Leak" 0 "No Quick Leak";
VAL_ 484 BDCS5_RLTyre_SensorFailure 1 "Sensoe Failure" 0 "No Sensoe Failure";
VAL_ 484 BDCS5_RLTyre_LowBattery 1 "Low Battery" 0 "Normal Battery";
VAL_ 484 BDCS5_RRTyre_LearntSt 1 "Learnt" 0 "Not Learnt";
VAL_ 484 BDCS5_RRTyre_PressureWarn 3 "High Pressure" 2 "Low Pressure" 1 "Pre-warning" 0 "Normal Pressure";
VAL_ 484 BDCS5_RRTyre_TemperatureWarn 1 "High Temperature" 0 "Normal Temperature";
VAL_ 484 BDCS5_RRTyre_QucikLeak 1 "Quick Leak" 0 "No Quick Leak";
VAL_ 484 BDCS5_RRTyre_SensorFailure 1 "Sensoe Failure" 0 "No Sensoe Failure";
VAL_ 484 BDCS5_RRTyre_LowBattery 1 "Low Battery" 0 "Normal Battery";
VAL_ 486 BDCS6_FrontWiperSts 7 "Reserved3" 6 "Reserved2" 5 "Reserved1" 4 "Reserved0" 3 "Reserved" 2 "High" 1 "Low" 0 "OFF";
VAL_ 486 BDCS6_FrontWiperParkPos 1 "Park" 0 "Not park";
VAL_ 486 BDCS6_DayNightMode 2 "Night mode" 1 "Day mode" 0 "Default";
VAL_ 756 BTM2_ConnectSts 3 "Smart key&Smart phone Connect" 2 "Smart phone Connect" 1 "Smart key Connect" 0 "Disconnect";
VAL_ 756 BTM2_Key_Position 5 "Inside（PS）" 4 "PE Trunk" 3 "PE Passenger Side" 2 "PE Drive Side" 1 "PE Front" 0 "Default";
VAL_ 243 BTM1_SecuritySts 3 "Reserved" 2 "In security  status" 1 "Not in Security status" 0 "Initial value";
VAL_ 243 BTM1_PhoneBatSts 1 "Abnormal" 0 "Normal ";
VAL_ 243 BTM1_RemoteIntModSel 2 "60s Return" 1 "60s  HangUp Phone" 0 "NotSelected";
VAL_ 243 BTM1_SelectSlotID 8 "slot 8" 7 "slot 7" 6 "slot 6" 5 "slot 5" 4 "slot 4" 3 "slot 3" 2 "slot 2" 1 "slot 1" 0 "No select";
VAL_ 243 BTM1_Retry 1 "Recover" 0 "Default";
VAL_ 243 BTM1_Fixslot 1 "OK" 0 "No request";
VAL_ 243 BTM1_ParkingReq 2 "Request  RPA" 1 "Request " 0 "No Request";
VAL_ 243 BTM1_Recover 1 "Recover" 0 "Default";
VAL_ 243 BTM1_parkingoutSlotType 3 "Oblique" 2 "Parallel" 1 "Vertical" 0 "Undecided";
VAL_ 243 BTM1_parkingoutSlot_Dire 3 "Front" 2 "Right" 1 "Left" 0 "No request";
VAL_ 243 BTM1_OptionalSlotType 3 "Oblique" 2 "Parallel" 1 "Vertical" 0 "Undecided";
VAL_ 243 BTM1_OptionalSlot_Dire 4 "Rear" 3 "Front" 2 "Right" 1 "Left" 0 "No request";
VAL_ 243 BTM1_FunctionMode 4 "liner ctrl" 3 "choice parking in" 2 "Parking out" 1 "Parking in" 0 "No action";
VAL_ 243 BTM1_RemoteParkReq 2 "Request off" 1 "Request on" 0 "No Request";
VAL_ 243 BTM1_Movectrl 2 "Retreat" 1 "Forward" 0 "No request";
VAL_ 498 BTM3_RKECmd 10 "ChargingflapClose" 9 "ChargingflapOpen" 8 "Reserved" 7 "APA Car press" 6 "Find Car" 5 "Trunk lock press" 4 "Long Lock" 3 "Long Unlock" 2 "Short Lock" 1 "Short Unlock" 0 "Default";
VAL_ 227 VCU5_ActGear 7 "Invalid" 5 "S" 4 "Drive" 3 "Neutral" 2 "Reverse" 1 "Park" 0 "Default";
VAL_ 227 VCU5_ActGearValid 1 "Valid" 0 "Invalid";
VAL_ 227 VCU5_READYLightSts 1 "Lamp ON" 0 "Lamp OFF";
VAL_ 227 VCU5_PwrTrainFailureLevel 3 "Failure Stop" 2 "Failure Limit" 1 "Failure Slight" 0 "No Failure";
VAL_ 227 VCU5_HVReady 1 "Ready" 0 "Not Ready";
VAL_ 227 VCU5_EmuEngineSts 1 "Engine Running" 0 "Engine Stop";
VAL_ 227 VCU5_AccelPositionValid 1 "Valid" 0 "Invalid";
VAL_ 227 VCU5_DriverOvertakeMode 1 "Active" 0 "Not Active";
VAL_ 227 VCU5_DriveMode_fb 4 "LAUNCH" 3 "CONFORM" 2 "SPORT" 1 "ECO" 0 "Default";
VAL_ 739 VCU3_EPBBackupCtrlActv 1 " PDCS接管控制EPB卡钳" 0 " PDCS未接管控制EPB卡钳";
VAL_ 739 VCU3_EPBBackupCtrlSts 7 "Fault" 6 " Reserved" 5 " Resrved" 4 "Releasing in progress卡钳释放中" 3 "Clamping in progress卡钳夹紧中" 2 "Clamped卡钳夹紧" 1 "Released卡钳释放" 0 "No Control未备份控制";
VAL_ 724 VCU4_CCS_Status 3 "Error" 2 "Active " 1 "Stand By" 0 "OFF";
VAL_ 251 VCU6_SystemWarnLightSts 1 "Lamp ON" 0 "Lamp OFF/Startup/Default";
VAL_ 251 VCU6_StrtgyGear 7 "Invalid" 5 "S" 4 "Drive" 3 "Neutral" 2 "Reverse" 1 "Park" 0 "Default";
VAL_ 264 VCU14_ACC_Ready 1 "Ready" 0 "Not ready";
VAL_ 264 VCU14_PAAvailable 1 "Not Available" 0 "Available";
VAL_ 264 VCU14_PAActive 1 "active" 0 "not active";
VAL_ 264 VCU14_PA_ParkingFnMd 3 "Cruising_AVP_Mode" 2 "Cruising_HPP/ISM_Mode" 1 " Parking Mode" 0 " Function Not Active";
VAL_ 264 VCU14_PA_FailCode 5 "Reserved" 4 "vehicle block（车辆无法移动）" 3 "Can not change gear" 2 "Driver interfervene" 1 "Over speed" 0 "Normal";
VAL_ 264 VCU14_Gear_PAAvailable 1 "Not Available" 0 "Available";
VAL_ 264 VCU14_Gear_PAActive 1 "active" 0 "not active";
VAL_ 264 VCU14_Gear_PACtrlAbortFeedback 4 "vehicle block（车辆无法移动）" 3 "Can not change gear" 2 "Driver intervene" 1 "Over speed" 0 "Normal";
VAL_ 264 VCU14_Gear_ErrorSts_M01 1 "Error" 0 "No Error";
VAL_ 264 VCU4_PA_DeceltorSts 1 "Not support" 0 "Support";
VAL_ 264 VCU4_PA_TargetTrqValueValidity 1 "Valid" 0 "Invalid";
VAL_ 438 TBOX2_AVMOnReq 2 "ON" 1 "OFF" 0 "No Request";
VAL_ 438 TBOX2_RemoteParkStartPressReqSts 1 "Available" 0 "Not Available ";
VAL_ 438 TBOX2_RemoteHPP 1 "Request" 0 "No Request";
VAL_ 438 TBOX2_AVMviewReq 8 "3D Right" 7 "3D Left" 6 "3D Rear " 5 "3D Front " 4 "2D Right" 3 "2D Left" 2 "2D Rear" 1 "2D Front" 0 "Not Active";
VAL_ 438 TBOX2_RemoteParkReq 1 "Request" 0 "No Request";
VAL_ 438 TBOX2_SecuritySts 3 "Reserved" 2 "In security  status" 1 "Not in Security status" 0 "Initial value";
VAL_ 438 TBOX2_ConnectSts 2 "Connection" 1 "Not connection" 0 "Initial value";
VAL_ 438 TBOX2_PhoneInCar 2 "Outside" 1 "Inside" 0 "Initial value";
VAL_ 438 TBOX2_RemoteParkAbortReq 1 "Request" 0 "No Request";
VAL_ 438 TBOX2_RemoteParkStartPressReq 1 "press" 0 "No press";
VAL_ 438 TBOX2_RemoteParkOutModSel 4 "Straight driving" 3 "Optional parking in" 2 "Parking out" 1 "Parking in" 0 "NotSelected";
VAL_ 438 TBOX2_PhoneBatSts 1 "Abnormal" 0 "Normal ";
VAL_ 438 TBOX2_RemoteIntModSel 2 "60s Return" 1 "60s  HangUp Phone" 0 "NotSelected";
VAL_ 438 TBOX2_RemoteSw 1 "Request" 0 "No Request";
VAL_ 438 TBOX2_RemoteCtrModSel 4 "Turn Right" 3 "Turn Left" 2 "Backward" 1 "Forward" 0 "NotSelected";
VAL_ 438 TBOX2_RemoteCtrSw 1 "Request" 0 "No Request";
VAL_ 438 TBOX2_PA_PauseRecover_Req 3 "reserved" 2 "Recover" 1 "Pause" 0 "No Request";
VAL_ 438 TBOX2_GMOnreq 3 "reserved" 2 "OFF " 1 "ON " 0 "No action ";
VAL_ 438 TBOX2_360viewReq 3 "reserved" 2 "OFF " 1 "ON " 0 "No action ";
VAL_ 438 TBOX2_360SpecView 4 "right view" 3 "left view" 2 "rear view" 1 "front view" 0 "No request";
VAL_ 438 TBOX2_RemoteVhpower 2 "request   OFF" 1 "request   start" 0 "Norequest";
VAL_ 438 TBOX2_NRPReq 3 "reserved" 2 "Request off" 1 "Request on" 0 "No Request";
VAL_ 438 TBOX2_SDMapReq 3 "reserved" 2 "Request off" 1 "Request on" 0 "No Request";
VAL_ 438 TBOX2_NNSSW 3 "reserved" 2 "Request off" 1 "Request on" 0 "No Request";
VAL_ 438 TBOX2_Remotepick 1 "request" 0 "Norequest";
VAL_ 438 TBOX2_NNSsuspend 3 "reserved" 2 "Recover" 1 "suspend" 0 "No Request";
VAL_ 438 TBOX2_HPA_ONPath_ID 0 "default";
VAL_ 438 TBOX2_HPA_PickPath_ID 0 "default";
VAL_ 670 BDCS10_AC_OutsideTempValid 1 "Valid" 0 "Invalid";
VAL_ 645 BDCS13_RLS_RQ_WiperSPD 3 "Not used" 2 "High Speed" 1 "Low Speed" 0 "No wiping";
VAL_ 600 BMS3_Charge_State 8 "Charge Achieved" 7 "Chager Fault" 6 "Charge Stop" 5 "Heat preservation" 4 "Heating while charging" 3 "Heating" 2 "Fast Charging" 1 "Slow Charging" 0 "Normal";
VAL_ 501 CDCS11_LKSSetspeed 0 "No action";
VAL_ 501 CDCS11_LDW_OnOffSet 3 "reserved" 2 "OFF" 1 "ON" 0 "No action";
VAL_ 501 CDCS11_LowSpeedBSDSw 3 "reserved" 2 "OFF " 1 "ON " 0 "No action ";
VAL_ 501 CDCS11_FCW_OnOffSet 3 "reserved" 2 "OFF " 1 "ON " 0 "No action ";
VAL_ 501 CDCS11_AEB_OnOffSet 3 "reserved" 2 "OFF " 1 "ON " 0 "No action ";
VAL_ 501 CDCS11_FCW_WarnTiming 3 "Early" 2 "Normal" 1 "Late" 0 "No action ";
VAL_ 501 CDCS11_FCTA_OnOffSet 3 "reserved" 2 "OFF " 1 "ON " 0 "No action ";
VAL_ 501 CDCS11_RCTA_OnOffSet 3 "reserved" 2 "OFF " 1 "ON " 0 "No action ";
VAL_ 501 CDCS11_RCW_OnOffSet 3 "reserved" 2 "OFF " 1 "ON " 0 "No action ";
VAL_ 501 CDCS11_DOW_OnOffSet 3 "reserved" 2 "OFF " 1 "ON " 0 "No action ";
VAL_ 501 CDCS11_IHBC_SysSwState 3 "reserved" 2 "OFF " 1 "ON " 0 "No action ";
VAL_ 501 CDCS11_LCA_OnOffSet 3 "reserved" 2 "OFF " 1 "ON " 0 "No action ";
VAL_ 501 CDCS11_TSR_OnOffSet 3 "reserved" 2 "OFF " 1 "ON " 0 "No action ";
VAL_ 501 CDCS11_AVM_3DRotate 3 "reserved" 2 "OFF " 1 "ON " 0 "No action ";
VAL_ 501 CDCS11_AVM_Turnlightstart 3 "reserved" 2 "OFF " 1 "ON " 0 "No action ";
VAL_ 501 CDCS11_AVM_Steeringstart 3 "reserved" 2 "OFF " 1 "ON " 0 "No action ";
VAL_ 501 CDCS11_AVM_Magnifiedview 3 "reserved" 2 "OFF " 1 "ON " 0 "No action ";
VAL_ 501 CDCS11_AVM_MODdetection 3 "reserved" 2 "OFF " 1 "ON " 0 "No action ";
VAL_ 501 CDCS11_GM_OnOffSet 3 "reserved" 2 "OFF " 1 "ON " 0 "No action ";
VAL_ 501 CDCS11_NNP_OnOffSet 3 "reserved" 2 "OFF " 1 "ON " 0 "No action ";
VAL_ 501 CDCS11_DCLCSysState 3 "reserved" 2 "OFF " 1 "ON " 0 "No action ";
VAL_ 501 CDCS11_ALCSysState 3 "reserved" 2 "OFF " 1 "ON " 0 "No action ";
VAL_ 501 CDCS11_DriveOffPossilbeswitch 3 "reserved" 2 "OFF " 1 "ON " 0 "No action ";
VAL_ 501 CDCS11_DriveOffinhibitionswitch 3 "reserved" 2 "OFF " 1 "ON " 0 "No action ";
VAL_ 501 CDCS11_ADAS_SndCtrlOnOff 3 "reserved" 2 "OFF " 1 "ON " 0 "No action ";
VAL_ 501 CDCS11_AVM_auxiliaryline 3 "reserved" 2 "OFF " 1 "ON " 0 "No action ";
VAL_ 501 CDCS11_AVM_Raderdisplay 3 "reserved" 2 "OFF " 1 "ON " 0 "No action ";
VAL_ 501 CDCS11_AVM_Transparentchassis 3 "reserved" 2 "OFF " 1 "ON " 0 "No action ";
VAL_ 501 CDCS11_VoiceMode 3 " Reserved" 2 " More Tips" 1 " Simple" 0 " no action";
VAL_ 501 CDCS11_NNP_Active_OnOffSet 3 " Reserved" 2 " ON（开启）" 1 " OFF（关闭）" 0 " No Action";
VAL_ 501 CDCS11_ALC_mode 2 " Automated LC" 1 " Voice allowed LC + Lever allowed LC" 0 " no action";
VAL_ 501 CDCS11_ADSDriving_mode 3 " Radical" 2 " Normal" 1 " Basic" 0 " No action";
VAL_ 501 CDCS11_TSR_OverspeedOnoffSet 3 "Reserved" 2 "OFF " 1 "ON " 0 "No Action ";
VAL_ 501 CDCS11_NNP_AutoOnOffSet 3 "Reserved" 2 "OFF " 1 "ON " 0 "No Action ";
VAL_ 501 CDCS11_SnCtrl_NNP_OnOff 2 "NNP OFF Request" 1 "NNP ON Request" 0 "No Request";
VAL_ 501 CDCS11_GM_VidedIn 3 "Reserved" 2 "OFF " 1 "ON " 0 "No Action ";
VAL_ 501 CDCS11_TSR_SLFOnOffSet 3 "Reserved" 2 "OFF " 1 "ON " 0 "No Action ";
VAL_ 501 CDCS11_APA_FunctionMode 9 "TAB on" 8 "ISM on" 7 "AVP on" 6 "HPP on" 5 "RPA on" 4 "FAPA on" 3 "choice parking in" 2 "Parking out" 1 "Parking in" 0 "No Request";
VAL_ 501 CDCS11_TrackreverseSW 2 "Track revers off" 1 "Track revers on" 0 "No Request";
VAL_ 501 CDCS11_SetPathwaySW 2 "off" 1 "on" 0 "No Request";
VAL_ 501 CDCS11_PA_changeLanguage 2 "English" 1 "Chinese" 0 "No Action";
VAL_ 501 CDCS11_LDP_OnOffSet 3 "reserved" 2 "OFF" 1 "ON" 0 "No action";
VAL_ 501 CDCS11_AVMSw 3 "Show Calibration" 2 "Show AVM" 1 "Hide" 0 "No Request";
VAL_ 501 CDCS11_tryHPP 1 "Request" 0 "No Request";
VAL_ 501 CDCS11_RPASw 3 "reserved" 2 "OFF " 1 "ON " 0 "No action ";
VAL_ 501 CDCS11_SetSw 1 "Request" 0 "No Request";
VAL_ 501 CDCS11_SoundCtrlSetReq 7 "request AVM off" 6 "request AVM on" 5 "request RPA off" 4 "request RPA on" 3 "Start APA Parking" 2 "request APA off" 1 "request APA on" 0 "No Request";
VAL_ 501 CDCS11_location_sw 1 "parking area" 0 "default";
VAL_ 501 CDCS11_Pathrefresh 1 "Request Path refresh" 0 "No Request";
VAL_ 501 CDCS11_HPAGuideSW 2 "off" 1 "on" 0 "No Request";
VAL_ 501 CDCS11_HPAPathwaytoCloudSW 2 "off" 1 "on" 0 "No Request";
VAL_ 501 CDCS11_PathlearningSw 2 "Request Path learning off" 1 "Request Path learning on" 0 "No Request";
VAL_ 501 CDCS11_PA_screenMd 9 "TAB" 8 "ISM " 7 "AVP " 6 "HPP " 5 "RPA " 4 "FAPA " 3 "AVM" 2 "RVC" 1 "PDC" 0 "No Request";
VAL_ 501 CDCS11_PASw 3 " Reserve" 2 "Request PA off" 1 "Request PA on" 0 "No Request";
VAL_ 501 CDCS11_PA_Recover 1 "Recover" 0 "Default";
VAL_ 501 CDCS_Lcsndrequest 3 "Request inactive" 2 "Request  active right" 1 "Request active left" 0 "No action";
VAL_ 501 CDCS_Lcsndconfirm 2 "Confirm inactive" 1 "Confirm active" 0 "No action";
VAL_ 501 CDCS_SpdAdaptComfirm 2 "No" 1 "OK" 0 "No Action";
VAL_ 501 CDCS_PayModeConfirm 2 "No" 1 "OK" 0 "No Action";
VAL_ 501 CDCS11_SelectSlotID 8 "slot 8" 7 "slot 7" 6 "slot 6" 5 "slot 5" 4 "slot 4" 3 "slot 3" 2 "slot 2" 1 "slot 1" 0 "No Action";
VAL_ 501 CDCS11_ParkingInReq 2 "Request  RPA" 1 "Request " 0 "No Request";
VAL_ 501 CDCS11_ParkingOutReq 2 "Request  RPA" 1 "Request " 0 "No Request";
VAL_ 501 CDCS11_AVM_ViewMode 2 "Request 3D Mode" 1 "Request 2D Mode" 0 "No Action";
VAL_ 501 CDCS11_RPA_FunctionMode 3 "choice parking in" 2 "Parking out" 1 "Parking in" 0 "No action ";
VAL_ 501 CDCS11_AVM_VideoOutputFail 1 "Fail" 0 "No fail";
VAL_ 501 CDCS11_AVM_Initialization 1 "Request Initialize" 0 "No Request";
VAL_ 501 CDCS11_AVM_bodySync 3 "reserved" 2 "OFF " 1 "ON " 0 "No action ";
VAL_ 501 CDCS11_AVM_SpeView 2 "Rear wide view" 1 "Front wide view" 0 "No Request";
VAL_ 501 CDCS11_AVM_licenseplateabbr 34 "台" 33 "澳" 32 "港" 31 "新" 30 "宁" 29 "蒙" 28 "桂" 27 "藏" 26 "青" 25 "甘" 24 "陕" 23 "云" 22 "贵" 21 "川" 20 "琼" 19 "粤" 18 "湘" 17 "鄂" 16 "豫" 15 "鲁" 14 "赣" 13 "闽" 12 "皖" 11 "浙" 10 "苏" 9 "黑" 8 "吉" 7 "辽" 6 "晋" 5 "冀" 4 "渝" 3 "沪" 2 "津" 1 "京" 0 "无";
VAL_ 501 CDCS11_AVM_licenseplateArea 26 "Z" 25 "Y" 24 "X" 23 "W" 22 "V" 21 "U" 20 "T" 19 "S" 18 "R" 17 "Q" 16 "P" 15 "O" 14 "N" 13 "M" 12 "L" 11 "K" 10 "J" 9 "I" 8 "H" 7 "G" 6 "F" 5 "E" 4 "D" 3 "C" 2 "B" 1 "A" 0 "Nothing";
VAL_ 501 CDCS11_AVM_StartMode 7 " Reserved" 6 " Reserved" 5 " Reserved" 4 " Reserved" 3 "24 h" 2 "12 h" 1 "0 h" 0 "No Action";
VAL_ 501 CDCS11_AVM_LicensePlateNO1 41 "9" 40 "8" 39 "7" 38 "6" 37 "5" 36 "4" 35 "3" 34 "2" 33 "1" 32 "0" 26 "Z" 25 "Y" 24 "X" 23 "W" 22 "V" 21 "U" 20 "T" 19 "S" 18 "R" 17 "Q" 16 "P" 15 "O" 14 "N" 13 "M" 12 "L" 11 "K" 10 "J" 9 "I" 8 "H" 7 "G" 6 "F" 5 "E" 4 "D" 3 "C" 2 "B" 1 "A" 0 "Nothing";
VAL_ 501 CDCS11_ELK_OnOffSet 3 "reserved" 2 "OFF" 1 "ON" 0 "No action";
VAL_ 501 CDCS11_AVM_LicensePlateNO2 41 "9" 40 "8" 39 "7" 38 "6" 37 "5" 36 "4" 35 "3" 34 "2" 33 "1" 32 "0" 26 "Z" 25 "Y" 24 "X" 23 "W" 22 "V" 21 "U" 20 "T" 19 "S" 18 "R" 17 "Q" 16 "P" 15 "O" 14 "N" 13 "M" 12 "L" 11 "K" 10 "J" 9 "I" 8 "H" 7 "G" 6 "F" 5 "E" 4 "D" 3 "C" 2 "B" 1 "A" 0 "Nothing";
VAL_ 501 CDCS11_AVM_LicensePlateNO3 41 "9" 40 "8" 39 "7" 38 "6" 37 "5" 36 "4" 35 "3" 34 "2" 33 "1" 32 "0" 26 "Z" 25 "Y" 24 "X" 23 "W" 22 "V" 21 "U" 20 "T" 19 "S" 18 "R" 17 "Q" 16 "P" 15 "O" 14 "N" 13 "M" 12 "L" 11 "K" 10 "J" 9 "I" 8 "H" 7 "G" 6 "F" 5 "E" 4 "D" 3 "C" 2 "B" 1 "A" 0 "Nothing";
VAL_ 501 CDCS11_DCWposition 3 "level3" 2 " level2  " 1 "level1   " 0 "off ";
VAL_ 501 CDCS11_AVM_LicensePlateNO4 41 "9" 40 "8" 39 "7" 38 "6" 37 "5" 36 "4" 35 "3" 34 "2" 33 "1" 32 "0" 26 "Z" 25 "Y" 24 "X" 23 "W" 22 "V" 21 "U" 20 "T" 19 "S" 18 "R" 17 "Q" 16 "P" 15 "O" 14 "N" 13 "M" 12 "L" 11 "K" 10 "J" 9 "I" 8 "H" 7 "G" 6 "F" 5 "E" 4 "D" 3 "C" 2 "B" 1 "A" 0 "Nothing";
VAL_ 501 CDCS11_FindCarAvmReq 3 "Reserved" 2 "AVM Finished" 1 "AVM Request" 0 "No Action";
VAL_ 501 CDCS11_AVM_LicensePlateNO5 41 "9" 40 "8" 39 "7" 38 "6" 37 "5" 36 "4" 35 "3" 34 "2" 33 "1" 32 "0" 26 "Z" 25 "Y" 24 "X" 23 "W" 22 "V" 21 "U" 20 "T" 19 "S" 18 "R" 17 "Q" 16 "P" 15 "O" 14 "N" 13 "M" 12 "L" 11 "K" 10 "J" 9 "I" 8 "H" 7 "G" 6 "F" 5 "E" 4 "D" 3 "C" 2 "B" 1 "A" 0 "Nothing";
VAL_ 501 CDCS11_AVM_LicensePlateNO6 41 "9" 40 "8" 39 "7" 38 "6" 37 "5" 36 "4" 35 "3" 34 "2" 33 "1" 32 "0" 26 "Z" 25 "Y" 24 "X" 23 "W" 22 "V" 21 "U" 20 "T" 19 "S" 18 "R" 17 "Q" 16 "P" 15 "O" 14 "N" 13 "M" 12 "L" 11 "K" 10 "J" 9 "I" 8 "H" 7 "G" 6 "F" 5 "E" 4 "D" 3 "C" 2 "B" 1 "A" 0 "Nothing";
VAL_ 501 CDCS11_AVM_LicensePlateNO7 41 "9" 40 "8" 39 "7" 38 "6" 37 "5" 36 "4" 35 "3" 34 "2" 33 "1" 32 "0" 26 "Z" 25 "Y" 24 "X" 23 "W" 22 "V" 21 "U" 20 "T" 19 "S" 18 "R" 17 "Q" 16 "P" 15 "O" 14 "N" 13 "M" 12 "L" 11 "K" 10 "J" 9 "I" 8 "H" 7 "G" 6 "F" 5 "E" 4 "D" 3 "C" 2 "B" 1 "A" 0 "Nothing";
VAL_ 501 CDCS11_AVM_LicensePlateNO8 41 "9" 40 "8" 39 "7" 38 "6" 37 "5" 36 "4" 35 "3" 34 "2" 33 "1" 32 "0" 26 "Z" 25 "Y" 24 "X" 23 "W" 22 "V" 21 "U" 20 "T" 19 "S" 18 "R" 17 "Q" 16 "P" 15 "O" 14 "N" 13 "M" 12 "L" 11 "K" 10 "J" 9 "I" 8 "H" 7 "G" 6 "F" 5 "E" 4 "D" 3 "C" 2 "B" 1 "A" 0 "Nothing";
VAL_ 501 CDCS11_AVM_Powertype 3 "PHEV" 2 "Traditional" 1 "EV" 0 "No Action";
VAL_ 501 CDCS11_AVM_Diaphaneity 11 "100%" 10 "90%" 9 "80%" 8 "70%" 7 "60%" 6 "50%" 5 "40%" 4 "30%" 3 "20%" 2 "10%" 1 "0" 0 "No Action";
VAL_ 501 CDCS11_AVM_DiaphaneitySw 1 "Request" 0 "No Request";
VAL_ 501 CDCS11_MOD_Sound_Sw 3 "Reserved" 2 "Off（关闭）" 1 "On（开启）" 0 "No Action";
VAL_ 501 CDCS11_MOD_BSD_Sw 3 "Reserved" 2 "Off（关闭）" 1 "On（开启）" 0 "No Action";
VAL_ 501 CDCS11_PA_FRS_OnOffSet 3 "Reserved" 2 "Off（关闭）" 1 "On（开启）" 0 "No Action";
VAL_ 501 CDCS11_PA_3D_OnOffSet 3 "Reserved" 2 "Off（关闭）" 1 "On（开启）" 0 "No Action";
VAL_ 501 CDCS11_PA_measure_OnOffSet 3 "Reserved" 2 "Off（关闭）" 1 "On（开启）" 0 "No Action";
VAL_ 501 CDCS11_MODSw 3 "Reserved" 2 "Off（关闭）" 1 "On（开启）" 0 "No Action";
VAL_ 501 CDCS11_VoiceNotifFrequency_mode 3 "Detailed" 2 "Simple" 1 "Basic" 0 "Not defined   ";
VAL_ 501 CDCS11_ACCOnOffSet 3 "Reserved" 2 "Off（关闭）" 1 "On（开启）" 0 "No Action";
VAL_ 501 CDCS11_HPASw 3 "Reserved" 2 "Off（关闭）" 1 "On（开启）" 0 "No Action";
VAL_ 501 CDCS11_DeleteMapID 10 " Map 10" 9 "Map 9" 8 "Map 8" 7 "Map 7" 6 "Map 6" 5 "Map 5" 4 "Map 4" 3 "Map 3" 2 "Map 2" 1 "Map 1" 0 "No Action";
VAL_ 501 CDCS11_UploadMapID 10 " Map 10" 9 "Map 9" 8 "Map 8" 7 "Map 7" 6 "Map 6" 5 "Map 5" 4 "Map 4" 3 "Map 3" 2 "Map 2" 1 "Map 1" 0 "No Action";
VAL_ 501 CDCS11_HPAActiveConfirm 1 "Confirm" 0 "No Confirm";
VAL_ 501 CDCS11_HPApreparkingSw 2 "off" 1 "on" 0 "No Action";
VAL_ 501 CDCS11_HPAPathwaytoCloud_WorkSts 7 "Reserve" 6 "Reserve" 5 "Reserve" 4 "Uploading error" 3 "Uploading" 2 "Uploaded" 1 "To be uploaded" 0 "No Action";
VAL_ 501 CDCS11_PA_Select_ID 0 "default";
VAL_ 501 CDCS11_learnpath_St 2 "complete and upload" 1 "complete " 0 "default ";
VAL_ 501 CDCS11_ParkingoutSlot_Type 3 "Oblique" 2 "Parallel" 1 "Vertical" 0 "Undecided";
VAL_ 501 CDCS11_ParkingoutSlot_Dire 3 "Front" 2 "Right" 1 "Left" 0 "No request";
VAL_ 501 CDCS11_OptionalSlot_Type 3 "Oblique" 2 "Parallel" 1 "Vertical" 0 "Undecided";
VAL_ 501 CDCS11_OptionalSlot_Dire 4 "Rear" 3 "Front" 2 "Right" 1 "Left" 0 "No request";
VAL_ 501 CDCS11_OptionalSlotCoor_P0_X 0 "No Action";
VAL_ 501 CDCS11_OptionalSlotCoor_P0_Y 0 "No Action";
VAL_ 501 CDCS11_OptionalSlotCoor_P1_X 0 "No Action";
VAL_ 501 CDCS11_OptionalSlotCoor_P1_Y 0 "No Action";
VAL_ 501 CDCS11_OptionalSlotCoor_P2_X 0 "No Action";
VAL_ 501 CDCS11_OptionalSlotCoor_P2_Y 0 "No Action";
VAL_ 501 CDCS11_OptionalSlotCoor_P3_X 0 "No Action";
VAL_ 501 CDCS11_OptionalSlotCoor_P3_Y 0 "No Action";
VAL_ 347 SWSM_A_CruiseDistance_Add 1 " Press" 0 "No Press ";
VAL_ 347 SWSM_A_CruiseDistance_Minus 1 " Press" 0 "No Press ";
VAL_ 347 SWSM_A_CruiseSpeed_Add 2 " Fast Slider" 1 " Slowly Slider" 0 "No Action";
VAL_ 347 SWSM_A_CruiseSpeed_Minus 2 " Fast Slider" 1 " Slowly Slider" 0 "No Action";
VAL_ 347 SWSM_A_SpeechInputSw 2 " Long Press" 1 " Short Press" 0 "No Press ";
VAL_ 347 Region_A_SwError 1 " Error" 0 "No Error";
VAL_ 347 SWSM_A_CD_Add_Overtime 1 "Stucked _>60s" 0 "No Stuck";
VAL_ 347 SWSM_A_CD_Minus_Overtime 1 "Stucked _>60s" 0 "No Stuck";
VAL_ 443 CDCS13_SwSmMode 3 "Reserved" 2 "BDCS-外后视镜" 1 "ARHUD" 0 "Default";
VAL_ 442 CDCS10_WorK_status 3 "Reserved" 2 "Error" 1 "Ready" 0 "NotReady";
VAL_ 707 EDU4_PwrModeSts 3 " 余热回收" 2 " 热泵吸热" 1 " 主动冷却" 0 " 关闭";
VAL_ 707 EDU4_MotCoolgLoopSts 3 "Failure" 2 "Warning" 1 "Normal" 0 "OFF";
VAL_ 469 EDU5_OperMod 15 "ready to sleep" 7 "Reserved" 6 "Reserved" 5 "ReadyToPowerDown" 4 "Failure" 3 "afterrun" 2 "HV Active" 1 "Standby" 0 "Initializing";
VAL_ 769 ADCS_MDC1_ThmPostRun 1 "Active" 0 "Inactive";
VAL_ 230 RCU1_BrakePedalApplied 1 "press( 制动踏板被踩下)" 0 "no press(( 制动踏板未被踩下)";
VAL_ 230 RCU1_BrakePedalAppliedV 1 "Valid(有效)" 0 "Invalid(无效)";
VAL_ 230 RCU1_BBS_ActiveSta 1 "Active" 0 "Inactive";
VAL_ 230 RCU1_BrakPedalDisp_Q 1 "Valid(有效)" 0 "Invalid(无效)";
VAL_ 230 RCU1_TrvSnsCalSts 1 "Yes" 0 "No";
VAL_ 230 RCU1_BrkPedVal_vaild 3 "PTS2 Suspect state" 2 "PTS2 Plausibility error" 1 "PTS2 Valid" 0 "PTS2 Invalid";
VAL_ 230 RCU1_BBSFail 1 "fail" 0 "no fail";
VAL_ 230 RCU1_FailedState 6 "fault level 6" 5 "fault level 5" 4 "fault level 4" 3 "fault level 3" 2 "fault level 2" 1 "fault level 1" 0 "no fault";
VAL_ 311 RCU2_FLWhlPulCntValid 1 "Valid(有效)" 0 "Invalid(无效)";
VAL_ 311 RCU2_FRWhlPulCntValid 1 "Valid(有效)" 0 "Invalid(无效)";
VAL_ 312 RCU3_VehicleSpdValid 1 "Valid(有效)" 0 "Invalid(无效)";
VAL_ 312 RCU3_MasterCylPressureInvalid 1 "Valid(有效)" 0 "Invalid(无效)";
VAL_ 313 RCU4_FLWhlVelocityValid 1 "Valid(有效)" 0 "Invalid(无效)";
VAL_ 313 RCU4_FRWhlVelocityValid 1 "Valid(有效)" 0 "Invalid(无效)";
VAL_ 313 RCU4_FRWhlDir 3 "Error identifier" 2 "Backward direction" 1 "Forward direction" 0 "Unknown or stanstill";
VAL_ 313 RCU4_FLWhlDir 3 "Error identifier" 2 "Backward direction" 1 "Forward direction" 0 "Unknown or stanstill";
VAL_ 313 RCU4_RLWhlDir 3 "Error identifier" 2 "Backward direction" 1 "Forward direction" 0 "Unknown or stanstill";
VAL_ 313 RCU4_RRWhlDir 3 "Error identifier" 2 "Backward direction" 1 "Forward direction" 0 "Unknown or stanstill";
VAL_ 313 RCU4_RLWhlVelocityValid 1 "Valid(有效)" 0 "Invalid(无效)";
VAL_ 313 RCU4_RRWhlVelocityValid 1 "Valid(有效)" 0 "Invalid(无效)";
VAL_ 313 RCU4_RLWhlPulCntValid 1 "Valid(有效)" 0 "Invalid(无效)";
VAL_ 313 RCU4_RRWhlPulCntValid 1 "Valid(有效)" 0 "Invalid(无效)";
VAL_ 317 RCU5_BrakeDiscTempSts 1 "Temperature too high;" 0 "Not high;";
VAL_ 317 RCU5_JerkActive 1 "available" 0 "Not available";
VAL_ 317 RCU5_Jerkfail 1 "fail" 0 "no fail";
VAL_ 317 RCU5_ACC_ReqLim 3 "Deceleration Limit" 2 "Reserved" 1 "Reserved" 0 "No request";
VAL_ 317 RCU5_ACC_Enable 3 "AEB Communication Error" 2 "Permanently not Available" 1 "Temporarily not Available" 0 "Available";
VAL_ 317 RCU5_AEB_Enable 3 "AEB Communication Error" 2 "Permanently not Available" 1 "Temporarily not Available" 0 "Available";
VAL_ 317 RCU5_DriverOverride 3 "Reserved" 2 "DecelOverride" 1 "AccelOverride" 0 "No override";
VAL_ 314 RCU6_EPB_ActuatorSt_R 7 "reversed" 6 "Hold" 5 "Unknown" 4 "Completely Released" 3 "Brake Applying" 2 "Brake Released" 1 "Brake Applied" 0 "Brake Releasing";
VAL_ 314 RCU6_EPB_ActuatorSt_L 7 "reversed" 6 "Hold" 5 "Unknown" 4 "Completely Released" 3 "Brake Applying" 2 "Brake Released" 1 "Brake Applied" 0 "Brake Releasing";
VAL_ 314 RCU6_EPB_DisplayMsgID 4 "after roll reapply,still roll" 3 "slpoe too steep" 2 "push brake pedal" 1 "close door（主驾门）" 0 "off";
VAL_ 314 RCU6_EPBAvailable 6 "EPB  failure" 5 "EPB Permanently Not Available" 4 "EPB Temporarily Not Available" 3 "EPB Diagnostic" 2 "EPB Initialization State" 1 "EPB No failure" 0 "Not valid";
VAL_ 314 RCU6_EPBStatus 7 "Not Initialized (NEW)" 6 "Full Released完全释放" 5 "Dynamic braking via EPB动态驻车" 4 "Releasing in progress卡钳释放中" 3 "Clamping in progress卡钳夹紧中" 2 "Clamped卡钳夹紧" 1 "Released卡钳释放" 0 "Unknown未知";
VAL_ 314 RCU6_EPBCruiseCtrlCancelReq 1 "Cruise Control Cancel Requested" 0 "No request";
VAL_ 314 RCU6_EPBSysBrkLightsReq 1 "Request to turn on" 0 "No request";
VAL_ 314 RCU6_EPBStatusLampReq 3 "Reserved" 2 "Flash Rate 1 Indication" 1 "Continuous Indication" 0 "No Indication";
VAL_ 314 RCU6_EPBWarnLampReq 3 "Reserved" 2 "Flash Rate 1 Indication" 1 "Continuous Indication" 0 "No Indication";
VAL_ 314 RCU6_EPBClusterDispMSG 6 "Press down the accelerator pedal" 5 "Park Brake Released" 4 "Park Brake Set" 3 "Service Park Brake" 2 "Release Park Brake Switch" 1 "Press Brake Pedal to Release Park Brake" 0 "Off";
VAL_ 315 RCU7_TCSActive 1 "Active" 0 "Inactive";
VAL_ 315 RCU7_TCSDisable 1 "TCS Function Disabled" 0 "TCS Function Enabled";
VAL_ 315 RCU7_TCSFail 1 "TRUE" 0 "FALSE";
VAL_ 315 RCU7_AVHDispMSG 3 "AUTO HOLD cannot be activated Close Door" 2 "Press Brake Pedal to Release AUTO HOLD" 1 "AUTO HOLD to be deactivated Press Brake Pedal" 0 "AVH is off";
VAL_ 315 RCU7_AVHLampReq 3 "AVH READY" 2 "AVH ACTIVE(Green)" 1 "AVH failure(Yellow)" 0 "AVH Off ";
VAL_ 315 RCU7_AVHEnabled 1 "Enabled" 0 "Disabled";
VAL_ 315 RCU7_HSAActive 1 "Active" 0 "Inactive";
VAL_ 315 RCU7_HSAFail 1 "Fail" 0 "Not fail";
VAL_ 315 RCU7_BrkLightReq 1 "Requested" 0 "No Request";
VAL_ 315 RCU7_ESSActiveReq 2 "ESS function defective" 1 "Requested" 0 "No Request";
VAL_ 315 RCU7_ABSActive 1 "Active" 0 "Inactive";
VAL_ 315 RCU7_ABSFail 1 "fail" 0 "no fail";
VAL_ 315 RCU7_ESCFail 1 "Active" 0 "Inactive";
VAL_ 315 RCU7_ESCActive 1 "Active" 0 "Inactive";
VAL_ 315 RCU7_BrakeWarningLamp 2 " IDB  BrakeWarning YellowLamp ON" 1 " IDB  BrakeWarning RedLamp ON" 0 " IDB BrakeWarning Lamp OFF";
VAL_ 316 RCU8_BrakeActive 1 "Active" 0 "No Active";
VAL_ 318 RCU9_PA_CtrlAbortFeedback 3 "Failure" 2 "EPB intervened" 1 "over speed" 0 " narmal";
VAL_ 318 RCU9_PA_ParkingBrkMdSeln 2 "Function Not Active" 1 " Standstill (vehicle has been stopped)" 0 " Not standstill ";
VAL_ 318 RCU9_PA_ParkingFnMd 6 " TAB Mode" 5 " ISM Mode" 4 " AVP Mode" 3 " HPP Mode" 2 " RPA Mode" 1 " PA Mode" 0 " Function Not Active";
VAL_ 318 RCU9_PA_ParkingAvailable 1 "Not Available" 0 "Available";
VAL_ 318 RCU9_PASts 1 "Failure" 0 "Normal";
VAL_ 318 RCU9_PAStandStill 1 "standstill" 0 "not standstill";
VAL_ 318 RCU_9_PA_RdnyBrkModeActv 1 "Active" 0 "Inactive";
VAL_ 765 HNS1_FaultSts 1 " Fault" 0 " No Fault";
VAL_ 765 HNS1_VoltageSts 4 "Battery Undervoltage" 3 "Battery Overvoltage" 2 "DCDC Undervoltage" 1 " DCDC Overvoltage" 0 " No Fault";
VAL_ 765 HNS1_CurrentSts 2 "Battery OverCurrent" 1 " DCDC OverCurrent " 0 " No Fault";
VAL_ 765 HNS1_MainSwSts 3 "Invalid" 2 " SelfCheck" 1 " Open" 0 " Closed";
VAL_ 765 HNS1_DCDCVol_status 1 " Invalid" 0 " Valid";
VAL_ 765 HNS1_BatVol_status 1 " Invalid" 0 " Valid";
VAL_ 765 HNS1_DCDCCur_status 1 " Invalid" 0 " Valid";
VAL_ 765 HNS1_BatCur_status 1 " Invalid" 0 " Valid";
VAL_ 310 ADCS12_FCWWarnAudioplay 1 "Warning Play" 0 "None";
VAL_ 310 ADCS12_RCTAWarnAudioplay 2 "Right Warning play" 1 "Left Warning play" 0 "None";
VAL_ 310 ADCS12_FCTAWarnAudioplay 2 "Right Warning play" 1 "Left Warning play" 0 "None";
VAL_ 310 ADCS12_SpeedWarnAudioplay 1 "Warning Play" 0 "None";
VAL_ 310 ADCS12_DOWWarnAudioplay 1 "Warning Play" 0 "None";
VAL_ 310 ADCS12_DCLCAudioplay 3 "Cancel broadcast" 2 "right broadcast" 1 "Left broadcast" 0 "None";
VAL_ 310 ADCS12_PilotAudioPlay 3 "Pilot cancel" 2 "Pilot resumed" 1 "Pilot Override" 0 "None";
VAL_ 310 ADCS12_HandOffAudioplay 3 "EM takeover broadcast" 2 "takeover braodcast" 1 "Handsoff warning broadcast" 0 "None";
VAL_ 310 ADCS12_NNPCancelAudioPlay 1 "NNP Cancel play" 0 "None";
VAL_ 310 ADCS12_RCWWarnAudioplay 1 "Warning Play" 0 "None";
VAL_ 310 ADCS12_MRMAudioPlay 3 "Finish broadcast" 2 "EM Warning broadcast" 1 "MRM Warning broadcast" 0 "None";
VAL_ 310 ADCS12_NNP_ResumeAudioplay 2 "Resume reminder" 1 "Suspended" 0 "None";
VAL_ 310 ADCS12_Lcsndrequest 1 "Request inactive" 0 "Request active";
VAL_ 310 ADCS12_Lcsndrconfirm 1 "Confirm inactive" 0 "Confirm active";
VAL_ 310 ADCS12_longitudDisableInfo 9 "无法开启" 8 "底盘(预留)" 7 "EPB拉起" 6 "前舱盖" 5 "后备箱" 4 "door open" 3 "seatbelt untied" 2 "braking" 1 "speed not satisfied" 0 "None";
VAL_ 310 ADCS12_DriveOffBroadcast 1 "Requested" 0 "No Request";
VAL_ 310 ADCS12_EyeOffBroadcast 1 " Broadcast request" 0 " None";
VAL_ 310 ADCS12_SpeedAdaptComfirm 1 "request" 0 "No request";
VAL_ 310 ADCS12_PayModeConfirm 1 "Request" 0 "No request";
VAL_ 310 ADCS12_longitudCtrlSysInfo 11 "override提示" 10 "ACC lost arbitration" 9 "ACC is cancelled" 8 "Display HDC Request" 7 "Display Takeover Request" 6 "Display Disable to engage ACC" 5 "Display ACC disengaged" 4 "Display Available to resume acceleration control" 3 "Display Object disappeared" 2 "Display  ACC fault unavaliable " 1 "Display ACC on" 0 "Default";
VAL_ 310 ADCS12_NPilotSysInfo 15 "不在ODD内" 14 " GPS信号差" 13 "无法开启 " 12 "底盘" 11 "EPB拉起" 10 "前舱盖" 9 "后备箱" 8 "door open" 7 "reservedseatbelt untied" 6 "Disable to engage NPilot Cuz lane" 5 "Disable to engage NPilot Cuz braking" 4 "Disable to engage NPilot Cuz speed" 3 "Disable to engage NPilot cuz fault" 2 "NPilot Off " 1 "NPilot On" 0 "Disable to engage NPilot";
VAL_ 310 ADCS12_ADAS_DriveOffinhibition 1 "Requested" 0 "No Request";
VAL_ 310 ADCS12_P2N_State_Reminder 7 "NNP unable to active by sound" 6 "degrad to Pilot Reminder" 5 "NNP Pre-degrade Reminder II" 4 "NNP Pre-degrade Reminder" 3 "NNP Active Reminder" 2 "Pilot pre-upgrade Reminder II" 1 "Pilot Pre-upgrade Reminder" 0 "No";
VAL_ 310 ADCS12_NNP_State_Reminder 7 " NNP_fault reminder" 6 " NNP dropped-out" 5 " NNP Pre-cancel Reminder III" 4 " NNP Pre-cancel Reminder II" 3 " NNP Pre-cancel Reminder" 2 " NNP activated Reminder" 1 " NNP ready to activate Reminder" 0 " No";
VAL_ 310 ADCS12_NNP_LightRemind 1 " Light not off" 0 " Not Used";
VAL_ 310 ADCS12_LCAudioPlay 2 "Right LaneChange active" 1 "Left Lane Change active" 0 "None";
VAL_ 310 ADCS12_NNP_Scenarios_AudioPlay 11 " Best Path Tracing" 10 " Oncoming Vehicle" 9 " Oversized Vehicle One Side" 8 " Oversized Vehicle Both Side" 7 " SpeedAdapt" 6 " Narrow Lane" 5 " Lane  Reduce" 4 " PayModeConfirm" 3 " Pedastrian Walk" 2 "  TFL" 1 "  Static Obstacle" 0 "None";
VAL_ 310 ADCS12_LaneChangePendingAlert 1 " Request" 0 " No Request";
VAL_ 310 ADCS12_NNP_RINO 7 " Exit Missed" 6 " Navigation Task Take Over Request" 5 " Ramp Out DONE" 4 " Ramp Out Start" 3 " Ramp Out Heavy Traffic" 2 " Ramp In DONE" 1 " Ramp In Start" 0 " No Request";
VAL_ 1543 ADCS_RepeatMessageRequest 1 "Repeat message request" 0 "No repeat message request";
VAL_ 1543 ADCS_ActiveWakeup 1 "Wakeup" 0 "No wakeup ";
VAL_ 1543 ADCS_WakeUp_KL15 1 "KL15 ON Wakeup" 0 "No Request ";
VAL_ 1543 ADCS_WakeUp_NM 1 "NM Wakeup" 0 "No Request ";
VAL_ 1543 ADCS_WakeUp_GM 1 "Wakeup Requrst" 0 "No Request ";
VAL_ 1543 ADCS_WakeUpReason4 1 "Wakeup Requrst" 0 "No Request ";
VAL_ 1543 ADCS_WakeUpReason5 1 "Wakeup Requrst" 0 "No Request ";
VAL_ 1543 ADCS_WakeUpReason6 1 "Wakeup Requrst" 0 "No Request ";
VAL_ 1543 ADCS_WakeUpReason7 1 "Wakeup Requrst" 0 "No Request ";
VAL_ 1543 ADCS_WakeUpReason8 1 "Wakeup Requrst" 0 "No Request ";
VAL_ 1543 ADCS_RepeatFromSleep 1 "occur;" 0 "not occur;";
VAL_ 1543 ADCS_RepeatFromPrepare 1 "occur;" 0 "not occur;";
VAL_ 1543 ADCS_RepeatFromNormal 1 "occur;" 0 "not occur;";
VAL_ 1543 ADCS_RepeatFromReady 1 "occur;" 0 "not occur;";
VAL_ 1543 ADCS_NormalFromRepeat 1 "occur;" 0 "not occur;";
VAL_ 1543 ADCS_NormalFromReady 1 "occur;" 0 "not occur;";
VAL_ 1543 ADCS_RNM_DOW 1 "DOW" 0 "default ";
VAL_ 1543 ADCS_RNM_GM 1 "GM" 0 "default ";
VAL_ 1543 ADCS_RNM_ICS 1 "ICS" 0 "default ";
VAL_ 1543 ADCS_RNM_RPA 1 "RPA" 0 "default ";
VAL_ 1543 ADCS_RNM_ISM 1 "ISM" 0 "default ";
